VERSION "j1939-2025-03-v2.4-light"

NS_ :

BS_:

BU_:

BO_ 2163223550 CN: 8 Vector__XXX
 SG_ CrashChecksum : 60|4@1+ (1,0) [0|15] "count" Vector__XXX
 SG_ CrashCounter : 56|4@1+ (1,0) [0|15] "count" Vector__XXX
 SG_ CrashType : 0|5@1+ (1,0) [0|31] "" Vector__XXX

BO_ 2230333950 WAND: 8 Vector__XXX
 SG_ WandAngle : 0|16@1+ (0.002,-64) [-64|64.51] "deg" Vector__XXX
 SG_ WandSensorFigureOfMerit : 16|2@1+ (1,0) [0|3] "" Vector__XXX

BO_ 2230334206 LDISP: 8 Vector__XXX
 SG_ MeasuredLinearDisplacement : 0|16@1+ (0.1,0) [0|6425.5] "mm" Vector__XXX
 SG_ LnrDsplmntSnsrSnsrFgrOfMrt : 16|2@1+ (1,0) [0|3] "" Vector__XXX

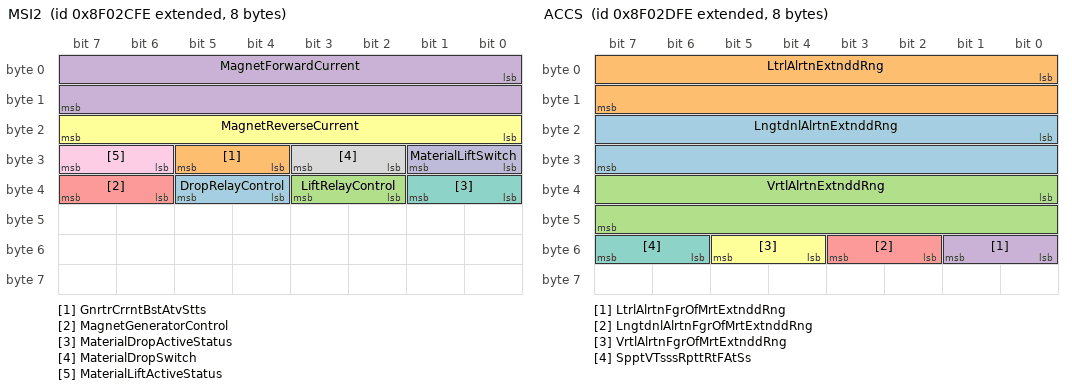
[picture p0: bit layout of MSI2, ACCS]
BO_ 2297441534 MSI2: 8 Vector__XXX
 SG_ DropRelayControl : 36|2@1+ (1,0) [0|3] "" Vector__XXX
 SG_ GnrtrCrrntBstAtvStts : 28|2@1+ (1,0) [0|3] "" Vector__XXX
 SG_ LiftRelayControl : 34|2@1+ (1,0) [0|3] "" Vector__XXX
 SG_ MagnetForwardCurrent : 0|16@1+ (1,0) [0|64255] "A" Vector__XXX
 SG_ MagnetGeneratorControl : 38|2@1+ (1,0) [0|3] "" Vector__XXX
 SG_ MagnetReverseCurrent : 16|8@1+ (1,0) [0|250] "A" Vector__XXX
 SG_ MaterialDropActiveStatus : 32|2@1+ (1,0) [0|3] "" Vector__XXX
 SG_ MaterialDropSwitch : 26|2@1+ (1,0) [0|3] "" Vector__XXX
 SG_ MaterialLiftActiveStatus : 30|2@1+ (1,0) [0|3] "" Vector__XXX
 SG_ MaterialLiftSwitch : 24|2@1+ (1,0) [0|3] "" Vector__XXX

BO_ 2297441790 ACCS: 8 Vector__XXX
 SG_ LngtdnlAlrtnExtnddRng : 16|16@1+ (0.01,-320) [-320|322.55] "m/(s*s)" Vector__XXX
 SG_ LtrlAlrtnExtnddRng : 0|16@1+ (0.01,-320) [-320|322.55] "m/(s*s)" Vector__XXX
 SG_ VrtlAlrtnExtnddRng : 32|16@1+ (0.01,-320) [-320|322.55] "m/(s*s)" Vector__XXX
 SG_ LtrlAlrtnFgrOfMrtExtnddRng : 48|2@1+ (1,0) [0|3] "" Vector__XXX
 SG_ LngtdnlAlrtnFgrOfMrtExtnddRng : 50|2@1+ (1,0) [0|3] "" Vector__XXX
 SG_ VrtlAlrtnFgrOfMrtExtnddRng : 52|2@1+ (1,0) [0|3] "" Vector__XXX
 SG_ SpptVTsssRpttRtFAtSs : 54|2@1+ (1,0) [0|3] "" Vector__XXX

BO_ 2297455358 ETC12: 8 Vector__XXX
 SG_ TrnsmssnDrtnlOtptShftSpd : 32|16@1+ (1,-32127) [-32127|32128] "rpm" Vector__XXX
 SG_ TrnsmssnHdrsttLp1Prssr : 0|16@1+ (1,0) [0|64255] "kPa" Vector__XXX
 SG_ TrnsmssnHdrsttLp2Prssr : 16|16@1+ (1,0) [0|64255] "kPa" Vector__XXX
 SG_ TrnsmssnIntrmdtShftSpd : 48|16@1+ (0.125,0) [0|8031.875] "rpm" Vector__XXX

BO_ 2297499902 B2: 8 Vector__XXX
 SG_ BrakePedalSwitch2 : 16|2@1+ (1,0) [0|3] "" Vector__XXX
 SG_ DmnddBrkAppltnPrssr : 0|16@1+ (0.1,0) [0|6425.5] "kPa" Vector__XXX

BO_ 2298375934 HRW: 8 Vector__XXX
 SG_ FrontAxleLeftWheelSpeed : 0|16@1+ (0.00390625,0) [0|250.99609375] "km/h" Vector__XXX
 SG_ FrontAxleRightWheelSpeed : 16|16@1+ (0.00390625,0) [0|250.99609375] "km/h" Vector__XXX
 SG_ RearAxleLeftWheelSpeed : 32|16@1+ (0.00390625,0) [0|250.99609375] "km/h" Vector__XXX
 SG_ RearAxleRightWheelSpeed : 48|16@1+ (0.00390625,0) [0|250.99609375] "km/h" Vector__XXX

BO_ 2348941054 TC1: 8 Vector__XXX
 SG_ DisengageDrivelineRequest : 4|2@1+ (1,0) [0|3] "" Vector__XXX
 SG_ DsnggDffrntlLkRqstCntrl : 32|2@1+ (1,0) [0|3] "" Vector__XXX
 SG_ DsnggDffrntlLkRqstCntrlFrnt : 34|2@1+ (1,0) [0|3] "" Vector__XXX
 SG_ DsnggDffrntlLkRqstCntrlRr : 36|2@1+ (1,0) [0|3] "" Vector__XXX
 SG_ DsnggDffrntlLkRqstFrntAxl1 : 24|2@1+ (1,0) [0|3] "" Vector__XXX
 SG_ DsnggDffrntlLkRqstFrntAxl2 : 26|2@1+ (1,0) [0|3] "" Vector__XXX
 SG_ DsnggDffrntlLkRqstRrAxl1 : 28|2@1+ (1,0) [0|3] "" Vector__XXX
 SG_ DsnggDffrntlLkRqstRrAxl2 : 30|2@1+ (1,0) [0|3] "" Vector__XXX
 SG_ RequestedPercentClutchSlip : 8|8@1+ (0.4,0) [0|100] "%" Vector__XXX
 SG_ TransmissionMode1 : 40|2@1+ (1,0) [0|3] "" Vector__XXX
 SG_ TransmissionMode2 : 42|2@1+ (1,0) [0|3] "" Vector__XXX
 SG_ TransmissionMode3 : 44|2@1+ (1,0) [0|3] "" Vector__XXX
 SG_ TransmissionMode4 : 46|2@1+ (1,0) [0|3] "" Vector__XXX
 SG_ TransmissionMode5 : 56|2@1+ (1,0) [0|3] "" Vector__XXX
 SG_ TransmissionMode6 : 58|2@1+ (1,0) [0|3] "" Vector__XXX
 SG_ TransmissionMode7 : 60|2@1+ (1,0) [0|3] "" Vector__XXX
 SG_ TransmissionMode8 : 62|2@1+ (1,0) [0|3] "" Vector__XXX
 SG_ TransmissionRequestedGear : 16|8@1+ (1,-125) [-64|64] "gear value" Vector__XXX
 SG_ TransmissionRequestedLaunchGear : 50|4@1+ (1,0) [0|15] "" Vector__XXX
 SG_ TrnsmssnAtNtrlMnlRtrnRqst : 48|2@1+ (1,0) [0|3] "" Vector__XXX
 SG_ TrnsmssnGrShftInhtRqst : 0|2@1+ (1,0) [0|3] "" Vector__XXX
 SG_ TrnsmssnLdRdtnInhtRqst : 38|2@1+ (1,0) [0|3] "" Vector__XXX
 SG_ TrnsmssnRvrsGrShftInhtRqst : 6|2@1+ (1,0) [0|3] "" Vector__XXX
 SG_ TrnsmssnShftSltrDsplMdSwth : 54|2@1+ (1,0) [0|3] "" Vector__XXX
 SG_ TrnsmssnTrqCnvrtrLkpRqst : 2|2@1+ (1,0) [0|3] "" Vector__XXX

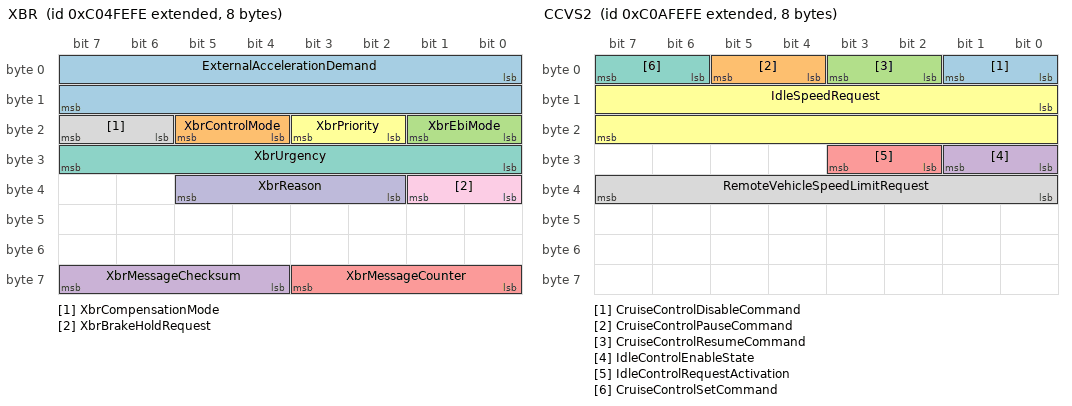
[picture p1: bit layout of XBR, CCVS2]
BO_ 2349137662 XBR: 8 Vector__XXX
 SG_ ExternalAccelerationDemand : 0|16@1+ (0.00048828125,-15.687) [-10|10] "m/(s*s)" Vector__XXX
 SG_ XbrControlMode : 20|2@1+ (1,0) [0|3] "" Vector__XXX
 SG_ XbrEbiMode : 16|2@1+ (1,0) [0|3] "" Vector__XXX
 SG_ XbrMessageChecksum : 60|4@1+ (1,0) [0|15] "count" Vector__XXX
 SG_ XbrMessageCounter : 56|4@1+ (1,0) [0|15] "count" Vector__XXX
 SG_ XbrPriority : 18|2@1+ (1,0) [0|3] "" Vector__XXX
 SG_ XbrUrgency : 24|8@1+ (0.4,0) [0|100] "%" Vector__XXX
 SG_ XbrCompensationMode : 22|2@1+ (1,0) [0|3] "" Vector__XXX
 SG_ XbrBrakeHoldRequest : 32|2@1+ (1,0) [0|3] "" Vector__XXX
 SG_ XbrReason : 34|4@1+ (1,0) [0|15] "" Vector__XXX

BO_ 2349399806 AUXIO5: 8 Vector__XXX
 SG_ AuxiliaryIOChannel3 : 48|16@1+ (1,0) [0|64255] "count" Vector__XXX
 SG_ AuxiliaryIOChannel4 : 32|16@1+ (1,0) [0|64255] "count" Vector__XXX
 SG_ AuxiliaryIOChannel5 : 16|16@1+ (1,0) [0|64255] "count" Vector__XXX
 SG_ AuxiliaryIOChannel6 : 0|16@1+ (1,0) [0|64255] "count" Vector__XXX

BO_ 2349465342 SRASI: 8 Vector__XXX
 SG_ StaticRollAngle : 0|8@1+ (1,-125) [-90|90] "deg" Vector__XXX
 SG_ StaticRollAngleStatus : 8|3@1+ (1,0) [0|7] "" Vector__XXX

BO_ 2349530878 CCVS2: 8 Vector__XXX
 SG_ CruiseControlDisableCommand : 0|2@1+ (1,0) [0|3] "" Vector__XXX
 SG_ CruiseControlPauseCommand : 4|2@1+ (1,0) [0|3] "" Vector__XXX
 SG_ CruiseControlResumeCommand : 2|2@1+ (1,0) [0|3] "" Vector__XXX
 SG_ IdleControlEnableState : 24|2@1+ (1,0) [0|3] "" Vector__XXX
 SG_ IdleControlRequestActivation : 26|2@1+ (1,0) [0|3] "" Vector__XXX
 SG_ IdleSpeedRequest : 8|16@1+ (0.125,0) [0|8031.875] "rpm" Vector__XXX
 SG_ CruiseControlSetCommand : 6|2@1+ (1,0) [0|3] "" Vector__XXX
 SG_ RemoteVehicleSpeedLimitRequest : 32|8@1+ (1,0) [0|250] "km/h" Vector__XXX

BO_ 2349596414 AEBS2: 8 Vector__XXX
 SG_ Aebs2MessageChecksum : 60|4@1+ (1,0) [0|15] "count" Vector__XXX
 SG_ Aebs2MessageCounter : 56|4@1+ (1,0) [0|15] "count" Vector__XXX
 SG_ DvAtvtDdFAdvdEBSst : 0|2@1+ (1,0) [0|3] "" Vector__XXX

BO_ 2349727486 TC2: 8 Vector__XXX
 SG_ TransmissionMode10 : 2|2@1+ (1,0) [0|3] "" Vector__XXX
 SG_ TransmissionMode9 : 0|2@1+ (1,0) [0|3] "" Vector__XXX
 SG_ TrnsmssnPrDfndMxmmGrAtvtnRqst : 4|2@1+ (1,0) [0|3] "" Vector__XXX
 SG_ TrnsmssnOtptShftBrkRqst : 6|2@1+ (1,0) [0|3] "" Vector__XXX
 SG_ TrnsmssnRqstdRvrsLnhGr : 8|4@1+ (1,0) [0|15] "" Vector__XXX
 SG_ SltdMxmmGrLmtAtvtnRqst : 12|2@1+ (1,0) [0|3] "" Vector__XXX
 SG_ TransmissionMode11 : 14|2@1+ (1,0) [0|3] "" Vector__XXX
 SG_ TransmissionMode12 : 16|2@1+ (1,0) [0|3] "" Vector__XXX
 SG_ TransmissionMode13 : 18|2@1+ (1,0) [0|3] "" Vector__XXX
 SG_ TransmissionMode14 : 20|2@1+ (1,0) [0|3] "" Vector__XXX
 SG_ TransmissionMode15 : 22|2@1+ (1,0) [0|3] "" Vector__XXX
 SG_ TransmissionMode16 : 24|2@1+ (1,0) [0|3] "" Vector__XXX
 SG_ TransmissionMode17 : 26|2@1+ (1,0) [0|3] "" Vector__XXX
 SG_ TransmissionMode18 : 28|2@1+ (1,0) [0|3] "" Vector__XXX
 SG_ TransmissionMode19 : 30|2@1+ (1,0) [0|3] "" Vector__XXX
 SG_ TransmissionMode20 : 32|2@1+ (1,0) [0|3] "" Vector__XXX
 SG_ DsnggDffrntlLkRqstRrAxl3 : 34|2@1+ (1,0) [0|3] "" Vector__XXX
 SG_ TrnsmssnCstMdDslRqst : 36|2@1+ (1,0) [0|3] "" Vector__XXX
 SG_ TrnsmssnExpltMnlMdRqst : 38|2@1+ (1,0) [0|3] "" Vector__XXX

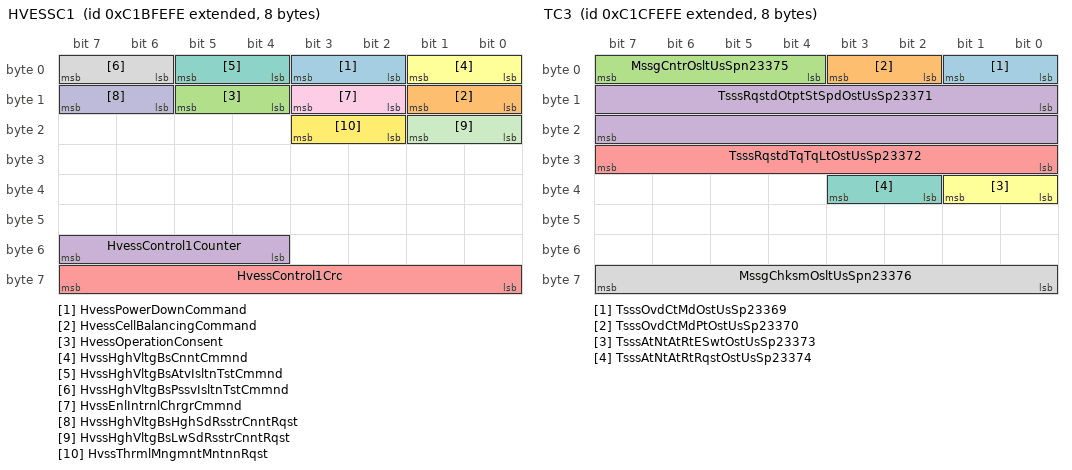
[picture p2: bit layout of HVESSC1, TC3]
BO_ 2350644990 HVESSC1: 8 Vector__XXX
 SG_ HvessPowerDownCommand : 2|2@1+ (1,0) [0|3] "" Vector__XXX
 SG_ HvessCellBalancingCommand : 8|2@1+ (1,0) [0|3] "" Vector__XXX
 SG_ HvessOperationConsent : 12|2@1+ (1,0) [0|3] "" Vector__XXX
 SG_ HvessControl1Counter : 52|4@1+ (1,0) [0|15] "" Vector__XXX
 SG_ HvessControl1Crc : 56|8@1+ (1,0) [0|250] "count" Vector__XXX
 SG_ HvssHghVltgBsCnntCmmnd : 0|2@1+ (1,0) [0|3] "" Vector__XXX
 SG_ HvssHghVltgBsAtvIsltnTstCmmnd : 4|2@1+ (1,0) [0|3] "" Vector__XXX
 SG_ HvssHghVltgBsPssvIsltnTstCmmnd : 6|2@1+ (1,0) [0|3] "" Vector__XXX
 SG_ HvssEnlIntrnlChrgrCmmnd : 10|2@1+ (1,0) [0|3] "" Vector__XXX
 SG_ HvssHghVltgBsHghSdRsstrCnntRqst : 14|2@1+ (1,0) [0|3] "" Vector__XXX
 SG_ HvssHghVltgBsLwSdRsstrCnntRqst : 16|2@1+ (1,0) [0|3] "" Vector__XXX
 SG_ HvssThrmlMngmntMntnnRqst : 18|2@1+ (1,0) [0|3] "" Vector__XXX

BO_ 2350710526 TC3: 8 Vector__XXX
 SG_ TsssOvdCtMdOstUsSp23369 : 0|2@1+ (1,0) [0|3] "" Vector__XXX
 SG_ TsssOvdCtMdPtOstUsSp23370 : 2|2@1+ (1,0) [0|3] "" Vector__XXX
 SG_ MssgCntrOsltUsSpn23375 : 4|4@1+ (1,0) [0|15] "count" Vector__XXX
 SG_ TsssRqstdOtptStSpdOstUsSp23371 : 8|16@1+ (0.25,-8031.75) [-8031.375|8031.75] "rpm" Vector__XXX
 SG_ TsssRqstdTqTqLtOstUsSp23372 : 24|8@1+ (1,-125) [-125|125] "%" Vector__XXX
 SG_ TsssAtNtAtRtESwtOstUsSp23373 : 32|2@1+ (1,0) [0|3] "" Vector__XXX
 SG_ TsssAtNtAtRtRqstOstUsSp23374 : 34|2@1+ (1,0) [0|3] "" Vector__XXX
 SG_ MssgChksmOsltUsSpn23376 : 56|8@1+ (1,0) [0|250] "count" Vector__XXX

BO_ 2350776062 EIC: 8 Vector__XXX
 SG_ EngineTimingAdvance : 0|16@1+ (0.0078125,-200) [-200|301.9921875] "deg" Vector__XXX

BO_ 2350841598 ALTC: 8 Vector__XXX
 SG_ AlternatorTorqueRampTimeCommand : 24|8@1+ (0.1,0) [0.1|25] "s" Vector__XXX
 SG_ AltrntrExttnMxmmCrrntLmt : 16|8@1+ (0.25,0) [0|62.5] "A" Vector__XXX
 SG_ AltrntrStpntVltgCmmnd : 0|16@1+ (0.001,0) [0|64.255] "V" Vector__XXX
 SG_ AltrntrTrqRmpMxmmSpdCmmnd : 32|8@1+ (32,0) [0|8000] "rpm" Vector__XXX

BO_ 2358902526 JLCM: 8 Vector__XXX
 SG_ Joystick1Lamp10Command : 18|2@1+ (1,0) [0|3] "" Vector__XXX
 SG_ Joystick1Lamp1Command : 0|2@1+ (1,0) [0|3] "" Vector__XXX
 SG_ Joystick1Lamp2Command : 2|2@1+ (1,0) [0|3] "" Vector__XXX
 SG_ Joystick1Lamp3Command : 4|2@1+ (1,0) [0|3] "" Vector__XXX
 SG_ Joystick1Lamp4Command : 6|2@1+ (1,0) [0|3] "" Vector__XXX
 SG_ Joystick1Lamp5Command : 8|2@1+ (1,0) [0|3] "" Vector__XXX
 SG_ Joystick1Lamp6Command : 10|2@1+ (1,0) [0|3] "" Vector__XXX
 SG_ Joystick1Lamp7Command : 12|2@1+ (1,0) [0|3] "" Vector__XXX
 SG_ Joystick1Lamp8Command : 14|2@1+ (1,0) [0|3] "" Vector__XXX
 SG_ Joystick1Lamp9Command : 16|2@1+ (1,0) [0|3] "" Vector__XXX
 SG_ Joystick2Lamp10Command : 38|2@1+ (1,0) [0|3] "" Vector__XXX
 SG_ Joystick2Lamp1Command : 20|2@1+ (1,0) [0|3] "" Vector__XXX
 SG_ Joystick2Lamp2Command : 22|2@1+ (1,0) [0|3] "" Vector__XXX
 SG_ Joystick2Lamp3Command : 24|2@1+ (1,0) [0|3] "" Vector__XXX
 SG_ Joystick2Lamp4Command : 26|2@1+ (1,0) [0|3] "" Vector__XXX
 SG_ Joystick2Lamp5Command : 28|2@1+ (1,0) [0|3] "" Vector__XXX
 SG_ Joystick2Lamp6Command : 30|2@1+ (1,0) [0|3] "" Vector__XXX
 SG_ Joystick2Lamp7Command : 32|2@1+ (1,0) [0|3] "" Vector__XXX
 SG_ Joystick2Lamp8Command : 34|2@1+ (1,0) [0|3] "" Vector__XXX
 SG_ Joystick2Lamp9Command : 36|2@1+ (1,0) [0|3] "" Vector__XXX
 SG_ Joystick3Lamp10Command : 58|2@1+ (1,0) [0|3] "" Vector__XXX
 SG_ Joystick3Lamp1Command : 40|2@1+ (1,0) [0|3] "" Vector__XXX
 SG_ Joystick3Lamp2Command : 42|2@1+ (1,0) [0|3] "" Vector__XXX
 SG_ Joystick3Lamp3Command : 44|2@1+ (1,0) [0|3] "" Vector__XXX
 SG_ Joystick3Lamp4Command : 46|2@1+ (1,0) [0|3] "" Vector__XXX
 SG_ Joystick3Lamp5Command : 48|2@1+ (1,0) [0|3] "" Vector__XXX
 SG_ Joystick3Lamp6Command : 50|2@1+ (1,0) [0|3] "" Vector__XXX
 SG_ Joystick3Lamp7Command : 52|2@1+ (1,0) [0|3] "" Vector__XXX
 SG_ Joystick3Lamp8Command : 54|2@1+ (1,0) [0|3] "" Vector__XXX
 SG_ Joystick3Lamp9Command : 56|2@1+ (1,0) [0|3] "" Vector__XXX

BO_ 2362572542 ASC6: 8 Vector__XXX
 SG_ LevelPresetFrontAxleLeft : 0|16@1+ (0.1,-3200) [-3200|3225.5] "mm" Vector__XXX
 SG_ LevelPresetFrontAxleRight : 16|16@1+ (0.1,-3200) [-3200|3225.5] "mm" Vector__XXX
 SG_ LevelPresetRearAxleLeft : 32|16@1+ (0.1,-3200) [-3200|3225.5] "mm" Vector__XXX
 SG_ LevelPresetRearAxleRight : 48|16@1+ (0.1,-3200) [-3200|3225.5] "mm" Vector__XXX

BO_ 2362638078 ASC2: 8 Vector__XXX
 SG_ AllwLvlCntrlDrngBrkngCmmnd : 54|2@1+ (1,0) [0|3] "" Vector__XXX
 SG_ AtmtTrtnHlpLdTrnsfr : 0|2@1+ (1,0) [0|3] "" Vector__XXX
 SG_ DamperStiffnessRequestFrontAxle : 24|8@1+ (0.4,0) [0|100] "%" Vector__XXX
 SG_ DamperStiffnessRequestRearAxle : 32|8@1+ (0.4,0) [0|100] "%" Vector__XXX
 SG_ DmprStffnssRqstLftTgAxl : 40|8@1+ (0.4,0) [0|100] "%" Vector__XXX
 SG_ KneelingCommandFrontAxle : 48|2@1+ (1,0) [0|3] "" Vector__XXX
 SG_ KneelingCommandRearAxle : 50|2@1+ (1,0) [0|3] "" Vector__XXX
 SG_ KneelingControlModeRequest : 6|2@1+ (1,0) [0|3] "" Vector__XXX
 SG_ KneelingRequestLeftSide : 2|2@1+ (1,0) [0|3] "" Vector__XXX
 SG_ KneelingRequestRightSide : 4|2@1+ (1,0) [0|3] "" Vector__XXX
 SG_ LevelControlModeRequest : 16|4@1+ (1,0) [0|15] "" Vector__XXX
 SG_ LiftAxle1PositionCommand : 20|2@1+ (1,0) [0|3] "" Vector__XXX
 SG_ LiftAxle2PositionCommand : 22|2@1+ (1,0) [0|3] "" Vector__XXX
 SG_ MemoryLevelRequest : 60|4@1+ (1,0) [0|15] "" Vector__XXX
 SG_ NominalLevelRequestFrontAxle : 8|4@1+ (1,0) [0|15] "" Vector__XXX
 SG_ NominalLevelRequestRearAxle : 12|4@1+ (1,0) [0|15] "" Vector__XXX
 SG_ PrhtAtmtArSspnsnCntrl : 58|2@1+ (1,0) [0|3] "" Vector__XXX
 SG_ ProhibitAirSuspensionControl : 52|2@1+ (1,0) [0|3] "" Vector__XXX
 SG_ SpdDpndntLvlCntrlRqst : 56|2@1+ (1,0) [0|3] "" Vector__XXX

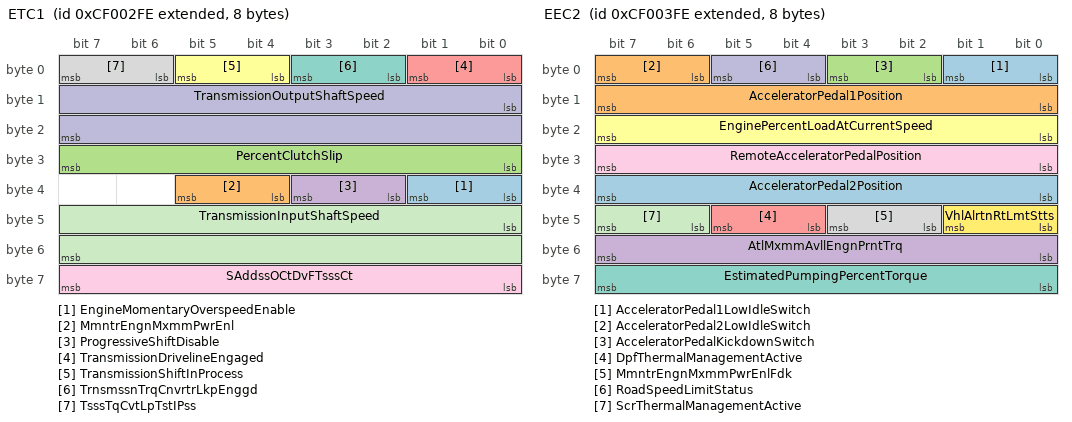
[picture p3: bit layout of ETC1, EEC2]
BO_ 2364539646 ETC1: 8 Vector__XXX
 SG_ EngineMomentaryOverspeedEnable : 32|2@1+ (1,0) [0|3] "" Vector__XXX
 SG_ MmntrEngnMxmmPwrEnl : 36|2@1+ (1,0) [0|3] "" Vector__XXX
 SG_ PercentClutchSlip : 24|8@1+ (0.4,0) [0|100] "%" Vector__XXX
 SG_ ProgressiveShiftDisable : 34|2@1+ (1,0) [0|3] "" Vector__XXX
 SG_ TransmissionDrivelineEngaged : 0|2@1+ (1,0) [0|3] "" Vector__XXX
 SG_ TransmissionShiftInProcess : 4|2@1+ (1,0) [0|3] "" Vector__XXX
 SG_ TrnsmssnTrqCnvrtrLkpEnggd : 2|2@1+ (1,0) [0|3] "" Vector__XXX
 SG_ TsssTqCvtLpTstIPss : 6|2@1+ (1,0) [0|3] "" Vector__XXX
 SG_ SAddssOCtDvFTsssCt : 56|8@1+ (1,0) [0|253] "sourceadr" Vector__XXX
 SG_ TransmissionOutputShaftSpeed : 8|16@1+ (0.125,0) [0|8031.875] "rpm" Vector__XXX
 SG_ TransmissionInputShaftSpeed : 40|16@1+ (0.125,0) [0|8031.875] "rpm" Vector__XXX

BO_ 2364539902 EEC2: 8 Vector__XXX
 SG_ AcceleratorPedal1LowIdleSwitch : 0|2@1+ (1,0) [0|3] "" Vector__XXX
 SG_ AcceleratorPedal2LowIdleSwitch : 6|2@1+ (1,0) [0|3] "" Vector__XXX
 SG_ AcceleratorPedalKickdownSwitch : 2|2@1+ (1,0) [0|3] "" Vector__XXX
 SG_ AtlMxmmAvllEngnPrntTrq : 48|8@1+ (0.4,0) [0|100] "%" Vector__XXX
 SG_ DpfThermalManagementActive : 44|2@1+ (1,0) [0|3] "" Vector__XXX
 SG_ EnginePercentLoadAtCurrentSpeed : 16|8@1+ (1,0) [0|125] "%" Vector__XXX
 SG_ EstimatedPumpingPercentTorque : 56|8@1+ (1,-125) [-125|125] "%" Vector__XXX
 SG_ MmntrEngnMxmmPwrEnlFdk : 42|2@1+ (1,0) [0|3] "" Vector__XXX
 SG_ RemoteAcceleratorPedalPosition : 24|8@1+ (0.4,0) [0|100] "%" Vector__XXX
 SG_ RoadSpeedLimitStatus : 4|2@1+ (1,0) [0|3] "" Vector__XXX
 SG_ ScrThermalManagementActive : 46|2@1+ (1,0) [0|3] "" Vector__XXX
 SG_ VhlAlrtnRtLmtStts : 40|2@1+ (1,0) [0|3] "" Vector__XXX
 SG_ AcceleratorPedal2Position : 32|8@1+ (0.4,0) [0|100] "%" Vector__XXX
 SG_ AcceleratorPedal1Position : 8|8@1+ (0.4,0) [0|100] "%" Vector__XXX

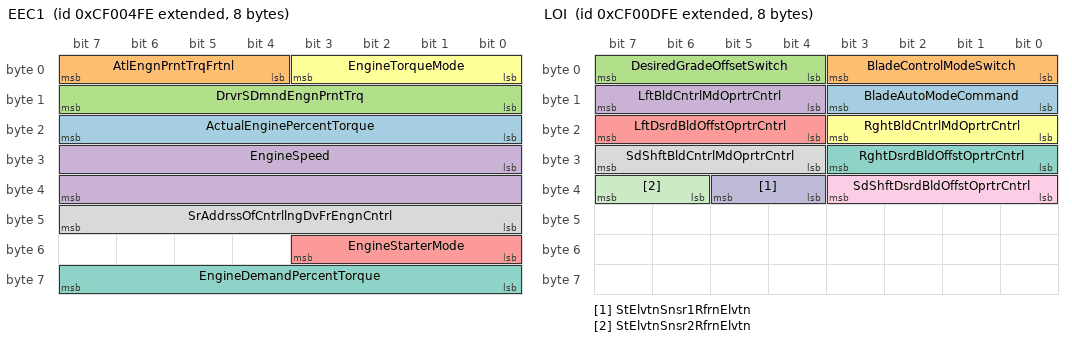
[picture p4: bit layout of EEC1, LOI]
BO_ 2364540158 EEC1: 8 Vector__XXX
 SG_ ActualEnginePercentTorque : 16|8@1+ (1,-125) [0|125] "%" Vector__XXX
 SG_ AtlEngnPrntTrqFrtnl : 4|4@1+ (0.125,0) [0|0.875] "%" Vector__XXX
 SG_ DrvrSDmndEngnPrntTrq : 8|8@1+ (1,-125) [0|125] "%" Vector__XXX
 SG_ EngineSpeed : 24|16@1+ (0.125,0) [0|8031.875] "rpm" Vector__XXX
 SG_ EngineStarterMode : 48|4@1+ (1,0) [0|15] "" Vector__XXX
 SG_ EngineTorqueMode : 0|4@1+ (1,0) [0|15] "" Vector__XXX
 SG_ EngineDemandPercentTorque : 56|8@1+ (1,-125) [-125|125] "%" Vector__XXX
 SG_ SrAddrssOfCntrllngDvFrEngnCntrl : 40|8@1+ (1,0) [0|253] "sourceadr" Vector__XXX

BO_ 2364541694 EGF1: 8 Vector__XXX
 SG_ EngineIntakeAirMassFlowRate : 16|16@1+ (0.05,0) [0|3212.75] "kg/h" Vector__XXX
 SG_ EngnExhstGsRrltn1MssFlwRt : 0|16@1+ (0.05,0) [0|3212.75] "kg/h" Vector__XXX
 SG_ EngnExhstGsRrltn2MssFlwRt : 32|16@1+ (0.05,0) [0|3212.75] "kg/h" Vector__XXX
 SG_ TargetFreshAirMassFlow : 48|16@1+ (0.05,0) [0|3212.75] "kg/h" Vector__XXX

BO_ 2364542206 ETC8: 8 Vector__XXX
 SG_ TrnsmssnClthCnvrtrInptSpd : 16|16@1+ (0.125,0) [0|8031.875] "rpm" Vector__XXX
 SG_ TrnsmssnTrqCnvrtrRt : 0|16@1+ (0.001,0) [0|64.255] "" Vector__XXX
 SG_ TransmissionShiftInhibitReason : 32|8@1+ (1,0) [0|250] "" Vector__XXX
 SG_ TrnsmssnTrqCnvrtrLkpInhtRsn : 40|8@1+ (1,0) [0|250] "" Vector__XXX
 SG_ TrnsmssnTrqCnvrtrLkpInhtIndtr : 48|2@1+ (1,0) [0|3] "" Vector__XXX
 SG_ TrnsmssnExpltMnlMdIndtr : 50|2@1+ (1,0) [0|3] "" Vector__XXX

BO_ 2364542462 LOI: 8 Vector__XXX
 SG_ BladeAutoModeCommand : 8|4@1+ (1,0) [0|15] "" Vector__XXX
 SG_ BladeControlModeSwitch : 0|4@1+ (1,0) [0|15] "" Vector__XXX
 SG_ DesiredGradeOffsetSwitch : 4|4@1+ (1,0) [0|15] "" Vector__XXX
 SG_ LftBldCntrlMdOprtrCntrl : 12|4@1+ (1,0) [0|15] "" Vector__XXX
 SG_ LftDsrdBldOffstOprtrCntrl : 20|4@1+ (1,0) [0|15] "" Vector__XXX
 SG_ RghtBldCntrlMdOprtrCntrl : 16|4@1+ (1,0) [0|15] "" Vector__XXX
 SG_ RghtDsrdBldOffstOprtrCntrl : 24|4@1+ (1,0) [0|15] "" Vector__XXX
 SG_ SdShftBldCntrlMdOprtrCntrl : 28|4@1+ (1,0) [0|15] "" Vector__XXX
 SG_ SdShftDsrdBldOffstOprtrCntrl : 32|4@1+ (1,0) [0|15] "" Vector__XXX
 SG_ StElvtnSnsr1RfrnElvtn : 36|2@1+ (1,0) [0|3] "" Vector__XXX
 SG_ StElvtnSnsr2RfrnElvtn : 38|2@1+ (1,0) [0|3] "" Vector__XXX

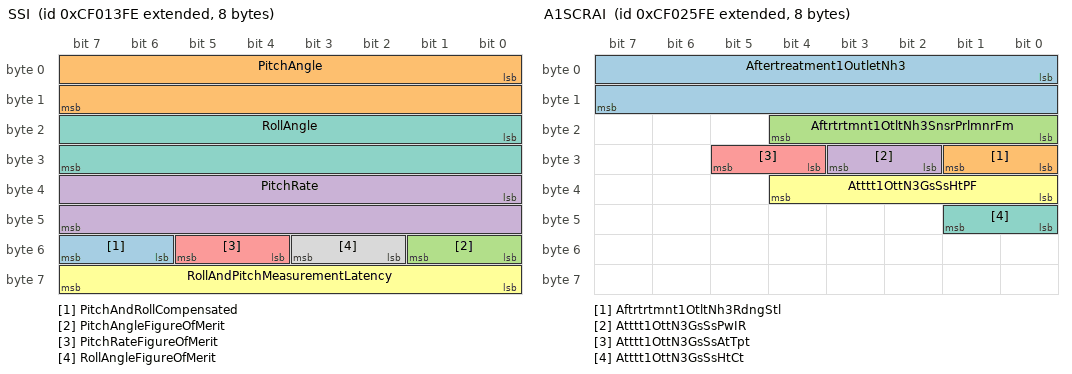
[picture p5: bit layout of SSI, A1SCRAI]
BO_ 2364543998 SSI: 8 Vector__XXX
 SG_ PitchAndRollCompensated : 54|2@1+ (1,0) [0|3] "" Vector__XXX
 SG_ PitchAngle : 0|16@1+ (0.002,-64) [-64|64.51] "deg" Vector__XXX
 SG_ PitchAngleFigureOfMerit : 48|2@1+ (1,0) [0|3] "" Vector__XXX
 SG_ PitchRate : 32|16@1+ (0.002,-64) [-64|64.51] "deg/s" Vector__XXX
 SG_ PitchRateFigureOfMerit : 52|2@1+ (1,0) [0|3] "" Vector__XXX
 SG_ RollAndPitchMeasurementLatency : 56|8@1+ (0.5,0) [0|125] "ms" Vector__XXX
 SG_ RollAngle : 16|16@1+ (0.002,-64) [-64|64.51] "deg" Vector__XXX
 SG_ RollAngleFigureOfMerit : 50|2@1+ (1,0) [0|3] "" Vector__XXX

BO_ 2364544254 BI: 8 Vector__XXX
 SG_ BladeRotationAngle : 16|16@1+ (0.0078125,-200) [-200|301.9921875] "deg" Vector__XXX
 SG_ BladeRotationAngleFigureOfMerit : 42|2@1+ (1,0) [0|3] "" Vector__XXX
 SG_ RelativeBladeHeight : 0|16@1+ (0.1,-3200) [-3200|3225.5] "mm" Vector__XXX
 SG_ RtvBdHtAdBdRttAMstLt : 32|8@1+ (0.5,0) [0|125] "ms" Vector__XXX
 SG_ RltvBldHghtFgrOfMrt : 40|2@1+ (1,0) [0|3] "" Vector__XXX

BO_ 2364544510 RGTACRP: 8 Vector__XXX
 SG_ RqstdGnrtrOvrllPwrFtr : 32|16@1+ (0.00006103515625,-1) [-1|1] "" Vector__XXX
 SG_ RqstdGnrtrOvrllPwrFtrLggng : 48|2@1+ (1,0) [0|3] "" Vector__XXX
 SG_ RqstdGnrtrTtlARtvPwr : 0|32@1+ (1,-2000000000) [-2000000000|2211081215] "VA" Vector__XXX

BO_ 2364544766 CCS: 8 Vector__XXX
 SG_ EngineCylinder1CombustionStatus : 0|2@1+ (1,0) [0|3] "" Vector__XXX
 SG_ EngineCylinder2CombustionStatus : 2|2@1+ (1,0) [0|3] "" Vector__XXX
 SG_ EngineCylinder3CombustionStatus : 4|2@1+ (1,0) [0|3] "" Vector__XXX
 SG_ EngineCylinder4CombustionStatus : 6|2@1+ (1,0) [0|3] "" Vector__XXX
 SG_ EngineCylinder5CombustionStatus : 8|2@1+ (1,0) [0|3] "" Vector__XXX
 SG_ EngineCylinder6CombustionStatus : 10|2@1+ (1,0) [0|3] "" Vector__XXX
 SG_ EngineCylinder7CombustionStatus : 12|2@1+ (1,0) [0|3] "" Vector__XXX
 SG_ EngineCylinder8CombustionStatus : 14|2@1+ (1,0) [0|3] "" Vector__XXX
 SG_ EngineCylinder9CombustionStatus : 16|2@1+ (1,0) [0|3] "" Vector__XXX
 SG_ EngnClndr10CmstnStts : 18|2@1+ (1,0) [0|3] "" Vector__XXX
 SG_ EngnClndr11CmstnStts : 20|2@1+ (1,0) [0|3] "" Vector__XXX
 SG_ EngnClndr12CmstnStts : 22|2@1+ (1,0) [0|3] "" Vector__XXX
 SG_ EngnClndr13CmstnStts : 24|2@1+ (1,0) [0|3] "" Vector__XXX
 SG_ EngnClndr14CmstnStts : 26|2@1+ (1,0) [0|3] "" Vector__XXX
 SG_ EngnClndr15CmstnStts : 28|2@1+ (1,0) [0|3] "" Vector__XXX
 SG_ EngnClndr16CmstnStts : 30|2@1+ (1,0) [0|3] "" Vector__XXX
 SG_ EngnClndr17CmstnStts : 32|2@1+ (1,0) [0|3] "" Vector__XXX
 SG_ EngnClndr18CmstnStts : 34|2@1+ (1,0) [0|3] "" Vector__XXX
 SG_ EngnClndr19CmstnStts : 36|2@1+ (1,0) [0|3] "" Vector__XXX
 SG_ EngnClndr20CmstnStts : 38|2@1+ (1,0) [0|3] "" Vector__XXX
 SG_ EngnClndr21CmstnStts : 40|2@1+ (1,0) [0|3] "" Vector__XXX
 SG_ EngnClndr22CmstnStts : 42|2@1+ (1,0) [0|3] "" Vector__XXX
 SG_ EngnClndr23CmstnStts : 44|2@1+ (1,0) [0|3] "" Vector__XXX
 SG_ EngnClndr24CmstnStts : 46|2@1+ (1,0) [0|3] "" Vector__XXX

BO_ 2364545022 KL1: 8 Vector__XXX
 SG_ EngineCylinder1KnockLevel : 0|8@1+ (1,0) [0|100] "%" Vector__XXX
 SG_ EngineCylinder2KnockLevel : 8|8@1+ (1,0) [0|250] "%" Vector__XXX
 SG_ EngineCylinder3KnockLevel : 16|8@1+ (1,0) [0|250] "%" Vector__XXX
 SG_ EngineCylinder4KnockLevel : 24|8@1+ (1,0) [0|250] "%" Vector__XXX
 SG_ EngineCylinder5KnockLevel : 32|8@1+ (1,0) [0|250] "%" Vector__XXX
 SG_ EngineCylinder6KnockLevel : 40|8@1+ (1,0) [0|250] "%" Vector__XXX
 SG_ EngineCylinder7KnockLevel : 48|8@1+ (1,0) [0|250] "%" Vector__XXX
 SG_ EngineCylinder8KnockLevel : 56|8@1+ (1,0) [0|250] "%" Vector__XXX

BO_ 2364545278 KL2: 8 Vector__XXX
 SG_ EngineCylinder10KnockLevel : 8|8@1+ (1,0) [0|250] "%" Vector__XXX
 SG_ EngineCylinder11KnockLevel : 16|8@1+ (1,0) [0|250] "%" Vector__XXX
 SG_ EngineCylinder12KnockLevel : 24|8@1+ (1,0) [0|250] "%" Vector__XXX
 SG_ EngineCylinder13KnockLevel : 32|8@1+ (1,0) [0|250] "%" Vector__XXX
 SG_ EngineCylinder14KnockLevel : 40|8@1+ (1,0) [0|250] "%" Vector__XXX
 SG_ EngineCylinder15KnockLevel : 48|8@1+ (1,0) [0|250] "%" Vector__XXX
 SG_ EngineCylinder16KnockLevel : 56|8@1+ (1,0) [0|250] "%" Vector__XXX
 SG_ EngineCylinder9KnockLevel : 0|8@1+ (1,0) [0|250] "%" Vector__XXX

BO_ 2364545534 KL3: 8 Vector__XXX
 SG_ EngineCylinder17KnockLevel : 0|8@1+ (1,0) [0|250] "%" Vector__XXX
 SG_ EngineCylinder18KnockLevel : 8|8@1+ (1,0) [0|250] "%" Vector__XXX
 SG_ EngineCylinder19KnockLevel : 16|8@1+ (1,0) [0|250] "%" Vector__XXX
 SG_ EngineCylinder20KnockLevel : 24|8@1+ (1,0) [0|250] "%" Vector__XXX
 SG_ EngineCylinder21KnockLevel : 32|8@1+ (1,0) [0|250] "%" Vector__XXX
 SG_ EngineCylinder22KnockLevel : 40|8@1+ (1,0) [0|250] "%" Vector__XXX
 SG_ EngineCylinder23KnockLevel : 48|8@1+ (1,0) [0|250] "%" Vector__XXX
 SG_ EngineCylinder24KnockLevel : 56|8@1+ (1,0) [0|250] "%" Vector__XXX

BO_ 2364546302 RGAAC: 8 Vector__XXX
 SG_ RqstdGnrtrAvrgLnLnARmsVltg : 0|32@1+ (0.0078125,0) [0|32899071.9921875] "V" Vector__XXX

BO_ 2364546814 GC2: 8 Vector__XXX
 SG_ EngineLoadSetpointRequest : 24|16@1+ (0.5,0) [0|32127.5] "kW" Vector__XXX
 SG_ EngineSelfInducedDerateInhibit : 16|2@1+ (1,0) [0|3] "" Vector__XXX
 SG_ GeneratorGoverningBias : 0|16@1+ (0.004,-125) [-125|125] "%" Vector__XXX

BO_ 2364548094 A1SCRDSI1: 8 Vector__XXX
 SG_ Aftertreatment1ScrSystem1State : 16|4@1+ (1,0) [0|15] "" Vector__XXX
 SG_ Aftertreatment1ScrSystem2State : 20|4@1+ (1,0) [0|15] "" Vector__XXX
 SG_ Atttt1DsExstFdAtDsQtt : 0|16@1+ (0.3,0) [0|19276.5] "g/h" Vector__XXX
 SG_ Atttt1DsExstFdAtDsQttHR : 48|16@1+ (0.05,0) [0|3212.75] "g/min" Vector__XXX
 SG_ Atttt1DsExstFdDs1AstPss : 40|8@1+ (8,0) [0|2000] "kPa" Vector__XXX
 SG_ Atttt1DsExstFdAtQttOItt : 24|16@1+ (0.1,0) [0|6425.5] "g" Vector__XXX

BO_ 2364548350 A1SCRDSR1: 8 Vector__XXX
 SG_ Atttt1DsExstFdDsRqstdQtt : 0|16@1+ (0.3,0) [0|19276.5] "g/h" Vector__XXX
 SG_ Atttt1DsExstFdDsRqstdQttHR : 40|16@1+ (0.05,0) [0|3212.75] "g/min" Vector__XXX
 SG_ Atttt1DsExstFdDsTstItPssStts : 22|2@1+ (1,0) [0|3] "" Vector__XXX
 SG_ Atttt1DsExstFdHdStssCPssStts : 20|2@1+ (1,0) [0|3] "" Vector__XXX
 SG_ Aftrtrtmnt1SrSstmRqstdStt : 16|4@1+ (1,0) [0|15] "" Vector__XXX
 SG_ Atttt1DsExstFdRqstdQttOItt : 24|16@1+ (0.1,0) [0|6425.5] "g" Vector__XXX

BO_ 2364548606 A1SCRAI: 8 Vector__XXX
 SG_ Aftertreatment1OutletNh3 : 0|16@1+ (0.05,-200) [-200|3012.75] "ppm" Vector__XXX
 SG_ Aftrtrtmnt1OtltNh3RdngStl : 24|2@1+ (1,0) [0|3] "" Vector__XXX
 SG_ Aftrtrtmnt1OtltNh3SnsrPrlmnrFm : 16|5@1+ (1,0) [0|31] "" Vector__XXX
 SG_ Atttt1OttN3GsSsPwIR : 26|2@1+ (1,0) [0|3] "" Vector__XXX
 SG_ Atttt1OttN3GsSsAtTpt : 28|2@1+ (1,0) [0|3] "" Vector__XXX
 SG_ Atttt1OttN3GsSsHtPF : 32|5@1+ (1,0) [0|31] "" Vector__XXX
 SG_ Atttt1OttN3GsSsHtCt : 40|2@1+ (1,0) [0|3] "" Vector__XXX

BO_ 2364548862 A2SCRDSI1: 8 Vector__XXX
 SG_ Aftertreatment2ScrSystem1State : 16|4@1+ (1,0) [0|15] "" Vector__XXX
 SG_ Aftertreatment2ScrSystem2State : 20|4@1+ (1,0) [0|15] "" Vector__XXX
 SG_ Atttt2DsExstFdAtDsQtt : 0|16@1+ (0.3,0) [0|19276.5] "g/h" Vector__XXX
 SG_ Atttt2DsExstFdAtDsQttHR : 48|16@1+ (0.05,0) [0|3212.75] "g/min" Vector__XXX
 SG_ Atttt2DsExstFdDs1AstPss : 40|8@1+ (8,0) [0|2000] "kPa" Vector__XXX
 SG_ Atttt2DsExstFdAtQttOItt : 24|16@1+ (0.1,0) [0|6425.5] "g" Vector__XXX

BO_ 2364549118 A2SCRDSR1: 8 Vector__XXX
 SG_ Atttt2DsExstFdDsRqstdQtt : 0|16@1+ (0.3,0) [0|19276.5] "g/h" Vector__XXX
 SG_ Atttt2DsExstFdDsRqstdQttHR : 40|16@1+ (0.05,0) [0|3212.75] "g/min" Vector__XXX
 SG_ Atttt2DsExstFdDsTstItPssStts : 22|2@1+ (1,0) [0|3] "" Vector__XXX
 SG_ Atttt2DsExstFdHdStssCPssStts : 20|2@1+ (1,0) [0|3] "" Vector__XXX
 SG_ Atttt2DsExstFdPpHtCd : 56|8@1+ (0.4,0) [0|100] "%" Vector__XXX
 SG_ Aftrtrtmnt2SrSstmRqstdStt : 16|4@1+ (1,0) [0|15] "" Vector__XXX
 SG_ Atttt2DsExstFdRqstdQttOItt : 24|16@1+ (0.1,0) [0|6425.5] "g" Vector__XXX

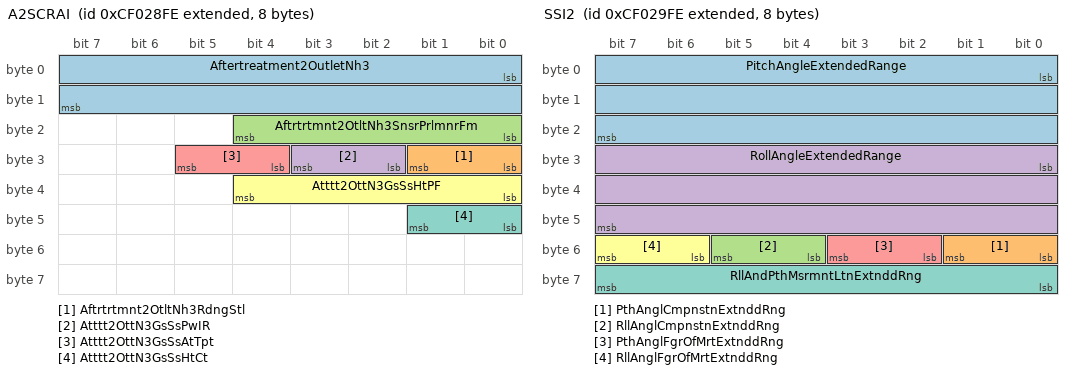
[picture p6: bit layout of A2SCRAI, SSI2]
BO_ 2364549374 A2SCRAI: 8 Vector__XXX
 SG_ Aftertreatment2OutletNh3 : 0|16@1+ (0.05,-200) [-200|3012.75] "ppm" Vector__XXX
 SG_ Aftrtrtmnt2OtltNh3RdngStl : 24|2@1+ (1,0) [0|3] "" Vector__XXX
 SG_ Aftrtrtmnt2OtltNh3SnsrPrlmnrFm : 16|5@1+ (1,0) [0|31] "" Vector__XXX
 SG_ Atttt2OttN3GsSsPwIR : 26|2@1+ (1,0) [0|3] "" Vector__XXX
 SG_ Atttt2OttN3GsSsAtTpt : 28|2@1+ (1,0) [0|3] "" Vector__XXX
 SG_ Atttt2OttN3GsSsHtPF : 32|5@1+ (1,0) [0|31] "" Vector__XXX
 SG_ Atttt2OttN3GsSsHtCt : 40|2@1+ (1,0) [0|3] "" Vector__XXX

BO_ 2364549630 SSI2: 8 Vector__XXX
 SG_ PitchAngleExtendedRange : 0|24@1+ (0.000030517578125,-250) [-250|251.999969482421] "deg" Vector__XXX
 SG_ PthAnglCmpnstnExtnddRng : 48|2@1+ (1,0) [0|3] "" Vector__XXX
 SG_ RllAnglCmpnstnExtnddRng : 52|2@1+ (1,0) [0|3] "" Vector__XXX
 SG_ RollAngleExtendedRange : 24|24@1+ (0.000030517578125,-250) [-250|251.999969482421] "deg" Vector__XXX
 SG_ PthAnglFgrOfMrtExtnddRng : 50|2@1+ (1,0) [0|3] "" Vector__XXX
 SG_ RllAnglFgrOfMrtExtnddRng : 54|2@1+ (1,0) [0|3] "" Vector__XXX
 SG_ RllAndPthMsrmntLtnExtnddRng : 56|8@1+ (0.5,0) [0|125] "ms" Vector__XXX

BO_ 2364549886 ARI: 8 Vector__XXX
 SG_ AngularRateMeasurementLatency : 56|8@1+ (0.5,0) [0|125] "ms" Vector__XXX
 SG_ PitchRateExtendedRange : 0|16@1+ (0.0078125,-250) [-250|251.9921875] "deg/s" Vector__XXX
 SG_ RollRateExtendedRange : 16|16@1+ (0.0078125,-250) [-250|251.9921875] "deg/s" Vector__XXX
 SG_ YawRateExtendedRange : 32|16@1+ (0.0078125,-250) [-250|251.9921875] "deg/s" Vector__XXX
 SG_ PthRtFgrOfMrtExtnddRng : 48|2@1+ (1,0) [0|3] "" Vector__XXX
 SG_ RllRtFgrOfMrtExtnddRng : 50|2@1+ (1,0) [0|3] "" Vector__XXX
 SG_ YwRtFgrOfMrtExtnddRng : 52|2@1+ (1,0) [0|3] "" Vector__XXX

BO_ 2364551166 AEBS1: 8 Vector__XXX
 SG_ CollisionWarningLevel : 4|4@1+ (1,0) [0|15] "" Vector__XXX
 SG_ FwdCsAdvdEBSstStt : 0|4@1+ (1,0) [0|15] "" Vector__XXX
 SG_ RdDprtrAdvndEmrgnBrkngSstmStt : 24|4@1+ (1,0) [0|15] "" Vector__XXX
 SG_ RvtOtDttdFAdvdEBSst : 8|3@1+ (1,0) [0|7] "" Vector__XXX
 SG_ BndOffPrltOfRlvntOjt : 11|3@1+ (1,0) [0|7] "" Vector__XXX
 SG_ TmTCllsnWthRlvntOjt : 16|8@1+ (0.05,0) [0|12.5] "s" Vector__XXX

BO_ 2364551422 WS: 8 Vector__XXX
 SG_ TransmitterCommandState : 20|4@1+ (1,0) [0|15] "" Vector__XXX
 SG_ TransmitterId1 : 24|24@1+ (1,0) [0|16449535] "ID" Vector__XXX
 SG_ WirelessRollingMessageCounter : 0|16@1+ (1,0) [0|64255] "count" Vector__XXX
 SG_ WirelessSignalStrength1 : 48|8@1+ (0.5,-125) [-125|0] "dBm" Vector__XXX

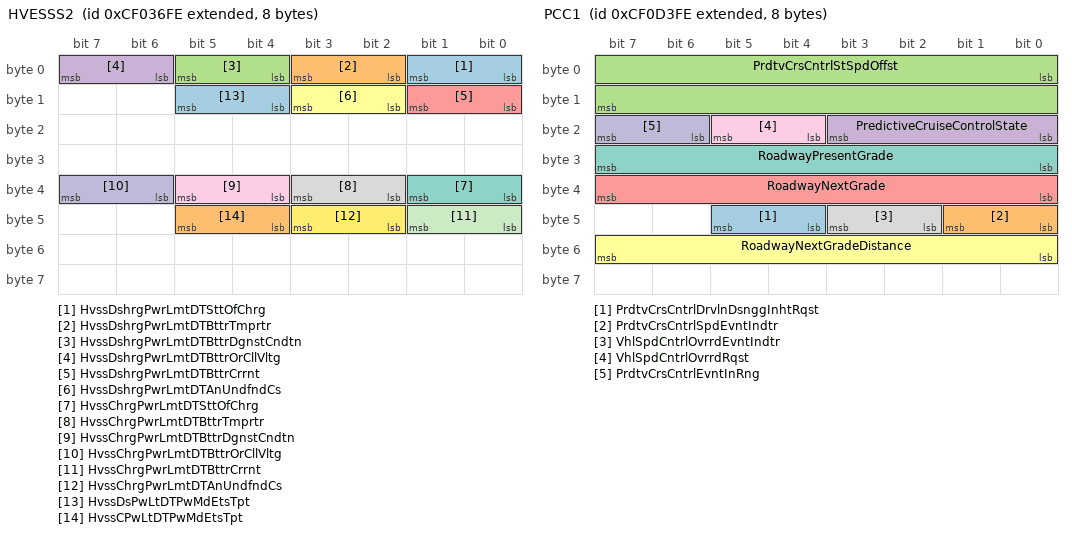
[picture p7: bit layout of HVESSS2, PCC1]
BO_ 2364552958 HVESSS2: 8 Vector__XXX
 SG_ HvssDshrgPwrLmtDTSttOfChrg : 0|2@1+ (1,0) [0|3] "" Vector__XXX
 SG_ HvssDshrgPwrLmtDTBttrTmprtr : 2|2@1+ (1,0) [0|3] "" Vector__XXX
 SG_ HvssDshrgPwrLmtDTBttrDgnstCndtn : 4|2@1+ (1,0) [0|3] "" Vector__XXX
 SG_ HvssDshrgPwrLmtDTBttrOrCllVltg : 6|2@1+ (1,0) [0|3] "" Vector__XXX
 SG_ HvssDshrgPwrLmtDTBttrCrrnt : 8|2@1+ (1,0) [0|3] "" Vector__XXX
 SG_ HvssDshrgPwrLmtDTAnUndfndCs : 10|2@1+ (1,0) [0|3] "" Vector__XXX
 SG_ HvssChrgPwrLmtDTSttOfChrg : 32|2@1+ (1,0) [0|3] "" Vector__XXX
 SG_ HvssChrgPwrLmtDTBttrTmprtr : 34|2@1+ (1,0) [0|3] "" Vector__XXX
 SG_ HvssChrgPwrLmtDTBttrDgnstCndtn : 36|2@1+ (1,0) [0|3] "" Vector__XXX
 SG_ HvssChrgPwrLmtDTBttrOrCllVltg : 38|2@1+ (1,0) [0|3] "" Vector__XXX
 SG_ HvssChrgPwrLmtDTBttrCrrnt : 40|2@1+ (1,0) [0|3] "" Vector__XXX
 SG_ HvssChrgPwrLmtDTAnUndfndCs : 42|2@1+ (1,0) [0|3] "" Vector__XXX
 SG_ HvssDsPwLtDTPwMdEtsTpt : 12|2@1+ (1,0) [0|3] "" Vector__XXX
 SG_ HvssCPwLtDTPwMdEtsTpt : 44|2@1+ (1,0) [0|3] "" Vector__XXX

BO_ 2364553214 ETBA1: 8 Vector__XXX
 SG_ EngnTrhrgrCmprssrBlwffAttr1Pstn : 24|8@1+ (0.4,0) [0|100] "%" Vector__XXX
 SG_ ETCpssBwAtt1DsdPst : 16|8@1+ (0.4,0) [0|100] "%" Vector__XXX
 SG_ ETCpssBwAtt1OptStts : 32|4@1+ (1,0) [0|15] "" Vector__XXX
 SG_ ETCpssBwAtt1Tpt : 8|8@1+ (1,-40) [-40|210] "degC" Vector__XXX
 SG_ ETCpssBwAtt1TptStts : 5|3@1+ (1,0) [0|7] "" Vector__XXX
 SG_ ETCpssBwAtt1PF : 0|5@1+ (1,0) [0|31] "" Vector__XXX

BO_ 2364553470 ETFR: 8 Vector__XXX
 SG_ EngineCylinderTorque : 40|16@1+ (1,0) [0|64255] "Nm" Vector__XXX
 SG_ EngineDualFuelModeCommand : 56|2@1+ (1,0) [0|100] "" Vector__XXX
 SG_ EngnClndrDslMssFlwRtCmmnd : 24|16@1+ (0.00006103515625,0) [0|3.92181396484375] "kg/s" Vector__XXX
 SG_ EngnClndrGsMssFlwRtCmmnd : 8|16@1+ (0.00006103515625,0) [0|3.92181396484375] "kg/s" Vector__XXX
 SG_ EngnGsSstttnFlPrntgCmmnd : 0|8@1+ (0.5,0) [0|100] "%" Vector__XXX

BO_ 2364553726 EASI: 8 Vector__XXX
 SG_ EngineDesiredAirFuelRatio : 0|16@1+ (0.001,0) [0|64.255] "" Vector__XXX
 SG_ EngnFlSstm1TtlIntkMssArFlwRt : 16|16@1+ (0.0009765625,0) [0|62.7490234375] "kg/s" Vector__XXX
 SG_ EngnFlSstm2TtlIntkMssArFlwRt : 32|16@1+ (0.0009765625,0) [0|62.7490234375] "kg/s" Vector__XXX
 SG_ CommandedEquivalenceRatio : 48|16@1+ (0.001,0) [0|64.255] "" Vector__XXX

BO_ 2364553982 ECCI1: 8 Vector__XXX
 SG_ EngineCylinder1HeatRelease : 0|16@1+ (0.0001220703125,-1) [-1|6.8436279296875] "kJ/l" Vector__XXX
 SG_ EngineCylinder1PeakPressure : 16|16@1+ (0.0009765625,0) [0|62.7490234375] "MPa" Vector__XXX
 SG_ EngnClndr1LwFrqnKnkLvl : 48|8@1+ (1,0) [0|250] "%" Vector__XXX
 SG_ EngnClndr1MxmmPrssrInrsRt : 56|8@1+ (16,0) [0|4000] "kPa/deg crank angle" Vector__XXX
 SG_ EngnClndr1SnhrnsKnkLvl : 32|8@1+ (1,0) [0|100] "%" Vector__XXX
 SG_ EngnClndr1PrssrSnsrPrlmnrFm : 40|5@1+ (1,0) [0|31] "" Vector__XXX

BO_ 2364554238 ECCI2: 8 Vector__XXX
 SG_ EngineCylinder2HeatRelease : 0|16@1+ (0.0001220703125,-1) [-1|6.8436279296875] "kJ/l" Vector__XXX
 SG_ EngineCylinder2PeakPressure : 16|16@1+ (0.0009765625,0) [0|62.7490234375] "MPa" Vector__XXX
 SG_ EngnClndr2LwFrqnKnkLvl : 48|8@1+ (1,0) [0|250] "%" Vector__XXX
 SG_ EngnClndr2MxmmPrssrInrsRt : 56|8@1+ (16,0) [0|4000] "kPa/deg crank angle" Vector__XXX
 SG_ EngnClndr2SnhrnsKnkLvl : 32|8@1+ (1,0) [0|250] "%" Vector__XXX
 SG_ EngnClndr2PrssrSnsrPrlmnrFm : 40|5@1+ (1,0) [0|31] "" Vector__XXX

BO_ 2364554494 ECCI3: 8 Vector__XXX
 SG_ EngineCylinder3HeatRelease : 0|16@1+ (0.0001220703125,-1) [-1|6.8436279296875] "kJ/l" Vector__XXX
 SG_ EngineCylinder3PeakPressure : 16|16@1+ (0.0009765625,0) [0|62.7490234375] "MPa" Vector__XXX
 SG_ EngnClndr3LwFrqnKnkLvl : 48|8@1+ (1,0) [0|250] "%" Vector__XXX
 SG_ EngnClndr3MxmmPrssrInrsRt : 56|8@1+ (16,0) [0|4000] "kPa/deg crank angle" Vector__XXX
 SG_ EngnClndr3SnhrnsKnkLvl : 32|8@1+ (1,0) [0|250] "%" Vector__XXX
 SG_ EngnClndr3PrssrSnsrPrlmnrFm : 40|5@1+ (1,0) [0|31] "" Vector__XXX

BO_ 2364554750 ECCI4: 8 Vector__XXX
 SG_ EngineCylinder4HeatRelease : 0|16@1+ (0.0001220703125,-1) [-1|6.8436279296875] "kJ/l" Vector__XXX
 SG_ EngineCylinder4PeakPressure : 16|16@1+ (0.0009765625,0) [0|62.7490234375] "MPa" Vector__XXX
 SG_ EngnClndr4LwFrqnKnkLvl : 48|8@1+ (1,0) [0|250] "%" Vector__XXX
 SG_ EngnClndr4MxmmPrssrInrsRt : 56|8@1+ (16,0) [0|4000] "kPa/deg crank angle" Vector__XXX
 SG_ EngnClndr4SnhrnsKnkLvl : 32|8@1+ (1,0) [0|250] "%" Vector__XXX
 SG_ EngnClndr4PrssrSnsrPrlmnrFm : 40|5@1+ (1,0) [0|31] "" Vector__XXX

BO_ 2364555006 ECCI5: 8 Vector__XXX
 SG_ EngineCylinder5HeatRelease : 0|16@1+ (0.0001220703125,-1) [-1|6.8436279296875] "kJ/l" Vector__XXX
 SG_ EngineCylinder5PeakPressure : 16|16@1+ (0.0009765625,0) [0|62.7490234375] "MPa" Vector__XXX
 SG_ EngnClndr5LwFrqnKnkLvl : 48|8@1+ (1,0) [0|250] "%" Vector__XXX
 SG_ EngnClndr5MxmmPrssrInrsRt : 56|8@1+ (16,0) [0|4000] "kPa/deg crank angle" Vector__XXX
 SG_ EngnClndr5SnhrnsKnkLvl : 32|8@1+ (1,0) [0|250] "%" Vector__XXX
 SG_ EngnClndr5PrssrSnsrPrlmnrFm : 40|5@1+ (1,0) [0|31] "" Vector__XXX

BO_ 2364555262 ECCI6: 8 Vector__XXX
 SG_ EngineCylinder6HeatRelease : 0|16@1+ (0.0001220703125,-1) [-1|6.8436279296875] "kJ/l" Vector__XXX
 SG_ EngineCylinder6PeakPressure : 16|16@1+ (0.0009765625,0) [0|62.7490234375] "MPa" Vector__XXX
 SG_ EngnClndr6LwFrqnKnkLvl : 48|8@1+ (1,0) [0|250] "%" Vector__XXX
 SG_ EngnClndr6MxmmPrssrInrsRt : 56|8@1+ (16,0) [0|4000] "kPa/deg crank angle" Vector__XXX
 SG_ EngnClndr6SnhrnsKnkLvl : 32|8@1+ (1,0) [0|250] "%" Vector__XXX
 SG_ EngnClndr6PrssrSnsrPrlmnrFm : 40|5@1+ (1,0) [0|31] "" Vector__XXX

BO_ 2364555518 ECCI7: 8 Vector__XXX
 SG_ EngineCylinder7HeatRelease : 0|16@1+ (0.0001220703125,-1) [-1|6.8436279296875] "kJ/l" Vector__XXX
 SG_ EngineCylinder7PeakPressure : 16|16@1+ (0.0009765625,0) [0|62.7490234375] "MPa" Vector__XXX
 SG_ EngnClndr7LwFrqnKnkLvl : 48|8@1+ (1,0) [0|250] "%" Vector__XXX
 SG_ EngnClndr7MxmmPrssrInrsRt : 56|8@1+ (16,0) [0|4000] "kPa/deg crank angle" Vector__XXX
 SG_ EngnClndr7SnhrnsKnkLvl : 32|8@1+ (1,0) [0|250] "%" Vector__XXX
 SG_ EngnClndr7PrssrSnsrPrlmnrFm : 40|5@1+ (1,0) [0|31] "" Vector__XXX

BO_ 2364555774 ECCI8: 8 Vector__XXX
 SG_ EngineCylinder8HeatRelease : 0|16@1+ (0.0001220703125,-1) [-1|6.8436279296875] "kJ/l" Vector__XXX
 SG_ EngineCylinder8PeakPressure : 16|16@1+ (0.0009765625,0) [0|62.7490234375] "MPa" Vector__XXX
 SG_ EngnClndr8LwFrqnKnkLvl : 48|8@1+ (1,0) [0|250] "%" Vector__XXX
 SG_ EngnClndr8MxmmPrssrInrsRt : 56|8@1+ (16,0) [0|4000] "kPa/deg crank angle" Vector__XXX
 SG_ EngnClndr8SnhrnsKnkLvl : 32|8@1+ (1,0) [0|250] "%" Vector__XXX
 SG_ EngnClndr8PrssrSnsrPrlmnrFm : 40|5@1+ (1,0) [0|31] "" Vector__XXX

BO_ 2364556030 ECCI9: 8 Vector__XXX
 SG_ EngineCylinder9HeatRelease : 0|16@1+ (0.0001220703125,-1) [-1|6.8436279296875] "kJ/l" Vector__XXX
 SG_ EngineCylinder9PeakPressure : 16|16@1+ (0.0009765625,0) [0|62.7490234375] "MPa" Vector__XXX
 SG_ EngnClndr9LwFrqnKnkLvl : 48|8@1+ (1,0) [0|250] "%" Vector__XXX
 SG_ EngnClndr9MxmmPrssrInrsRt : 56|8@1+ (16,0) [0|4000] "kPa/deg crank angle" Vector__XXX
 SG_ EngnClndr9SnhrnsKnkLvl : 32|8@1+ (1,0) [0|250] "%" Vector__XXX
 SG_ EngnClndr9PrssrSnsrPrlmnrFm : 40|5@1+ (1,0) [0|31] "" Vector__XXX

BO_ 2364556286 ECCI10: 8 Vector__XXX
 SG_ EngineCylinder10HeatRelease : 0|16@1+ (0.0001220703125,-1) [-1|6.8436279296875] "kJ/l" Vector__XXX
 SG_ EngineCylinder10PeakPressure : 16|16@1+ (0.0009765625,0) [0|62.7490234375] "MPa" Vector__XXX
 SG_ EngnClndr10LwFrqnKnkLvl : 48|8@1+ (1,0) [0|250] "%" Vector__XXX
 SG_ EngnClndr10MxmmPrssrInrsRt : 56|8@1+ (16,0) [0|4000] "kPa/deg crank angle" Vector__XXX
 SG_ EngnClndr10SnhrnsKnkLvl : 32|8@1+ (1,0) [0|250] "%" Vector__XXX
 SG_ EngnClndr10PrssrSnsrPrlmnrFm : 40|5@1+ (1,0) [0|31] "" Vector__XXX

BO_ 2364556542 ECCI11: 8 Vector__XXX
 SG_ EngineCylinder11HeatRelease : 0|16@1+ (0.0001220703125,-1) [-1|6.8436279296875] "kJ/l" Vector__XXX
 SG_ EngineCylinder11PeakPressure : 16|16@1+ (0.0009765625,0) [0|62.7490234375] "MPa" Vector__XXX
 SG_ EngnClndr11LwFrqnKnkLvl : 48|8@1+ (1,0) [0|250] "%" Vector__XXX
 SG_ EngnClndr11MxmmPrssrInrsRt : 56|8@1+ (16,0) [0|4000] "kPa/deg crank angle" Vector__XXX
 SG_ EngnClndr11SnhrnsKnkLvl : 32|8@1+ (1,0) [0|250] "%" Vector__XXX
 SG_ EngnClndr11PrssrSnsrPrlmnrFm : 40|5@1+ (1,0) [0|31] "" Vector__XXX

BO_ 2364556798 ECCI12: 8 Vector__XXX
 SG_ EngineCylinder12HeatRelease : 0|16@1+ (0.0001220703125,-1) [-1|6.8436279296875] "kJ/l" Vector__XXX
 SG_ EngineCylinder12PeakPressure : 16|16@1+ (0.0009765625,0) [0|62.7490234375] "MPa" Vector__XXX
 SG_ EngnClndr12LwFrqnKnkLvl : 48|8@1+ (1,0) [0|250] "%" Vector__XXX
 SG_ EngnClndr12MxmmPrssrInrsRt : 56|8@1+ (16,0) [0|4000] "kPa/deg crank angle" Vector__XXX
 SG_ EngnClndr12SnhrnsKnkLvl : 32|8@1+ (1,0) [0|250] "%" Vector__XXX
 SG_ EngnClndr12PrssrSnsrPrlmnrFm : 40|5@1+ (1,0) [0|31] "" Vector__XXX

BO_ 2364557054 ECCI13: 8 Vector__XXX
 SG_ EngineCylinder13HeatRelease : 0|16@1+ (0.0001220703125,-1) [-1|6.8436279296875] "kJ/l" Vector__XXX
 SG_ EngineCylinder13PeakPressure : 16|16@1+ (0.0009765625,0) [0|62.7490234375] "MPa" Vector__XXX
 SG_ EngnClndr13LwFrqnKnkLvl : 48|8@1+ (1,0) [0|250] "%" Vector__XXX
 SG_ EngnClndr13MxmmPrssrInrsRt : 56|8@1+ (16,0) [0|4000] "kPa/deg crank angle" Vector__XXX
 SG_ EngnClndr13SnhrnsKnkLvl : 32|8@1+ (1,0) [0|250] "%" Vector__XXX
 SG_ EngnClndr13PrssrSnsrPrlmnrFm : 40|5@1+ (1,0) [0|31] "" Vector__XXX

BO_ 2364557310 ECCI14: 8 Vector__XXX
 SG_ EngineCylinder14HeatRelease : 0|16@1+ (0.0001220703125,-1) [-1|6.8436279296875] "kJ/l" Vector__XXX
 SG_ EngineCylinder14PeakPressure : 16|16@1+ (0.0009765625,0) [0|62.7490234375] "MPa" Vector__XXX
 SG_ EngnClndr14LwFrqnKnkLvl : 48|8@1+ (1,0) [0|250] "%" Vector__XXX
 SG_ EngnClndr14MxmmPrssrInrsRt : 56|8@1+ (16,0) [0|4000] "kPa/deg crank angle" Vector__XXX
 SG_ EngnClndr14SnhrnsKnkLvl : 32|8@1+ (1,0) [0|250] "%" Vector__XXX
 SG_ EngnClndr14PrssrSnsrPrlmnrFm : 40|5@1+ (1,0) [0|31] "" Vector__XXX

BO_ 2364557566 ECCI15: 8 Vector__XXX
 SG_ EngineCylinder15HeatRelease : 0|16@1+ (0.0001220703125,-1) [-1|6.8436279296875] "kJ/l" Vector__XXX
 SG_ EngineCylinder15PeakPressure : 16|16@1+ (0.0009765625,0) [0|62.7490234375] "MPa" Vector__XXX
 SG_ EngnClndr15LwFrqnKnkLvl : 48|8@1+ (1,0) [0|250] "%" Vector__XXX
 SG_ EngnClndr15MxmmPrssrInrsRt : 56|8@1+ (16,0) [0|4000] "kPa/deg crank angle" Vector__XXX
 SG_ EngnClndr15SnhrnsKnkLvl : 32|8@1+ (1,0) [0|250] "%" Vector__XXX
 SG_ EngnClndr15PrssrSnsrPrlmnrFm : 40|5@1+ (1,0) [0|31] "" Vector__XXX

BO_ 2364557822 ECCI16: 8 Vector__XXX
 SG_ EngineCylinder16HeatRelease : 0|16@1+ (0.0001220703125,-1) [-1|6.8436279296875] "kJ/l" Vector__XXX
 SG_ EngineCylinder16PeakPressure : 16|16@1+ (0.0009765625,0) [0|62.7490234375] "MPa" Vector__XXX
 SG_ EngnClndr16LwFrqnKnkLvl : 48|8@1+ (1,0) [0|250] "%" Vector__XXX
 SG_ EngnClndr16MxmmPrssrInrsRt : 56|8@1+ (16,0) [0|4000] "kPa/deg crank angle" Vector__XXX
 SG_ EngnClndr16SnhrnsKnkLvl : 32|8@1+ (1,0) [0|250] "%" Vector__XXX
 SG_ EngnClndr16PrssrSnsrPrlmnrFm : 40|5@1+ (1,0) [0|31] "" Vector__XXX

BO_ 2364558078 ECCI17: 8 Vector__XXX
 SG_ EngineCylinder17HeatRelease : 0|16@1+ (0.0001220703125,-1) [-1|6.8436279296875] "kJ/l" Vector__XXX
 SG_ EngineCylinder17PeakPressure : 16|16@1+ (0.0009765625,0) [0|62.7490234375] "MPa" Vector__XXX
 SG_ EngnClndr17LwFrqnKnkLvl : 48|8@1+ (1,0) [0|250] "%" Vector__XXX
 SG_ EngnClndr17MxmmPrssrInrsRt : 56|8@1+ (16,0) [0|4000] "kPa/deg crank angle" Vector__XXX
 SG_ EngnClndr17SnhrnsKnkLvl : 32|8@1+ (1,0) [0|250] "%" Vector__XXX
 SG_ EngnClndr17PrssrSnsrPrlmnrFm : 40|5@1+ (1,0) [0|31] "" Vector__XXX

BO_ 2364558334 ECCI18: 8 Vector__XXX
 SG_ EngineCylinder18HeatRelease : 0|16@1+ (0.0001220703125,-1) [-1|6.8436279296875] "kJ/l" Vector__XXX
 SG_ EngineCylinder18PeakPressure : 16|16@1+ (0.0009765625,0) [0|62.7490234375] "MPa" Vector__XXX
 SG_ EngnClndr18LwFrqnKnkLvl : 48|8@1+ (1,0) [0|250] "%" Vector__XXX
 SG_ EngnClndr18MxmmPrssrInrsRt : 56|8@1+ (16,0) [0|4000] "kPa/deg crank angle" Vector__XXX
 SG_ EngnClndr18SnhrnsKnkLvl : 32|8@1+ (1,0) [0|250] "%" Vector__XXX
 SG_ EngnClndr18PrssrSnsrPrlmnrFm : 40|5@1+ (1,0) [0|31] "" Vector__XXX

BO_ 2364558590 ECCI19: 8 Vector__XXX
 SG_ EngineCylinder19HeatRelease : 0|16@1+ (0.0001220703125,-1) [-1|6.8436279296875] "kJ/l" Vector__XXX
 SG_ EngineCylinder19PeakPressure : 16|16@1+ (0.0009765625,0) [0|62.7490234375] "MPa" Vector__XXX
 SG_ EngnClndr19LwFrqnKnkLvl : 48|8@1+ (1,0) [0|250] "%" Vector__XXX
 SG_ EngnClndr19MxmmPrssrInrsRt : 56|8@1+ (16,0) [0|4000] "kPa/deg crank angle" Vector__XXX
 SG_ EngnClndr19SnhrnsKnkLvl : 32|8@1+ (1,0) [0|250] "%" Vector__XXX
 SG_ EngnClndr19PrssrSnsrPrlmnrFm : 40|5@1+ (1,0) [0|31] "" Vector__XXX

BO_ 2364558846 ECCI20: 8 Vector__XXX
 SG_ EngineCylinder20HeatRelease : 0|16@1+ (0.0001220703125,-1) [-1|6.8436279296875] "kJ/l" Vector__XXX
 SG_ EngineCylinder20PeakPressure : 16|16@1+ (0.0009765625,0) [0|62.7490234375] "MPa" Vector__XXX
 SG_ EngnClndr20LwFrqnKnkLvl : 48|8@1+ (1,0) [0|250] "%" Vector__XXX
 SG_ EngnClndr20MxmmPrssrInrsRt : 56|8@1+ (16,0) [0|4000] "kPa/deg crank angle" Vector__XXX
 SG_ EngnClndr20SnhrnsKnkLvl : 32|8@1+ (1,0) [0|250] "%" Vector__XXX
 SG_ EngnClndr20PrssrSnsrPrlmnrFm : 40|5@1+ (1,0) [0|31] "" Vector__XXX

BO_ 2364564478 GFI5: 8 Vector__XXX
 SG_ EngnGssFlVlvNmnlDrtnCmmnd : 0|16@1+ (2,0) [0|128510] "micro s" Vector__XXX
 SG_ EngnPrChmrFlVlvNmnlDrtnCmmnd : 32|16@1+ (2,0) [0|128510] "micro s" Vector__XXX
 SG_ EngnGssFlVlvNmnlStrtOfAttnCmmnd : 16|16@1+ (0.0078125,-400) [-400|101.9921875] "deg" Vector__XXX
 SG_ EPCFVvNSttOAttCd : 48|16@1+ (0.0078125,-400) [-400|101.9921875] "deg" Vector__XXX

BO_ 2364564734 EGFVDC1: 8 Vector__XXX
 SG_ EngnGssFlVlv1DrtnCmmnd : 0|16@1+ (2,0) [0|128510] "micro s" Vector__XXX
 SG_ EngnGssFlVlv2DrtnCmmnd : 16|16@1+ (2,0) [0|128510] "micro s" Vector__XXX
 SG_ EngnGssFlVlv3DrtnCmmnd : 32|16@1+ (2,0) [0|128510] "micro s" Vector__XXX
 SG_ EngnGssFlVlv4DrtnCmmnd : 48|16@1+ (2,0) [0|128510] "micro s" Vector__XXX

BO_ 2364564990 EGFVDC2: 8 Vector__XXX
 SG_ EngnGssFlVlv5DrtnCmmnd : 0|16@1+ (2,0) [0|128510] "micro s" Vector__XXX
 SG_ EngnGssFlVlv6DrtnCmmnd : 16|16@1+ (2,0) [0|128510] "micro s" Vector__XXX
 SG_ EngnGssFlVlv7DrtnCmmnd : 32|16@1+ (2,0) [0|128510] "micro s" Vector__XXX
 SG_ EngnGssFlVlv8DrtnCmmnd : 48|16@1+ (2,0) [0|128510] "micro s" Vector__XXX

BO_ 2364565246 EGFVDC3: 8 Vector__XXX
 SG_ EngnGssFlVlv10DrtnCmmnd : 16|16@1+ (2,0) [0|128510] "micro s" Vector__XXX
 SG_ EngnGssFlVlv11DrtnCmmnd : 32|16@1+ (2,0) [0|128510] "micro s" Vector__XXX
 SG_ EngnGssFlVlv12DrtnCmmnd : 48|16@1+ (2,0) [0|128510] "micro s" Vector__XXX
 SG_ EngnGssFlVlv9DrtnCmmnd : 0|16@1+ (2,0) [0|128510] "micro s" Vector__XXX

BO_ 2364565502 EGFVDC4: 8 Vector__XXX
 SG_ EngnGssFlVlv13DrtnCmmnd : 0|16@1+ (2,0) [0|128510] "micro s" Vector__XXX
 SG_ EngnGssFlVlv14DrtnCmmnd : 16|16@1+ (2,0) [0|128510] "micro s" Vector__XXX
 SG_ EngnGssFlVlv15DrtnCmmnd : 32|16@1+ (2,0) [0|128510] "micro s" Vector__XXX
 SG_ EngnGssFlVlv16DrtnCmmnd : 48|16@1+ (2,0) [0|128510] "micro s" Vector__XXX

BO_ 2364565758 EGFVDC5: 8 Vector__XXX
 SG_ EngnGssFlVlv17DrtnCmmnd : 0|16@1+ (2,0) [0|128510] "micro s" Vector__XXX
 SG_ EngnGssFlVlv18DrtnCmmnd : 16|16@1+ (2,0) [0|128510] "micro s" Vector__XXX
 SG_ EngnGssFlVlv19DrtnCmmnd : 32|16@1+ (2,0) [0|128510] "micro s" Vector__XXX
 SG_ EngnGssFlVlv20DrtnCmmnd : 48|16@1+ (2,0) [0|128510] "micro s" Vector__XXX

BO_ 2364566014 EGFVSOAC1: 8 Vector__XXX
 SG_ EngnGssFlVlv1StrtOfAttnCmmnd : 0|16@1+ (0.0078125,-400) [-400|101.9921875] "deg" Vector__XXX
 SG_ EngnGssFlVlv2StrtOfAttnCmmnd : 16|16@1+ (0.0078125,-400) [-400|101.9921875] "deg" Vector__XXX
 SG_ EngnGssFlVlv3StrtOfAttnCmmnd : 32|16@1+ (0.0078125,-400) [-400|101.9921875] "deg" Vector__XXX
 SG_ EngnGssFlVlv4StrtOfAttnCmmnd : 48|16@1+ (0.0078125,-400) [-400|101.9921875] "deg" Vector__XXX

BO_ 2364566270 EGFVSOAC2: 8 Vector__XXX
 SG_ EngnGssFlVlv5StrtOfAttnCmmnd : 0|16@1+ (0.0078125,-400) [-400|101.9921875] "deg" Vector__XXX
 SG_ EngnGssFlVlv6StrtOfAttnCmmnd : 16|16@1+ (0.0078125,-400) [-400|101.9921875] "deg" Vector__XXX
 SG_ EngnGssFlVlv7StrtOfAttnCmmnd : 32|16@1+ (0.0078125,-400) [-400|101.9921875] "deg" Vector__XXX
 SG_ EngnGssFlVlv8StrtOfAttnCmmnd : 48|16@1+ (0.0078125,-400) [-400|101.9921875] "deg" Vector__XXX

BO_ 2364566526 EGFVSOAC3: 8 Vector__XXX
 SG_ EngnGssFlVlv9StrtOfAttnCmmnd : 0|16@1+ (0.0078125,-400) [-400|101.9921875] "deg" Vector__XXX
 SG_ EngnGssFlVlv10StrtOfAttnCmmnd : 16|16@1+ (0.0078125,-400) [-400|101.9921875] "deg" Vector__XXX
 SG_ EngnGssFlVlv11StrtOfAttnCmmnd : 32|16@1+ (0.0078125,-400) [-400|101.9921875] "deg" Vector__XXX
 SG_ EngnGssFlVlv12StrtOfAttnCmmnd : 48|16@1+ (0.0078125,-400) [-400|101.9921875] "deg" Vector__XXX

BO_ 2364566782 EGFVSOAC4: 8 Vector__XXX
 SG_ EngnGssFlVlv13StrtOfAttnCmmnd : 0|16@1+ (0.0078125,-400) [-400|101.9921875] "deg" Vector__XXX
 SG_ EngnGssFlVlv14StrtOfAttnCmmnd : 16|16@1+ (0.0078125,-400) [-400|101.9921875] "deg" Vector__XXX
 SG_ EngnGssFlVlv15StrtOfAttnCmmnd : 32|16@1+ (0.0078125,-400) [-400|101.9921875] "deg" Vector__XXX
 SG_ EngnGssFlVlv16StrtOfAttnCmmnd : 48|16@1+ (0.0078125,-400) [-400|101.9921875] "deg" Vector__XXX

BO_ 2364567038 EGFVSOAC5: 8 Vector__XXX
 SG_ EngnGssFlVlv17StrtOfAttnCmmnd : 0|16@1+ (0.0078125,-400) [-400|101.9921875] "deg" Vector__XXX
 SG_ EngnGssFlVlv18StrtOfAttnCmmnd : 16|16@1+ (0.0078125,-400) [-400|101.9921875] "deg" Vector__XXX
 SG_ EngnGssFlVlv19StrtOfAttnCmmnd : 32|16@1+ (0.0078125,-400) [-400|101.9921875] "deg" Vector__XXX
 SG_ EngnGssFlVlv20StrtOfAttnCmmnd : 48|16@1+ (0.0078125,-400) [-400|101.9921875] "deg" Vector__XXX

BO_ 2364567294 FPAC: 8 Vector__XXX
 SG_ EngnFlInjtnPmp1FlCntrlVlvCmmnd : 0|16@1+ (0.0025,0) [0|100] "%" Vector__XXX
 SG_ EngnFlInjtnPmp2FlCntrlVlvCmmnd : 16|16@1+ (0.0025,0) [0|100] "%" Vector__XXX

BO_ 2364575998 HVESSD1: 8 Vector__XXX
 SG_ HvessAvailableDischargePower : 0|16@1+ (0.05,0) [0|3212.75] "kW" Vector__XXX
 SG_ HvessAvailableChargePower : 16|16@1+ (0.05,0) [0|3212.75] "kW" Vector__XXX
 SG_ HvessVoltageLevel : 32|16@1+ (0.05,0) [0|3212.75] "V" Vector__XXX
 SG_ HvessCurrent : 48|16@1+ (0.05,-1600) [-1600|1612.75] "A" Vector__XXX

BO_ 2364576254 HVESSD2: 8 Vector__XXX
 SG_ HvessFastUpdateStateOfCharge : 0|16@1+ (0.0015625,0) [0|100.3984375] "%" Vector__XXX
 SG_ HvessHighestCellVoltage : 16|16@1+ (0.001,0) [0|64.255] "V" Vector__XXX
 SG_ HvessLowestCellVoltage : 32|16@1+ (0.001,0) [0|64.255] "V" Vector__XXX
 SG_ HvssCllVltgDffrntlStts : 48|4@1+ (1,0) [0|15] "" Vector__XXX

BO_ 2364576510 HVESSD3: 8 Vector__XXX
 SG_ HvessHighestCellTemperature : 0|16@1+ (0.03125,-273) [-273|1734.96875] "degC" Vector__XXX
 SG_ HvessLowestCellTemperature : 16|16@1+ (0.03125,-273) [-273|1734.96875] "degC" Vector__XXX
 SG_ HvessAverageCellTemperature : 32|16@1+ (0.03125,-273) [-273|1734.96875] "degC" Vector__XXX
 SG_ HvssCllTmprtrDffrntlStts : 48|2@1+ (1,0) [0|3] "" Vector__XXX

BO_ 2364576766 HVESSD4: 8 Vector__XXX
 SG_ HvessDischargeCapacity : 0|16@1+ (0.01,0) [0|642.55] "Ah" Vector__XXX
 SG_ HvessChargeCapacity : 16|16@1+ (0.01,0) [0|642.55] "Ah" Vector__XXX
 SG_ HvessCellBalancingCount : 32|16@1+ (1,0) [0|64255] "count" Vector__XXX

BO_ 2364577022 HVESSD5: 8 Vector__XXX
 SG_ HvessMinimumCellStateOfCharge : 32|16@1+ (0.0015625,0) [0|100.3984375] "%" Vector__XXX
 SG_ HvessMaximumCellStateOfCharge : 48|16@1+ (0.0015625,0) [0|100.3984375] "%" Vector__XXX
 SG_ HvssMxmmInstntnsDshrgCrrntLmt : 0|16@1+ (0.05,-1600) [-1600|0] "A" Vector__XXX
 SG_ HvssMxmmInstntnsChrgCrrntLmt : 16|16@1+ (0.05,-1600) [0|1612.75] "A" Vector__XXX

BO_ 2364577278 HVESSD6: 8 Vector__XXX
 SG_ HvessBusVoltage : 0|16@1+ (0.05,0) [0|3212.75] "V" Vector__XXX
 SG_ HvessIgnitionVoltage : 16|16@1+ (0.01,0) [0|642.55] "V" Vector__XXX
 SG_ HvessIntakeCoolantTemperature : 32|8@1+ (1,-40) [-40|210] "degC" Vector__XXX
 SG_ HvessOutletCoolantTemperature : 40|8@1+ (1,-40) [-40|210] "degC" Vector__XXX
 SG_ HvessElectronicsTemperature : 48|8@1+ (1,-40) [-40|210] "degC" Vector__XXX
 SG_ HvessTemperature : 56|8@1+ (1,-40) [-40|210] "degC" Vector__XXX

BO_ 2364577534 HVESSS1: 8 Vector__XXX
 SG_ HvessCenterOfPackContactorState : 10|2@1+ (1,0) [0|3] "" Vector__XXX
 SG_ HvessHvilStatus : 20|2@1+ (1,0) [0|3] "" Vector__XXX
 SG_ HvessInertiaSwitchStatus : 22|2@1+ (1,0) [0|3] "" Vector__XXX
 SG_ HvessStateOfChargeStatus : 24|4@1+ (1,0) [0|15] "" Vector__XXX
 SG_ HvessCellBalanceStatus : 28|2@1+ (1,0) [0|3] "" Vector__XXX
 SG_ HvessCellBalancingActive : 30|2@1+ (1,0) [0|3] "" Vector__XXX
 SG_ HvessInternalChargerStatus : 32|2@1+ (1,0) [0|3] "" Vector__XXX
 SG_ HvessOperationalStatus : 44|4@1+ (1,0) [0|15] "" Vector__XXX
 SG_ HvessNumberOfHvespsReady : 48|8@1+ (1,0) [0|250] "count" Vector__XXX
 SG_ HvessStatus1Counter : 36|4@1+ (1,0) [0|15] "" Vector__XXX
 SG_ HvessStatus1Crc : 56|8@1+ (1,0) [0|250] "count" Vector__XXX
 SG_ HvssHghVltgBsPstvCnttrStt : 0|2@1+ (1,0) [0|3] "" Vector__XXX
 SG_ HvssHghVltgBsNgtvCnttrStt : 2|2@1+ (1,0) [0|3] "" Vector__XXX
 SG_ HvssHghVltgBsDsnntFrwrnng : 4|4@1+ (1,0) [0|15] "" Vector__XXX
 SG_ HvssHghVltgBsPrChrgRlStt : 8|2@1+ (1,0) [0|3] "" Vector__XXX
 SG_ HvssHghVltgBsAtvIsltnTstStts : 12|4@1+ (1,0) [0|15] "" Vector__XXX
 SG_ HvssHghVltgBsPssvIsltnTstStts : 16|4@1+ (1,0) [0|15] "" Vector__XXX
 SG_ HvssHghVltgBsCnntnStts : 40|4@1+ (1,0) [0|15] "" Vector__XXX

BO_ 2364580094 HVESSD7: 8 Vector__XXX
 SG_ HvessDischargeEnergyCapacity : 0|24@1+ (0.001,0) [0|16449.535] "kWh" Vector__XXX
 SG_ HvessChargeEnergyCapacity : 24|24@1+ (0.001,0) [0|16449.535] "kWh" Vector__XXX
 SG_ HvessMaximumChargeVoltageLimit : 48|16@1+ (0.05,0) [0|3212.75] "V" Vector__XXX

BO_ 2364590334 DCACAI1S2: 8 Vector__XXX
 SG_ DAAssrInvrtr1DSdPwr : 0|16@1+ (0.0625,0) [0|4015.9375] "kW" Vector__XXX
 SG_ DAAssrInvrtr1DSdVltg : 16|16@1+ (0.05,0) [0|3212.75] "V" Vector__XXX
 SG_ DAAssrInvrtr1DSdCrrnt : 32|16@1+ (0.0625,0) [0|4015.9375] "A" Vector__XXX
 SG_ DAAssIvt1DSdNtvTCsssGdVt : 48|16@1+ (0.05,0) [0|3212.75] "V" Vector__XXX

BO_ 2364590590 DCACAI1V: 8 Vector__XXX
 SG_ DAAssrInvrtr1IgntnVltg : 0|16@1+ (0.05,0) [0|3212.75] "V" Vector__XXX
 SG_ DAAssrInvrtr1UnswthdSlVltg : 16|16@1+ (0.05,0) [0|3212.75] "V" Vector__XXX

BO_ 2364591102 DCACAI2S2: 8 Vector__XXX
 SG_ DAAssrInvrtr2DSdPwr : 0|16@1+ (0.0625,0) [0|4015.9375] "kW" Vector__XXX
 SG_ DAAssrInvrtr2DSdVltg : 16|16@1+ (0.05,0) [0|3212.75] "V" Vector__XXX
 SG_ DAAssrInvrtr2DSdCrrnt : 32|16@1+ (0.0625,0) [0|4015.9375] "A" Vector__XXX
 SG_ DAAssIvt2DSdNtvTCsssGdVt : 48|16@1+ (0.05,0) [0|3212.75] "V" Vector__XXX

BO_ 2364591358 DCACAI2V: 8 Vector__XXX
 SG_ DAAssrInvrtr2IgntnVltg : 0|16@1+ (0.05,0) [0|3212.75] "V" Vector__XXX
 SG_ DAAssrInvrtr2UnswthdSlVltg : 16|16@1+ (0.05,0) [0|3212.75] "V" Vector__XXX

BO_ 2364592382 ECCR: 8 Vector__XXX
 SG_ EngnClndr10ExldFrmCmstnRqst : 26|2@1+ (1,0) [0|3] "" Vector__XXX
 SG_ EngnClndr11ExldFrmCmstnRqst : 28|2@1+ (1,0) [0|3] "" Vector__XXX
 SG_ EngnClndr12ExldFrmCmstnRqst : 30|2@1+ (1,0) [0|3] "" Vector__XXX
 SG_ EngnClndr13ExldFrmCmstnRqst : 32|2@1+ (1,0) [0|3] "" Vector__XXX
 SG_ EngnClndr14ExldFrmCmstnRqst : 34|2@1+ (1,0) [0|3] "" Vector__XXX
 SG_ EngnClndr15ExldFrmCmstnRqst : 36|2@1+ (1,0) [0|3] "" Vector__XXX
 SG_ EngnClndr16ExldFrmCmstnRqst : 38|2@1+ (1,0) [0|3] "" Vector__XXX
 SG_ EngnClndr17ExldFrmCmstnRqst : 40|2@1+ (1,0) [0|3] "" Vector__XXX
 SG_ EngnClndr18ExldFrmCmstnRqst : 42|2@1+ (1,0) [0|3] "" Vector__XXX
 SG_ EngnClndr19ExldFrmCmstnRqst : 44|2@1+ (1,0) [0|3] "" Vector__XXX
 SG_ EngnClndr1ExldFrmCmstnRqst : 8|2@1+ (1,0) [0|3] "" Vector__XXX
 SG_ EngnClndr20ExldFrmCmstnRqst : 46|2@1+ (1,0) [0|3] "" Vector__XXX
 SG_ EngnClndr21ExldFrmCmstnRqst : 48|2@1+ (1,0) [0|3] "" Vector__XXX
 SG_ EngnClndr22ExldFrmCmstnRqst : 50|2@1+ (1,0) [0|3] "" Vector__XXX
 SG_ EngnClndr23ExldFrmCmstnRqst : 52|2@1+ (1,0) [0|3] "" Vector__XXX
 SG_ EngnClndr24ExldFrmCmstnRqst : 54|2@1+ (1,0) [0|3] "" Vector__XXX
 SG_ EngnClndr2ExldFrmCmstnRqst : 10|2@1+ (1,0) [0|3] "" Vector__XXX
 SG_ EngnClndr3ExldFrmCmstnRqst : 12|2@1+ (1,0) [0|3] "" Vector__XXX
 SG_ EngnClndr4ExldFrmCmstnRqst : 14|2@1+ (1,0) [0|3] "" Vector__XXX
 SG_ EngnClndr5ExldFrmCmstnRqst : 16|2@1+ (1,0) [0|3] "" Vector__XXX
 SG_ EngnClndr6ExldFrmCmstnRqst : 18|2@1+ (1,0) [0|3] "" Vector__XXX
 SG_ EngnClndr7ExldFrmCmstnRqst : 20|2@1+ (1,0) [0|3] "" Vector__XXX
 SG_ EngnClndr8ExldFrmCmstnRqst : 22|2@1+ (1,0) [0|3] "" Vector__XXX
 SG_ EngnClndr9ExldFrmCmstnRqst : 24|2@1+ (1,0) [0|3] "" Vector__XXX
 SG_ NmrOfEngnClndrsTExldFrmCmstn : 0|8@1+ (1,0) [0|24] "count" Vector__XXX

BO_ 2364592638 ECBA1: 8 Vector__XXX
 SG_ EngnClndrHdBpssAttr1DsrdPstn : 16|8@1+ (0.4,0) [0|100] "%" Vector__XXX
 SG_ EngnClndrHdBpssAttr1OprtnStts : 32|4@1+ (1,0) [0|15] "" Vector__XXX
 SG_ EngnClndrHdBpssAttr1Pstn : 24|8@1+ (0.4,0) [0|100] "%" Vector__XXX
 SG_ EngnClndrHdBpssAttr1Tmprtr : 8|8@1+ (1,-40) [-40|210] "degC" Vector__XXX
 SG_ EngnClndrHdBpssAttr1TmprtrStts : 5|3@1+ (1,0) [0|7] "" Vector__XXX
 SG_ EngnClndrHdBpssAttr1PrlmnrFm : 0|5@1+ (1,0) [0|31] "" Vector__XXX

BO_ 2364592894 EEC18: 8 Vector__XXX
 SG_ EngineIntakeAirSourceValve : 16|2@1+ (1,0) [0|3] "" Vector__XXX
 SG_ EngnClndrHdBpssAttr1Cmmnd : 0|16@1+ (0.0025,0) [0|160.6375] "%" Vector__XXX
 SG_ EngnExhstGsRstrtnVlvPstn : 32|16@1+ (0.0025,0) [0|160.6375] "%" Vector__XXX

BO_ 2364593150 PCC1: 8 Vector__XXX
 SG_ PrdtvCrsCntrlDrvlnDsnggInhtRqst : 44|2@1+ (1,0) [0|3] "" Vector__XXX
 SG_ PrdtvCrsCntrlSpdEvntIndtr : 40|2@1+ (1,0) [0|3] "" Vector__XXX
 SG_ PrdtvCrsCntrlStSpdOffst : 0|16@1+ (0.00390625,-125) [-125|125.99609375] "km/h" Vector__XXX
 SG_ PredictiveCruiseControlState : 16|4@1+ (1,0) [0|15] "" Vector__XXX
 SG_ RoadwayNextGrade : 32|8@1+ (0.125,-16) [-16|15.25] "%" Vector__XXX
 SG_ RoadwayNextGradeDistance : 48|8@1+ (25,0) [0|6250] "m" Vector__XXX
 SG_ RoadwayPresentGrade : 24|8@1+ (0.125,-16) [-16|15.25] "%" Vector__XXX
 SG_ VhlSpdCntrlOvrrdEvntIndtr : 42|2@1+ (1,0) [0|3] "" Vector__XXX
 SG_ VhlSpdCntrlOvrrdRqst : 20|2@1+ (1,0) [0|3] "" Vector__XXX
 SG_ PrdtvCrsCntrlEvntInRng : 22|2@1+ (1,0) [0|3] "" Vector__XXX

BO_ 2364597758 ITO1: 8 Vector__XXX
 SG_ EngnClndr1IgntnTmngOffst : 0|8@1+ (0.1,-12.5) [-12.5|12.5] "deg" Vector__XXX
 SG_ EngnClndr2IgntnTmngOffst : 8|8@1+ (0.1,-12.5) [-12.5|12.5] "deg" Vector__XXX
 SG_ EngnClndr3IgntnTmngOffst : 16|8@1+ (0.1,-12.5) [-12.5|12.5] "deg" Vector__XXX
 SG_ EngnClndr4IgntnTmngOffst : 24|8@1+ (0.1,-12.5) [-12.5|12.5] "deg" Vector__XXX
 SG_ EngnClndr5IgntnTmngOffst : 32|8@1+ (0.1,-12.5) [-12.5|12.5] "deg" Vector__XXX
 SG_ EngnClndr6IgntnTmngOffst : 40|8@1+ (0.1,-12.5) [-12.5|12.5] "deg" Vector__XXX
 SG_ EngnClndr7IgntnTmngOffst : 48|8@1+ (0.1,-12.5) [-12.5|12.5] "deg" Vector__XXX
 SG_ EngnClndr8IgntnTmngOffst : 56|8@1+ (0.1,-12.5) [-12.5|12.5] "deg" Vector__XXX

BO_ 2364598014 ITO2: 8 Vector__XXX
 SG_ EngnClndr10IgntnTmngOffst : 8|8@1+ (0.1,-12.5) [-12.5|12.5] "deg" Vector__XXX
 SG_ EngnClndr11IgntnTmngOffst : 16|8@1+ (0.1,-12.5) [-12.5|12.5] "deg" Vector__XXX
 SG_ EngnClndr12IgntnTmngOffst : 24|8@1+ (0.1,-12.5) [-12.5|12.5] "deg" Vector__XXX
 SG_ EngnClndr13IgntnTmngOffst : 32|8@1+ (0.1,-12.5) [-12.5|12.5] "deg" Vector__XXX
 SG_ EngnClndr14IgntnTmngOffst : 40|8@1+ (0.1,-12.5) [-12.5|12.5] "deg" Vector__XXX
 SG_ EngnClndr15IgntnTmngOffst : 48|8@1+ (0.1,-12.5) [-12.5|12.5] "deg" Vector__XXX
 SG_ EngnClndr16IgntnTmngOffst : 56|8@1+ (0.1,-12.5) [-12.5|12.5] "deg" Vector__XXX
 SG_ EngnClndr9IgntnTmngOffst : 0|8@1+ (0.1,-12.5) [-12.5|12.5] "deg" Vector__XXX

BO_ 2364598270 ITO3: 8 Vector__XXX
 SG_ EngnClndr17IgntnTmngOffst : 0|8@1+ (0.1,-12.5) [-12.5|12.5] "deg" Vector__XXX
 SG_ EngnClndr18IgntnTmngOffst : 8|8@1+ (0.1,-12.5) [-12.5|12.5] "deg" Vector__XXX
 SG_ EngnClndr19IgntnTmngOffst : 16|8@1+ (0.1,-12.5) [-12.5|12.5] "deg" Vector__XXX
 SG_ EngnClndr20IgntnTmngOffst : 24|8@1+ (0.1,-12.5) [-12.5|12.5] "deg" Vector__XXX
 SG_ EngnClndr21IgntnTmngOffst : 32|8@1+ (0.1,-12.5) [-12.5|12.5] "deg" Vector__XXX
 SG_ EngnClndr22IgntnTmngOffst : 40|8@1+ (0.1,-12.5) [-12.5|12.5] "deg" Vector__XXX
 SG_ EngnClndr23IgntnTmngOffst : 48|8@1+ (0.1,-12.5) [-12.5|12.5] "deg" Vector__XXX
 SG_ EngnClndr24IgntnTmngOffst : 56|8@1+ (0.1,-12.5) [-12.5|12.5] "deg" Vector__XXX

BO_ 2364598526 TFAC2: 8 Vector__XXX
 SG_ EngnFlAttr3CntrlCmmnd : 32|16@1+ (0.0025,0) [0|100] "%" Vector__XXX
 SG_ EngnFlAttr4CntrlCmmnd : 48|16@1+ (0.0025,0) [0|160.6375] "%" Vector__XXX
 SG_ EngnFlAttr1MtrCrrntDsl : 0|2@1+ (1,0) [0|3] "" Vector__XXX
 SG_ EngnFlAttr2MtrCrrntDsl : 2|2@1+ (1,0) [0|3] "" Vector__XXX

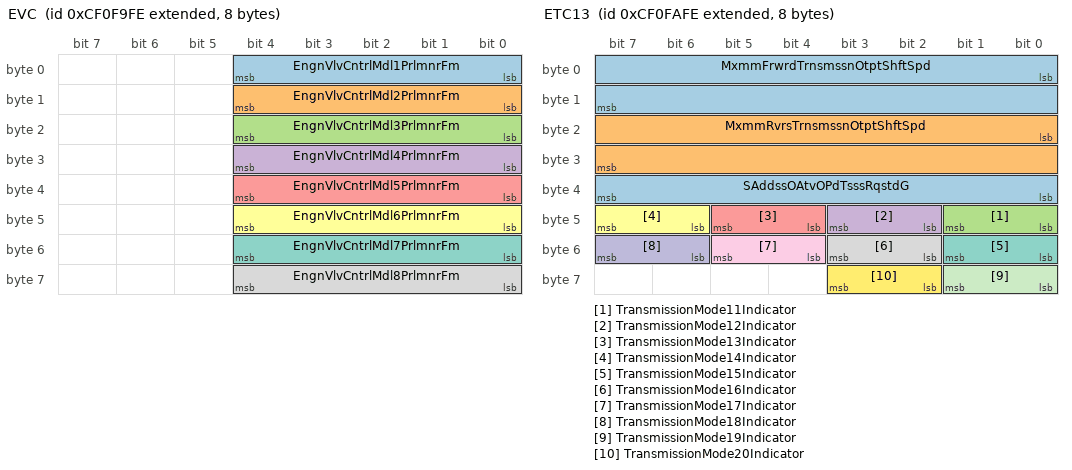
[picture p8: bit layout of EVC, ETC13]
BO_ 2364602878 EVC: 8 Vector__XXX
 SG_ EngnVlvCntrlMdl1PrlmnrFm : 0|5@1+ (1,0) [0|31] "" Vector__XXX
 SG_ EngnVlvCntrlMdl2PrlmnrFm : 8|5@1+ (1,0) [0|31] "" Vector__XXX
 SG_ EngnVlvCntrlMdl3PrlmnrFm : 16|5@1+ (1,0) [0|31] "" Vector__XXX
 SG_ EngnVlvCntrlMdl4PrlmnrFm : 24|5@1+ (1,0) [0|31] "" Vector__XXX
 SG_ EngnVlvCntrlMdl5PrlmnrFm : 32|5@1+ (1,0) [0|31] "" Vector__XXX
 SG_ EngnVlvCntrlMdl6PrlmnrFm : 40|5@1+ (1,0) [0|31] "" Vector__XXX
 SG_ EngnVlvCntrlMdl7PrlmnrFm : 48|5@1+ (1,0) [0|31] "" Vector__XXX
 SG_ EngnVlvCntrlMdl8PrlmnrFm : 56|5@1+ (1,0) [0|31] "" Vector__XXX

BO_ 2364603134 ETC13: 8 Vector__XXX
 SG_ MxmmFrwrdTrnsmssnOtptShftSpd : 0|16@1+ (0.125,0) [0|8031.875] "rpm" Vector__XXX
 SG_ MxmmRvrsTrnsmssnOtptShftSpd : 16|16@1+ (0.125,0) [0|8031.875] "rpm" Vector__XXX
 SG_ TransmissionMode11Indicator : 40|2@1+ (1,0) [0|3] "" Vector__XXX
 SG_ TransmissionMode12Indicator : 42|2@1+ (1,0) [0|3] "" Vector__XXX
 SG_ TransmissionMode13Indicator : 44|2@1+ (1,0) [0|3] "" Vector__XXX
 SG_ TransmissionMode14Indicator : 46|2@1+ (1,0) [0|3] "" Vector__XXX
 SG_ TransmissionMode15Indicator : 48|2@1+ (1,0) [0|3] "" Vector__XXX
 SG_ TransmissionMode16Indicator : 50|2@1+ (1,0) [0|3] "" Vector__XXX
 SG_ TransmissionMode17Indicator : 52|2@1+ (1,0) [0|3] "" Vector__XXX
 SG_ TransmissionMode18Indicator : 54|2@1+ (1,0) [0|3] "" Vector__XXX
 SG_ TransmissionMode19Indicator : 56|2@1+ (1,0) [0|3] "" Vector__XXX
 SG_ TransmissionMode20Indicator : 58|2@1+ (1,0) [0|3] "" Vector__XXX
 SG_ SAddssOAtvOPdTsssRqstdG : 32|8@1+ (1,0) [0|253] "sourceadr" Vector__XXX

BO_ 2364603390 A1SCRDSR3: 8 Vector__XXX
 SG_ Atttt1DsExstFdDsVv1Cd : 16|16@1+ (0.0025,0) [0|100] "%" Vector__XXX
 SG_ Atttt1DsExstFdRqstdQttOIttHRst : 0|16@1+ (0.001,0) [0|64.255] "g" Vector__XXX
 SG_ Atttt1DsExstFdDsVv2Cd : 32|16@1+ (0.0025,0) [0|100] "%" Vector__XXX

BO_ 2364603646 A2SCRDSR3: 8 Vector__XXX
 SG_ Atttt2DsExstFdRqstdQttOIttHRst : 0|16@1+ (0.001,0) [0|64.255] "g" Vector__XXX
 SG_ Atttt2DsExstFdDsVv1Cd : 16|16@1+ (0.0025,0) [0|160.6375] "%" Vector__XXX
 SG_ Atttt2DsExstFdDsVv2Cd : 32|16@1+ (0.0025,0) [0|160.6375] "%" Vector__XXX

BO_ 2364603902 A1SCRDSI4: 8 Vector__XXX
 SG_ Atttt1DsExstFdAtQttOIttHRst : 0|16@1+ (0.001,0) [0|64.255] "g" Vector__XXX

BO_ 2364604158 A2SCRDSI4: 8 Vector__XXX
 SG_ Atttt2DsExstFdAtQttOIttHRst : 0|16@1+ (0.001,0) [0|64.255] "g" Vector__XXX

BO_ 2364605438 GTRACE: 8 Vector__XXX
 SG_ GeneratorTripKvarHoursExport : 32|32@1+ (1,0) [0|4211081215] "kVArh" Vector__XXX
 SG_ GeneratorTripKwHoursExport : 0|32@1+ (1,0) [0|4211081215] "kWh" Vector__XXX

BO_ 2364605950 HPD: 8 Vector__XXX
 SG_ HydraulicLinePressure : 0|16@1+ (1,0) [0|64255] "kPa" Vector__XXX
 SG_ MechanicalMovementAngle : 16|16@1+ (0.0078125,0) [0|359.99] "deg" Vector__XXX

BO_ 2364606718 HVESSMS1: 8 Vector__XXX
 SG_ HvessModule1OperationalStatus : 0|2@1+ (1,0) [0|3] "" Vector__XXX
 SG_ HvessModule2OperationalStatus : 2|2@1+ (1,0) [0|3] "" Vector__XXX
 SG_ HvessModule3OperationalStatus : 4|2@1+ (1,0) [0|3] "" Vector__XXX
 SG_ HvessModule4OperationalStatus : 6|2@1+ (1,0) [0|3] "" Vector__XXX
 SG_ HvessModule5OperationalStatus : 8|2@1+ (1,0) [0|3] "" Vector__XXX
 SG_ HvessModule6OperationalStatus : 10|2@1+ (1,0) [0|3] "" Vector__XXX
 SG_ HvessModule7OperationalStatus : 12|2@1+ (1,0) [0|3] "" Vector__XXX
 SG_ HvessModule8OperationalStatus : 14|2@1+ (1,0) [0|3] "" Vector__XXX
 SG_ HvessModule9OperationalStatus : 16|2@1+ (1,0) [0|3] "" Vector__XXX
 SG_ HvessModule10OperationalStatus : 18|2@1+ (1,0) [0|3] "" Vector__XXX
 SG_ HvessModule11OperationalStatus : 20|2@1+ (1,0) [0|3] "" Vector__XXX
 SG_ HvessModule12OperationalStatus : 22|2@1+ (1,0) [0|3] "" Vector__XXX
 SG_ HvessModule13OperationalStatus : 24|2@1+ (1,0) [0|3] "" Vector__XXX
 SG_ HvessModule14OperationalStatus : 26|2@1+ (1,0) [0|3] "" Vector__XXX
 SG_ HvessModule15OperationalStatus : 28|2@1+ (1,0) [0|3] "" Vector__XXX
 SG_ HvessModule16OperationalStatus : 30|2@1+ (1,0) [0|3] "" Vector__XXX
 SG_ HvessModule17OperationalStatus : 32|2@1+ (1,0) [0|3] "" Vector__XXX
 SG_ HvessModule18OperationalStatus : 34|2@1+ (1,0) [0|3] "" Vector__XXX
 SG_ HvessModule19OperationalStatus : 36|2@1+ (1,0) [0|3] "" Vector__XXX
 SG_ HvessModule20OperationalStatus : 38|2@1+ (1,0) [0|3] "" Vector__XXX
 SG_ HvessModule21OperationalStatus : 40|2@1+ (1,0) [0|3] "" Vector__XXX
 SG_ HvessModule22OperationalStatus : 42|2@1+ (1,0) [0|3] "" Vector__XXX
 SG_ HvessModule23OperationalStatus : 44|2@1+ (1,0) [0|3] "" Vector__XXX
 SG_ HvessModule24OperationalStatus : 46|2@1+ (1,0) [0|3] "" Vector__XXX
 SG_ HvessModule25OperationalStatus : 48|2@1+ (1,0) [0|3] "" Vector__XXX
 SG_ HvessModule26OperationalStatus : 50|2@1+ (1,0) [0|3] "" Vector__XXX
 SG_ HvessModule27OperationalStatus : 52|2@1+ (1,0) [0|3] "" Vector__XXX
 SG_ HvessModule28OperationalStatus : 54|2@1+ (1,0) [0|3] "" Vector__XXX
 SG_ HvessModule29OperationalStatus : 56|2@1+ (1,0) [0|3] "" Vector__XXX
 SG_ HvessModule30OperationalStatus : 58|2@1+ (1,0) [0|3] "" Vector__XXX
 SG_ HvessModule31OperationalStatus : 60|2@1+ (1,0) [0|3] "" Vector__XXX
 SG_ HvessModule32OperationalStatus : 62|2@1+ (1,0) [0|3] "" Vector__XXX

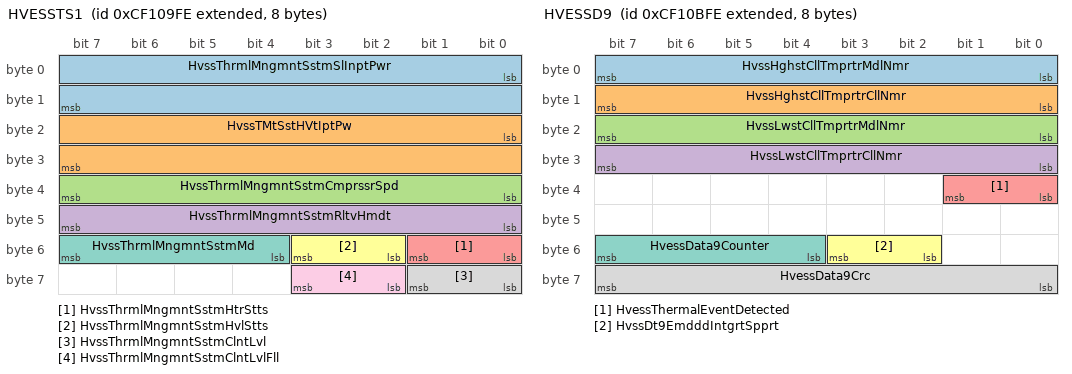
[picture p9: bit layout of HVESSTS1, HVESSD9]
BO_ 2364606974 HVESSTS1: 8 Vector__XXX
 SG_ HvssThrmlMngmntSstmSlInptPwr : 0|16@1+ (0.5,0) [0|32127.5] "W" Vector__XXX
 SG_ HvssTMtSstHVtIptPw : 16|16@1+ (0.5,0) [0|32127.5] "W" Vector__XXX
 SG_ HvssThrmlMngmntSstmCmprssrSpd : 32|8@1+ (32,0) [0|8000] "rpm" Vector__XXX
 SG_ HvssThrmlMngmntSstmRltvHmdt : 40|8@1+ (0.4,0) [0|100] "%" Vector__XXX
 SG_ HvssThrmlMngmntSstmHtrStts : 48|2@1+ (1,0) [0|3] "" Vector__XXX
 SG_ HvssThrmlMngmntSstmHvlStts : 50|2@1+ (1,0) [0|3] "" Vector__XXX
 SG_ HvssThrmlMngmntSstmMd : 52|4@1+ (1,0) [0|15] "" Vector__XXX
 SG_ HvssThrmlMngmntSstmClntLvl : 56|2@1+ (1,0) [0|3] "" Vector__XXX
 SG_ HvssThrmlMngmntSstmClntLvlFll : 58|2@1+ (1,0) [0|3] "" Vector__XXX

BO_ 2364607230 HVESSD8: 8 Vector__XXX
 SG_ HvessAverageCellVoltage : 32|16@1+ (0.001,0) [0|64.255] "V" Vector__XXX
 SG_ HvssHghstCllVltgMdlNmr : 0|8@1+ (1,0) [0|250] "count" Vector__XXX
 SG_ HvssHghstCllVltgCllNmr : 8|8@1+ (1,0) [0|250] "count" Vector__XXX
 SG_ HvssLwstCllVltgMdlNmr : 16|8@1+ (1,0) [0|250] "count" Vector__XXX
 SG_ HvssLwstCllVltgCllNmr : 24|8@1+ (1,0) [0|250] "count" Vector__XXX

BO_ 2364607486 HVESSD9: 8 Vector__XXX
 SG_ HvssHghstCllTmprtrMdlNmr : 0|8@1+ (1,0) [0|250] "count" Vector__XXX
 SG_ HvssHghstCllTmprtrCllNmr : 8|8@1+ (1,0) [0|250] "count" Vector__XXX
 SG_ HvssLwstCllTmprtrMdlNmr : 16|8@1+ (1,0) [0|250] "count" Vector__XXX
 SG_ HvssLwstCllTmprtrCllNmr : 24|8@1+ (1,0) [0|250] "count" Vector__XXX
 SG_ HvessThermalEventDetected : 32|2@1+ (1,0) [0|3] "" Vector__XXX
 SG_ HvssDt9EmdddIntgrtSpprt : 50|2@1+ (1,0) [0|3] "" Vector__XXX
 SG_ HvessData9Counter : 52|4@1+ (1,0) [0|15] "" Vector__XXX
 SG_ HvessData9Crc : 56|8@1+ (1,0) [0|250] "count" Vector__XXX

BO_ 2364607742 HVESSD10: 8 Vector__XXX
 SG_ HvssHghstCllSttOfChrgMdlNmr : 0|8@1+ (1,0) [0|250] "count" Vector__XXX
 SG_ HvssHghstCllSttOfChrgCllNmr : 8|8@1+ (1,0) [0|250] "count" Vector__XXX
 SG_ HvssLwstCllSttOfChrgMdlNmr : 16|8@1+ (1,0) [0|250] "count" Vector__XXX
 SG_ HvssLwstCllSttOfChrgCllNmr : 24|8@1+ (1,0) [0|250] "count" Vector__XXX
 SG_ HvssHghVltgBsAtvIsltnTstRslts : 32|16@1+ (0.1,0) [0|6425.5] "OhmPerV" Vector__XXX
 SG_ HvssHghVltgBsPssvIsltnTstRslts : 48|16@1+ (0.1,0) [0|6425.5] "OhmPerV" Vector__XXX

BO_ 2364608510 EOI2: 8 Vector__XXX
 SG_ EnginePowerDerateRequest : 16|16@1+ (0.5,0) [0|32127.5] "kW" Vector__XXX
 SG_ EngineSelfInducedDerateLoad : 0|16@1+ (0.5,0) [0|32127.5] "kW" Vector__XXX
 SG_ PwrtrnPrttnIsDsldDTChsssNtDttd : 34|2@1+ (1,0) [0|3] "" Vector__XXX
 SG_ EngineCoolantFlow : 36|2@1+ (1,0) [0|3] "" Vector__XXX
 SG_ AttttTMtEvtdIdStts : 32|2@1+ (1,0) [0|3] "" Vector__XXX

BO_ 2364609278 DCDC1C: 8 Vector__XXX
 SG_ DcDc1LowSideVoltageBuckSetpoint : 8|16@1+ (0.01,0) [0|642.55] "V" Vector__XXX
 SG_ DcDc1OperationalCommand : 0|4@1+ (1,0) [0|15] "" Vector__XXX
 SG_ DcDc1ControlCounter : 4|4@1+ (1,0) [0|15] "" Vector__XXX
 SG_ DcDc1ControlCrc : 56|8@1+ (1,0) [0|250] "count" Vector__XXX
 SG_ DD1HghSdVltgBstStpnt : 24|16@1+ (0.05,0) [0|3212.75] "V" Vector__XXX
 SG_ DD1LwSdVltgBkDfltStpnt : 40|16@1+ (0.01,0) [0|642.55] "V" Vector__XXX

BO_ 2364609534 DCDC1OS: 8 Vector__XXX
 SG_ DcDc1HvilStatus : 4|2@1+ (1,0) [0|3] "" Vector__XXX
 SG_ DcDc1LoadshedRequest : 6|2@1+ (1,0) [0|3] "" Vector__XXX
 SG_ DcDc1OperationalStatus : 0|4@1+ (1,0) [0|15] "" Vector__XXX
 SG_ DcDc1OperatingStatusCounter : 52|4@1+ (1,0) [0|15] "" Vector__XXX
 SG_ DcDc1OperatingStatusCrc : 56|8@1+ (1,0) [0|250] "count" Vector__XXX
 SG_ DD1PwrLmtDTHghSdCrrnt : 8|2@1+ (1,0) [0|3] "" Vector__XXX
 SG_ DD1PwrLmtDTLwSdCrrnt : 10|2@1+ (1,0) [0|3] "" Vector__XXX
 SG_ DD1PwrLmtDTHghSdVltgMnmm : 12|2@1+ (1,0) [0|3] "" Vector__XXX
 SG_ DD1PwrLmtDTHghSdVltgMxmm : 14|2@1+ (1,0) [0|3] "" Vector__XXX
 SG_ DD1PwrLmtDTLwSdVltgMnmm : 16|2@1+ (1,0) [0|3] "" Vector__XXX
 SG_ DD1PwrLmtDTLwSdVltgMxmm : 18|2@1+ (1,0) [0|3] "" Vector__XXX
 SG_ DD1PwrLmtDTCnvrtrTmprtr : 20|2@1+ (1,0) [0|3] "" Vector__XXX
 SG_ DD1PwrLmtDTEltrnFltrTmprtr : 22|2@1+ (1,0) [0|3] "" Vector__XXX
 SG_ DD1PwrLmtDTPwrEltrnsTmprtr : 24|2@1+ (1,0) [0|3] "" Vector__XXX
 SG_ DD1PwrLmtDTSlBttrTrmnlVltg : 26|2@1+ (1,0) [0|3] "" Vector__XXX
 SG_ DD1PwrLmtDTSlBttrTrmnlCrrnt : 28|2@1+ (1,0) [0|3] "" Vector__XXX
 SG_ DD1PwrLmtDTSlBttrTrmnlTmprtr : 30|2@1+ (1,0) [0|3] "" Vector__XXX
 SG_ DD1PwrLmtDTUndfndRsn : 32|2@1+ (1,0) [0|3] "" Vector__XXX

BO_ 2364609790 DCDC1VC: 8 Vector__XXX
 SG_ DcDc1HighSideCurrent : 48|16@1+ (0.1,-3212.7) [-3212.7|3212.8] "A" Vector__XXX
 SG_ DcDc1HighSideVoltage : 32|16@1+ (0.05,0) [0|3212.75] "V" Vector__XXX
 SG_ DcDc1LowSideCurrent : 16|16@1+ (0.1,-3212.7) [-3212.7|3212.8] "A" Vector__XXX
 SG_ DcDc1LowSideVoltage : 0|16@1+ (0.01,0) [0|642.55] "V" Vector__XXX

BO_ 2364610046 DCDC1SBS: 8 Vector__XXX
 SG_ DcDc1SliBatteryTerminalCurrent : 16|16@1+ (0.1,-3212.7) [-3212.7|3212.8] "A" Vector__XXX
 SG_ DcDc1SliBatteryTerminalVoltage : 0|16@1+ (0.01,0) [0|642.55] "V" Vector__XXX
 SG_ DD1SlBttrTrmnlTmprtr : 32|8@1+ (1,-40) [-40|210] "degC" Vector__XXX

BO_ 2364610558 DCDC1S2: 8 Vector__XXX
 SG_ DcDc1HighSidePower : 16|16@1+ (0.05,-1600) [-1600|1612.75] "kW" Vector__XXX
 SG_ DcDc1LowSidePower : 0|16@1+ (0.05,-1600) [-1600|1612.75] "kW" Vector__XXX
 SG_ DD1HghSdNgtvTChsssGrndVltg : 32|16@1+ (0.05,0) [0|3212.75] "V" Vector__XXX

BO_ 2364610814 DCDC2C: 8 Vector__XXX
 SG_ DcDc2LowSideVoltageBuckSetpoint : 8|16@1+ (0.01,0) [0|642.55] "V" Vector__XXX
 SG_ DcDc2OperationalCommand : 0|4@1+ (1,0) [0|15] "" Vector__XXX
 SG_ DcDc2ControlCounter : 4|4@1+ (1,0) [0|15] "" Vector__XXX
 SG_ DcDc2ControlCrc : 56|8@1+ (1,0) [0|250] "count" Vector__XXX
 SG_ DD2HghSdVltgBstStpnt : 24|16@1+ (0.05,0) [0|3212.75] "V" Vector__XXX
 SG_ DD2LwSdVltgBkDfltStpnt : 40|16@1+ (0.01,0) [0|642.55] "V" Vector__XXX

BO_ 2364611070 DCDC2OS: 8 Vector__XXX
 SG_ DcDc2HvilStatus : 4|2@1+ (1,0) [0|3] "" Vector__XXX
 SG_ DcDc2LoadshedRequest : 6|2@1+ (1,0) [0|3] "" Vector__XXX
 SG_ DcDc2OperationalStatus : 0|4@1+ (1,0) [0|15] "" Vector__XXX
 SG_ DcDc2OperatingStatusCounter : 52|4@1+ (1,0) [0|15] "" Vector__XXX
 SG_ DcDc2OperatingStatusCrc : 56|8@1+ (1,0) [0|250] "count" Vector__XXX
 SG_ DD2PwrLmtDTHghSdCrrnt : 8|2@1+ (1,0) [0|3] "" Vector__XXX
 SG_ DD2PwrLmtDTLwSdCrrnt : 10|2@1+ (1,0) [0|3] "" Vector__XXX
 SG_ DD2PwrLmtDTHghSdVltgMnmm : 12|2@1+ (1,0) [0|3] "" Vector__XXX
 SG_ DD2PwrLmtDTHghSdVltgMxmm : 14|2@1+ (1,0) [0|3] "" Vector__XXX
 SG_ DD2PwrLmtDTLwSdVltgMnmm : 16|2@1+ (1,0) [0|3] "" Vector__XXX
 SG_ DD2PwrLmtDTLwSdVltgMxmm : 18|2@1+ (1,0) [0|3] "" Vector__XXX
 SG_ DD2PwrLmtDTCnvrtrTmprtr : 20|2@1+ (1,0) [0|3] "" Vector__XXX
 SG_ DD2PwrLmtDTEltrnFltrTmprtr : 22|2@1+ (1,0) [0|3] "" Vector__XXX
 SG_ DD2PwrLmtDTPwrEltrnsTmprtr : 24|2@1+ (1,0) [0|3] "" Vector__XXX
 SG_ DD2PwrLmtDTSlBttrTrmnlVltg : 26|2@1+ (1,0) [0|3] "" Vector__XXX
 SG_ DD2PwrLmtDTSlBttrTrmnlCrrnt : 28|2@1+ (1,0) [0|3] "" Vector__XXX
 SG_ DD2PwrLmtDTSlBttrTrmnlTmprtr : 30|2@1+ (1,0) [0|3] "" Vector__XXX
 SG_ DD2PwrLmtDTUndfndRsn : 32|2@1+ (1,0) [0|3] "" Vector__XXX

BO_ 2364611326 DCDC2VC: 8 Vector__XXX
 SG_ DcDc2HighSideCurrent : 48|16@1+ (0.1,-3212.7) [-3212.7|3212.8] "A" Vector__XXX
 SG_ DcDc2HighSideVoltage : 32|16@1+ (0.05,0) [0|3212.75] "V" Vector__XXX
 SG_ DcDc2LowSideCurrent : 16|16@1+ (0.1,-3212.7) [-3212.7|3212.8] "A" Vector__XXX
 SG_ DcDc2LowSideVoltage : 0|16@1+ (0.01,0) [0|642.55] "V" Vector__XXX

BO_ 2364611582 DCDC2SBS: 8 Vector__XXX
 SG_ DcDc2SliBatteryTerminalCurrent : 16|16@1+ (0.1,-3212.7) [-3212.7|3212.8] "A" Vector__XXX
 SG_ DcDc2SliBatteryTerminalVoltage : 0|16@1+ (0.01,0) [0|642.55] "V" Vector__XXX
 SG_ DD2SlBttrTrmnlTmprtr : 32|8@1+ (1,-40) [-40|210] "degC" Vector__XXX

BO_ 2364611838 DCDC2S2: 8 Vector__XXX
 SG_ DcDc2HighSidePower : 16|16@1+ (0.05,-1600) [-1600|1612.75] "kW" Vector__XXX
 SG_ DcDc2LowSidePower : 0|16@1+ (0.05,-1600) [-1600|1612.75] "kW" Vector__XXX
 SG_ DD2HghSdNgtvTChsssGrndVltg : 32|16@1+ (0.05,0) [0|3212.75] "V" Vector__XXX

BO_ 2364612094 DCDC3C: 8 Vector__XXX
 SG_ DcDc3LowSideVoltageBuckSetpoint : 8|16@1+ (0.01,0) [0|642.55] "V" Vector__XXX
 SG_ DcDc3OperationalCommand : 0|4@1+ (1,0) [0|15] "" Vector__XXX
 SG_ DcDc3ControlCounter : 4|4@1+ (1,0) [0|15] "" Vector__XXX
 SG_ DcDc3ControlCrc : 56|8@1+ (1,0) [0|250] "count" Vector__XXX
 SG_ DD3HghSdVltgBstStpnt : 24|16@1+ (0.05,0) [0|3212.75] "V" Vector__XXX
 SG_ DD3LwSdVltgBkDfltStpnt : 40|16@1+ (0.01,0) [0|642.55] "V" Vector__XXX

BO_ 2364612350 DCDC3OS: 8 Vector__XXX
 SG_ DcDc3HvilStatus : 4|2@1+ (1,0) [0|3] "" Vector__XXX
 SG_ DcDc3LoadshedRequest : 6|2@1+ (1,0) [0|3] "" Vector__XXX
 SG_ DcDc3OperationalStatus : 0|4@1+ (1,0) [0|15] "" Vector__XXX
 SG_ DcDc3OperatingStatusCounter : 52|4@1+ (1,0) [0|15] "" Vector__XXX
 SG_ DcDc3OperatingStatusCrc : 56|8@1+ (1,0) [0|250] "count" Vector__XXX
 SG_ DD3PwrLmtDTHghSdCrrnt : 8|2@1+ (1,0) [0|3] "" Vector__XXX
 SG_ DD3PwrLmtDTLwSdCrrnt : 10|2@1+ (1,0) [0|3] "" Vector__XXX
 SG_ DD3PwrLmtDTHghSdVltgMnmm : 12|2@1+ (1,0) [0|3] "" Vector__XXX
 SG_ DD3PwrLmtDTHghSdVltgMxmm : 14|2@1+ (1,0) [0|3] "" Vector__XXX
 SG_ DD3PwrLmtDTLwSdVltgMnmm : 16|2@1+ (1,0) [0|3] "" Vector__XXX
 SG_ DD3PwrLmtDTLwSdVltgMxmm : 18|2@1+ (1,0) [0|3] "" Vector__XXX
 SG_ DD3PwrLmtDTCnvrtrTmprtr : 20|2@1+ (1,0) [0|3] "" Vector__XXX
 SG_ DD3PwrLmtDTEltrnFltrTmprtr : 22|2@1+ (1,0) [0|3] "" Vector__XXX
 SG_ DD3PwrLmtDTPwrEltrnsTmprtr : 24|2@1+ (1,0) [0|3] "" Vector__XXX
 SG_ DD3PwrLmtDTSlBttrTrmnlVltg : 26|2@1+ (1,0) [0|3] "" Vector__XXX
 SG_ DD3PwrLmtDTSlBttrTrmnlCrrnt : 28|2@1+ (1,0) [0|3] "" Vector__XXX
 SG_ DD3PwrLmtDTSlBttrTrmnlTmprtr : 30|2@1+ (1,0) [0|3] "" Vector__XXX
 SG_ DD3PwrLmtDTUndfndRsn : 32|2@1+ (1,0) [0|3] "" Vector__XXX

BO_ 2364612606 DCDC3VC: 8 Vector__XXX
 SG_ DcDc3HighSideCurrent : 48|16@1+ (0.1,-3212.7) [-3212.7|3212.8] "A" Vector__XXX
 SG_ DcDc3HighSideVoltage : 32|16@1+ (0.05,0) [0|3212.75] "V" Vector__XXX
 SG_ DcDc3LowSideCurrent : 16|16@1+ (0.1,-3212.7) [-3212.7|3212.8] "A" Vector__XXX
 SG_ DcDc3LowSideVoltage : 0|16@1+ (0.01,0) [0|642.55] "V" Vector__XXX

BO_ 2364612862 DCDC3SBS: 8 Vector__XXX
 SG_ DcDc3SliBatteryTerminalCurrent : 16|16@1+ (0.1,-3212.7) [-3212.7|3212.8] "A" Vector__XXX
 SG_ DcDc3SliBatteryTerminalVoltage : 0|16@1+ (0.01,0) [0|642.55] "V" Vector__XXX
 SG_ DD3SlBttrTrmnlTmprtr : 32|8@1+ (1,-40) [-40|210] "degC" Vector__XXX

BO_ 2364613118 DCDC3S2: 8 Vector__XXX
 SG_ DcDc3HighSidePower : 16|16@1+ (0.05,-1600) [-1600|1612.75] "kW" Vector__XXX
 SG_ DcDc3LowSidePower : 0|16@1+ (0.05,-1600) [-1600|1612.75] "kW" Vector__XXX
 SG_ DD3HghSdNgtvTChsssGrndVltg : 32|16@1+ (0.05,0) [0|3212.75] "V" Vector__XXX

BO_ 2364613374 DCDC4C: 8 Vector__XXX
 SG_ DcDc4LowSideVoltageBuckSetpoint : 8|16@1+ (0.01,0) [0|642.55] "V" Vector__XXX
 SG_ DcDc4OperationalCommand : 0|4@1+ (1,0) [0|15] "" Vector__XXX
 SG_ DcDc4ControlCounter : 4|4@1+ (1,0) [0|15] "" Vector__XXX
 SG_ DcDc4ControlCrc : 56|8@1+ (1,0) [0|250] "count" Vector__XXX
 SG_ DD4HghSdVltgBstStpnt : 24|16@1+ (0.05,0) [0|3212.75] "V" Vector__XXX
 SG_ DD4LwSdVltgBkDfltStpnt : 40|16@1+ (0.01,0) [0|642.55] "V" Vector__XXX

BO_ 2364613630 DCDC4OS: 8 Vector__XXX
 SG_ DcDc4HvilStatus : 4|2@1+ (1,0) [0|3] "" Vector__XXX
 SG_ DcDc4LoadshedRequest : 6|2@1+ (1,0) [0|3] "" Vector__XXX
 SG_ DcDc4OperationalStatus : 0|4@1+ (1,0) [0|15] "" Vector__XXX
 SG_ DcDc4OperatingStatusCounter : 52|4@1+ (1,0) [0|15] "" Vector__XXX
 SG_ DcDc4OperatingStatusCrc : 56|8@1+ (1,0) [0|250] "count" Vector__XXX
 SG_ DD4PwrLmtDTHghSdCrrnt : 8|2@1+ (1,0) [0|3] "" Vector__XXX
 SG_ DD4PwrLmtDTLwSdCrrnt : 10|2@1+ (1,0) [0|3] "" Vector__XXX
 SG_ DD4PwrLmtDTHghSdVltgMnmm : 12|2@1+ (1,0) [0|3] "" Vector__XXX
 SG_ DD4PwrLmtDTHghSdVltgMxmm : 14|2@1+ (1,0) [0|3] "" Vector__XXX
 SG_ DD4PwrLmtDTLwSdVltgMnmm : 16|2@1+ (1,0) [0|3] "" Vector__XXX
 SG_ DD4PwrLmtDTLwSdVltgMxmm : 18|2@1+ (1,0) [0|3] "" Vector__XXX
 SG_ DD4PwrLmtDTCnvrtrTmprtr : 20|2@1+ (1,0) [0|3] "" Vector__XXX
 SG_ DD4PwrLmtDTEltrnFltrTmprtr : 22|2@1+ (1,0) [0|3] "" Vector__XXX
 SG_ DD4PwrLmtDTPwrEltrnsTmprtr : 24|2@1+ (1,0) [0|3] "" Vector__XXX
 SG_ DD4PwrLmtDTSlBttrTrmnlVltg : 26|2@1+ (1,0) [0|3] "" Vector__XXX
 SG_ DD4PwrLmtDTSlBttrTrmnlCrrnt : 28|2@1+ (1,0) [0|3] "" Vector__XXX
 SG_ DD4PwrLmtDTSlBttrTrmnlTmprtr : 30|2@1+ (1,0) [0|3] "" Vector__XXX
 SG_ DD4PwrLmtDTUndfndRsn : 32|2@1+ (1,0) [0|3] "" Vector__XXX

BO_ 2364613886 DCDC4VC: 8 Vector__XXX
 SG_ DcDc4HighSideCurrent : 48|16@1+ (0.1,-3212.7) [-3212.7|3212.8] "A" Vector__XXX
 SG_ DcDc4HighSideVoltage : 32|16@1+ (0.05,0) [0|3212.75] "V" Vector__XXX
 SG_ DcDc4LowSideCurrent : 16|16@1+ (0.1,-3212.7) [-3212.7|3212.8] "A" Vector__XXX
 SG_ DcDc4LowSideVoltage : 0|16@1+ (0.01,0) [0|642.55] "V" Vector__XXX

BO_ 2364614142 DCDC4SBS: 8 Vector__XXX
 SG_ DcDc4SliBatteryTerminalCurrent : 16|16@1+ (0.1,-3212.7) [-3212.7|3212.8] "A" Vector__XXX
 SG_ DcDc4SliBatteryTerminalVoltage : 0|16@1+ (0.01,0) [0|642.55] "V" Vector__XXX
 SG_ DD4SlBttrTrmnlTmprtr : 32|8@1+ (1,-40) [-40|210] "degC" Vector__XXX

BO_ 2364614398 DCDC4S2: 8 Vector__XXX
 SG_ DcDc4HighSidePower : 16|16@1+ (0.05,-1600) [-1600|1612.75] "kW" Vector__XXX
 SG_ DcDc4LowSidePower : 0|16@1+ (0.05,-1600) [-1600|1612.75] "kW" Vector__XXX
 SG_ DD4HghSdNgtvTChsssGrndVltg : 32|16@1+ (0.05,0) [0|3212.75] "V" Vector__XXX

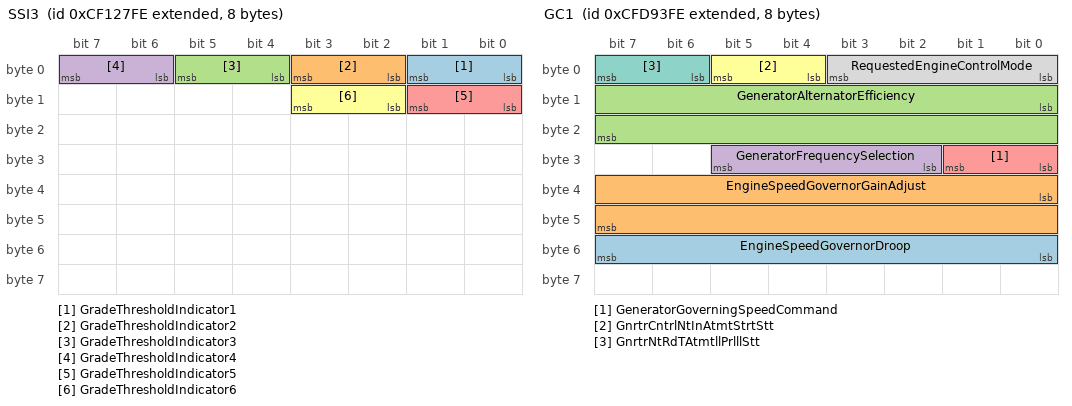
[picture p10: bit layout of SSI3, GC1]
BO_ 2364614654 SSI3: 8 Vector__XXX
 SG_ GradeThresholdIndicator1 : 0|2@1+ (1,0) [0|3] "" Vector__XXX
 SG_ GradeThresholdIndicator2 : 2|2@1+ (1,0) [0|3] "" Vector__XXX
 SG_ GradeThresholdIndicator3 : 4|2@1+ (1,0) [0|3] "" Vector__XXX
 SG_ GradeThresholdIndicator4 : 6|2@1+ (1,0) [0|3] "" Vector__XXX
 SG_ GradeThresholdIndicator5 : 8|2@1+ (1,0) [0|3] "" Vector__XXX
 SG_ GradeThresholdIndicator6 : 10|2@1+ (1,0) [0|3] "" Vector__XXX

BO_ 2364614910 DCACAI3S2: 8 Vector__XXX
 SG_ DAAssrInvrtr3DSdPwr : 0|16@1+ (0.0625,0) [0|4015.9375] "kW" Vector__XXX
 SG_ DAAssrInvrtr3DSdVltg : 16|16@1+ (0.05,0) [0|3212.75] "V" Vector__XXX
 SG_ DAAssrInvrtr3DSdCrrnt : 32|16@1+ (0.0625,0) [0|4015.9375] "A" Vector__XXX
 SG_ DAAssIvt3DSdNtvTCsssGdVt : 48|16@1+ (0.05,0) [0|3212.75] "V" Vector__XXX

BO_ 2364615166 DCACAI3V: 8 Vector__XXX
 SG_ DAAssrInvrtr3IgntnVltg : 0|16@1+ (0.05,0) [0|3212.75] "V" Vector__XXX
 SG_ DAAssrInvrtr3UnswthdSlVltg : 16|16@1+ (0.05,0) [0|3212.75] "V" Vector__XXX

BO_ 2364615678 DCACAI4S2: 8 Vector__XXX
 SG_ DAAssrInvrtr4DSdPwr : 0|16@1+ (0.0625,0) [0|4015.9375] "kW" Vector__XXX
 SG_ DAAssrInvrtr4DSdVltg : 16|16@1+ (0.05,0) [0|3212.75] "V" Vector__XXX
 SG_ DAAssrInvrtr4DSdCrrnt : 32|16@1+ (0.0625,0) [0|4015.9375] "A" Vector__XXX
 SG_ DAAssIvt4DSdNtvTCsssGdVt : 48|16@1+ (0.05,0) [0|3212.75] "V" Vector__XXX

BO_ 2364615934 DCACAI4V: 8 Vector__XXX
 SG_ DAAssrInvrtr4IgntnVltg : 0|16@1+ (0.05,0) [0|3212.75] "V" Vector__XXX
 SG_ DAAssrInvrtr4UnswthdSlVltg : 16|16@1+ (0.05,0) [0|3212.75] "V" Vector__XXX

BO_ 2364616958 DCACAI5S2: 8 Vector__XXX
 SG_ DAAssrInvrtr5DSdPwr : 0|16@1+ (0.0625,0) [0|4015.9375] "kW" Vector__XXX
 SG_ DAAssrInvrtr5DSdVltg : 16|16@1+ (0.05,0) [0|3212.75] "V" Vector__XXX
 SG_ DAAssrInvrtr5DSdCrrnt : 32|16@1+ (0.0625,0) [0|4015.9375] "A" Vector__XXX
 SG_ DAAssIvt5DSdNtvTCsssGdVt : 48|16@1+ (0.05,0) [0|3212.75] "V" Vector__XXX

BO_ 2364617214 DCACAI5V: 8 Vector__XXX
 SG_ DAAssrInvrtr5IgntnVltg : 0|16@1+ (0.05,0) [0|3212.75] "V" Vector__XXX
 SG_ DAAssrInvrtr5UnswthdSlVltg : 16|16@1+ (0.05,0) [0|3212.75] "V" Vector__XXX

BO_ 2365296894 DCDC4V: 8 Vector__XXX
 SG_ DD4CntrllrInptIgntnVltg : 0|16@1+ (0.05,0) [0|3212.75] "V" Vector__XXX
 SG_ DD4CntrllrInptUnswthdSlVltg : 16|16@1+ (0.05,0) [0|3212.75] "V" Vector__XXX

BO_ 2365297150 DCDC3V: 8 Vector__XXX
 SG_ DD3CntrllrInptIgntnVltg : 0|16@1+ (0.05,0) [0|3212.75] "V" Vector__XXX
 SG_ DD3CntrllrInptUnswthdSlVltg : 16|16@1+ (0.05,0) [0|3212.75] "V" Vector__XXX

BO_ 2365297406 DCDC2V: 8 Vector__XXX
 SG_ DD2CntrllrInptIgntnVltg : 0|16@1+ (0.05,0) [0|3212.75] "V" Vector__XXX
 SG_ DD2CntrllrInptUnswthdSlVltg : 16|16@1+ (0.05,0) [0|3212.75] "V" Vector__XXX

BO_ 2365297662 DCDC1V: 8 Vector__XXX
 SG_ DD1CntrllrInptIgntnVltg : 0|16@1+ (0.05,0) [0|3212.75] "V" Vector__XXX
 SG_ DD1CntrllrInptUnswthdSlVltg : 16|16@1+ (0.05,0) [0|3212.75] "V" Vector__XXX

BO_ 2365299454 DCACAI1DCL: 8 Vector__XXX
 SG_ DAAssrInvrtr1DSdVltgMnmmLmtRqst : 0|16@1+ (0.05,0) [0|3212.75] "V" Vector__XXX
 SG_ DAAssIvt1DSdCtMxLtRqst : 16|16@1+ (0.05,0) [0|3212.75] "A" Vector__XXX
 SG_ DAAssrInvrtr1DSdVltgMxmmLmtRqst : 32|16@1+ (0.05,0) [0|3212.75] "V" Vector__XXX
 SG_ DAAssIvt1DSdCtMLtRqst : 48|16@1+ (0.05,-3212.75) [-3212.75|0] "A" Vector__XXX

BO_ 2365299710 DCACAI1ACL: 8 Vector__XXX
 SG_ DAAssIvt1ASdRsVtMxLtRqst : 0|16@1+ (0.03125,0) [0|2007.96875] "V" Vector__XXX
 SG_ DAAssIvt1ASdRsCtMxLtRqst : 16|16@1+ (0.03125,0) [0|2007.96875] "A" Vector__XXX
 SG_ DAAssrInvrtr1ASdDfltFrqnRqst : 32|8@1+ (1,0) [0|250] "Hz" Vector__XXX

BO_ 2365300734 DCACAI2DCL: 8 Vector__XXX
 SG_ DAAssrInvrtr2DSdVltgMnmmLmtRqst : 0|16@1+ (0.05,0) [0|3212.75] "V" Vector__XXX
 SG_ DAAssIvt2DSdCtMxLtRqst : 16|16@1+ (0.05,0) [0|3212.75] "A" Vector__XXX
 SG_ DAAssrInvrtr2DSdVltgMxmmLmtRqst : 32|16@1+ (0.05,0) [0|3212.75] "V" Vector__XXX
 SG_ DAAssIvt2DSdCtMLtRqst : 48|16@1+ (0.05,-3212.75) [-3212.75|0] "A" Vector__XXX

BO_ 2365300990 DCACAI2ACL: 8 Vector__XXX
 SG_ DAAssIvt2ASdRsVtMxLtRqst : 0|16@1+ (0.03125,0) [0|2007.96875] "V" Vector__XXX
 SG_ DAAssIvt2ASdRsCtMxLtRqst : 16|16@1+ (0.03125,0) [0|2007.96875] "A" Vector__XXX
 SG_ DAAssrInvrtr2ASdDfltFrqnRqst : 32|8@1+ (1,0) [0|250] "Hz" Vector__XXX

BO_ 2365302014 DCACAI3DCL: 8 Vector__XXX
 SG_ DAAssrInvrtr3DSdVltgMnmmLmtRqst : 0|16@1+ (0.05,0) [0|3212.75] "V" Vector__XXX
 SG_ DAAssIvt3DSdCtMxLtRqst : 16|16@1+ (0.05,0) [0|3212.75] "A" Vector__XXX
 SG_ DAAssrInvrtr3DSdVltgMxmmLmtRqst : 32|16@1+ (0.05,0) [0|3212.75] "V" Vector__XXX
 SG_ DAAssIvt3DSdCtMLtRqst : 48|16@1+ (0.05,-3212.75) [-3212.75|0] "A" Vector__XXX

BO_ 2365302270 DCACAI3ACL: 8 Vector__XXX
 SG_ DAAssIvt3ASdRsVtMxLtRqst : 0|16@1+ (0.03125,0) [0|2007.96875] "V" Vector__XXX
 SG_ DAAssIvt3ASdRsCtMxLtRqst : 16|16@1+ (0.03125,0) [0|2007.96875] "A" Vector__XXX
 SG_ DAAssrInvrtr3ASdDfltFrqnRqst : 32|8@1+ (1,0) [0|250] "Hz" Vector__XXX

BO_ 2365303294 DCACAI4DCL: 8 Vector__XXX
 SG_ DAAssrInvrtr4DSdVltgMnmmLmtRqst : 0|16@1+ (0.05,0) [0|3212.75] "V" Vector__XXX
 SG_ DAAssIvt4DSdCtMxLtRqst : 16|16@1+ (0.05,0) [0|3212.75] "A" Vector__XXX
 SG_ DAAssrInvrtr4DSdVltgMxmmLmtRqst : 32|16@1+ (0.05,0) [0|3212.75] "V" Vector__XXX
 SG_ DAAssIvt4DSdCtMLtRqst : 48|16@1+ (0.05,-3212.75) [-3212.75|0] "A" Vector__XXX

BO_ 2365303550 DCACAI4ACL: 8 Vector__XXX
 SG_ DAAssIvt4ASdRsVtMxLtRqst : 0|16@1+ (0.03125,0) [0|2007.96875] "V" Vector__XXX
 SG_ DAAssIvt4ASdRsCtMxLtRqst : 16|16@1+ (0.03125,0) [0|2007.96875] "A" Vector__XXX
 SG_ DAAssrInvrtr4ASdDfltFrqnRqst : 32|8@1+ (1,0) [0|250] "Hz" Vector__XXX

BO_ 2365304574 DCACAI5DCL: 8 Vector__XXX
 SG_ DAAssrInvrtr5DSdVltgMnmmLmtRqst : 0|16@1+ (0.05,0) [0|3212.75] "V" Vector__XXX
 SG_ DAAssIvt5DSdCtMxLtRqst : 16|16@1+ (0.05,0) [0|3212.75] "A" Vector__XXX
 SG_ DAAssrInvrtr5DSdVltgMxmmLmtRqst : 32|16@1+ (0.05,0) [0|3212.75] "V" Vector__XXX
 SG_ DAAssIvt5DSdCtMLtRqst : 48|16@1+ (0.05,-3212.75) [-3212.75|0] "A" Vector__XXX

BO_ 2365304830 DCACAI5ACL: 8 Vector__XXX
 SG_ DAAssIvt5ASdRsVtMxLtRqst : 0|16@1+ (0.03125,0) [0|2007.96875] "V" Vector__XXX
 SG_ DAAssIvt5ASdRsCtMxLtRqst : 16|16@1+ (0.03125,0) [0|2007.96875] "A" Vector__XXX
 SG_ DAAssrInvrtr5ASdDfltFrqnRqst : 32|8@1+ (1,0) [0|250] "Hz" Vector__XXX

BO_ 2365307646 DCDC4SBL: 8 Vector__XXX
 SG_ DD4SlBttrTrmnlVltgMxmmLmtRqst : 0|16@1+ (0.01,0) [0|642.55] "V" Vector__XXX
 SG_ DD4SBttTCCtMxLtRqst : 16|16@1+ (0.05,0) [0|3212.75] "A" Vector__XXX
 SG_ DD4SlBttrTmprtrMxmmLmtRqst : 32|8@1+ (1,-40) [-40|210] "degC" Vector__XXX

BO_ 2365307902 DCDC4T: 8 Vector__XXX
 SG_ DcDc4ConverterTemperature : 0|8@1+ (1,-40) [-40|210] "degC" Vector__XXX
 SG_ DcDc4CoolantInTemperature : 24|8@1+ (1,-40) [-40|210] "degC" Vector__XXX
 SG_ DcDc4CoolantOutTemperature : 32|8@1+ (1,-40) [-40|210] "degC" Vector__XXX
 SG_ DD4CnvrtrEltrnFltrTmprtr : 8|8@1+ (1,-40) [-40|210] "degC" Vector__XXX
 SG_ DD4PwrEltrnsTmprtr : 16|8@1+ (1,-40) [-40|210] "degC" Vector__XXX

BO_ 2365308158 DCDC4LL: 8 Vector__XXX
 SG_ DD4LwSdVltgMnmmLmtRqst : 0|16@1+ (0.01,0) [0|642.55] "V" Vector__XXX
 SG_ DD4LwSdVltgMxmmLmtRqst : 16|16@1+ (0.01,0) [0|642.55] "V" Vector__XXX
 SG_ DD4LwSdCrrntMxmmLmtRqst : 32|16@1+ (0.05,0) [0|3212.75] "A" Vector__XXX
 SG_ DD4LwSdCrrntMnmmLmtRqst : 48|16@1+ (0.05,-3212.75) [-3212.75|0] "A" Vector__XXX

BO_ 2365308414 DCDC4HL: 8 Vector__XXX
 SG_ DD4HghSdVltgMnmmLmtRqst : 0|16@1+ (0.05,0) [0|3212.75] "V" Vector__XXX
 SG_ DD4HghSdVltgMxmmLmtRqst : 16|16@1+ (0.05,0) [0|3212.75] "V" Vector__XXX
 SG_ DD4HghSdCrrntMxmmLmtRqst : 32|16@1+ (0.05,0) [0|3212.75] "A" Vector__XXX
 SG_ DD4HghSdCrrntMnmmLmtRqst : 48|16@1+ (0.05,-3212.75) [-3212.75|0] "A" Vector__XXX

BO_ 2365309182 DCDC3SBL: 8 Vector__XXX
 SG_ DD3SlBttrTrmnlVltgMxmmLmtRqst : 0|16@1+ (0.01,0) [0|642.55] "V" Vector__XXX
 SG_ DD3SBttTCCtMxLtRqst : 16|16@1+ (0.05,0) [0|3212.75] "A" Vector__XXX
 SG_ DD3SlBttrTmprtrMxmmLmtRqst : 32|8@1+ (1,-40) [-40|210] "degC" Vector__XXX

BO_ 2365309438 DCDC3T: 8 Vector__XXX
 SG_ DcDc3ConverterTemperature : 0|8@1+ (1,-40) [-40|210] "degC" Vector__XXX
 SG_ DcDc3CoolantInTemperature : 24|8@1+ (1,-40) [-40|210] "degC" Vector__XXX
 SG_ DcDc3CoolantOutTemperature : 32|8@1+ (1,-40) [-40|210] "degC" Vector__XXX
 SG_ DD3CnvrtrEltrnFltrTmprtr : 8|8@1+ (1,-40) [-40|210] "degC" Vector__XXX
 SG_ DD3PwrEltrnsTmprtr : 16|8@1+ (1,-40) [-40|210] "degC" Vector__XXX

BO_ 2365309694 DCDC3LL: 8 Vector__XXX
 SG_ DD3LwSdVltgMnmmLmtRqst : 0|16@1+ (0.01,0) [0|642.55] "V" Vector__XXX
 SG_ DD3LwSdVltgMxmmLmtRqst : 16|16@1+ (0.01,0) [0|642.55] "V" Vector__XXX
 SG_ DD3LwSdCrrntMxmmLmtRqst : 32|16@1+ (0.05,0) [0|3212.75] "A" Vector__XXX
 SG_ DD3LwSdCrrntMnmmLmtRqst : 48|16@1+ (0.05,-3212.75) [-3212.75|0] "A" Vector__XXX

BO_ 2365309950 DCDC3HL: 8 Vector__XXX
 SG_ DD3HghSdVltgMnmmLmtRqst : 0|16@1+ (0.05,0) [0|3212.75] "V" Vector__XXX
 SG_ DD3HghSdVltgMxmmLmtRqst : 16|16@1+ (0.05,0) [0|3212.75] "V" Vector__XXX
 SG_ DD3HghSdCrrntMxmmLmtRqst : 32|16@1+ (0.05,0) [0|3212.75] "A" Vector__XXX
 SG_ DD3HghSdCrrntMnmmLmtRqst : 48|16@1+ (0.05,-3212.75) [-3212.75|0] "A" Vector__XXX

BO_ 2365310718 DCDC2SBL: 8 Vector__XXX
 SG_ DD2SlBttrTrmnlVltgMxmmLmtRqst : 0|16@1+ (0.01,0) [0|642.55] "V" Vector__XXX
 SG_ DD2SBttTCCtMxLtRqst : 16|16@1+ (0.05,0) [0|3212.75] "A" Vector__XXX
 SG_ DD2SlBttrTmprtrMxmmLmtRqst : 32|8@1+ (1,-40) [-40|210] "degC" Vector__XXX

BO_ 2365310974 DCDC2T: 8 Vector__XXX
 SG_ DcDc2ConverterTemperature : 0|8@1+ (1,-40) [-40|210] "degC" Vector__XXX
 SG_ DcDc2CoolantInTemperature : 24|8@1+ (1,-40) [-40|210] "degC" Vector__XXX
 SG_ DcDc2CoolantOutTemperature : 32|8@1+ (1,-40) [-40|210] "degC" Vector__XXX
 SG_ DD2CnvrtrEltrnFltrTmprtr : 8|8@1+ (1,-40) [-40|210] "degC" Vector__XXX
 SG_ DD2PwrEltrnsTmprtr : 16|8@1+ (1,-40) [-40|210] "degC" Vector__XXX

BO_ 2365311230 DCDC2LL: 8 Vector__XXX
 SG_ DD2LwSdVltgMnmmLmtRqst : 0|16@1+ (0.01,0) [0|642.55] "V" Vector__XXX
 SG_ DD2LwSdVltgMxmmLmtRqst : 16|16@1+ (0.01,0) [0|642.55] "V" Vector__XXX
 SG_ DD2LwSdCrrntMxmmLmtRqst : 32|16@1+ (0.05,0) [0|3212.75] "A" Vector__XXX
 SG_ DD2LwSdCrrntMnmmLmtRqst : 48|16@1+ (0.05,-3212.75) [-3212.75|0] "A" Vector__XXX

BO_ 2365311486 DCDC2HL: 8 Vector__XXX
 SG_ DD2HghSdVltgMnmmLmtRqst : 0|16@1+ (0.05,0) [0|3212.75] "V" Vector__XXX
 SG_ DD2HghSdVltgMxmmLmtRqst : 16|16@1+ (0.05,0) [0|3212.75] "V" Vector__XXX
 SG_ DD2HghSdCrrntMxmmLmtRqst : 32|16@1+ (0.05,0) [0|3212.75] "A" Vector__XXX
 SG_ DD2HghSdCrrntMnmmLmtRqst : 48|16@1+ (0.05,-3212.75) [-3212.75|0] "A" Vector__XXX

BO_ 2365313534 DCDC1SBL: 8 Vector__XXX
 SG_ DD1SlBttrTrmnlVltgMxmmLmtRqst : 0|16@1+ (0.01,0) [0|642.55] "V" Vector__XXX
 SG_ DD1SBttTCCtMxLtRqst : 16|16@1+ (0.05,0) [0|3212.75] "A" Vector__XXX
 SG_ DD1SlBttrTmprtrMxmmLmtRqst : 32|8@1+ (1,-40) [-40|210] "degC" Vector__XXX

BO_ 2365315326 DCDC1T: 8 Vector__XXX
 SG_ DcDc1ConverterTemperature : 0|8@1+ (1,-40) [-40|210] "degC" Vector__XXX
 SG_ DcDc1CoolantInTemperature : 24|8@1+ (1,-40) [-40|210] "degC" Vector__XXX
 SG_ DcDc1CoolantOutTemperature : 32|8@1+ (1,-40) [-40|210] "degC" Vector__XXX
 SG_ DD1CnvrtrEltrnFltrTmprtr : 8|8@1+ (1,-40) [-40|210] "degC" Vector__XXX
 SG_ DD1PwrEltrnsTmprtr : 16|8@1+ (1,-40) [-40|210] "degC" Vector__XXX

BO_ 2365315582 DCDC1LL: 8 Vector__XXX
 SG_ DD1LwSdVltgMnmmLmtRqst : 0|16@1+ (0.01,0) [0|642.55] "V" Vector__XXX
 SG_ DD1LwSdVltgMxmmLmtRqst : 16|16@1+ (0.01,0) [0|642.55] "V" Vector__XXX
 SG_ DD1LwSdCrrntMxmmLmtRqst : 32|16@1+ (0.05,0) [0|3212.75] "A" Vector__XXX
 SG_ DD1LwSdCrrntMnmmLmtRqst : 48|16@1+ (0.05,-3212.75) [-3212.75|0] "A" Vector__XXX

BO_ 2365315838 DCDC1HL: 8 Vector__XXX
 SG_ DD1HghSdVltgMnmmLmtRqst : 0|16@1+ (0.05,0) [0|3212.75] "V" Vector__XXX
 SG_ DD1HghSdVltgMxmmLmtRqst : 16|16@1+ (0.05,0) [0|3212.75] "V" Vector__XXX
 SG_ DD1HghSdCrrntMxmmLmtRqst : 32|16@1+ (0.05,0) [0|3212.75] "A" Vector__XXX
 SG_ DD1HghSdCrrntMnmmLmtRqst : 48|16@1+ (0.05,-3212.75) [-3212.75|0] "A" Vector__XXX

BO_ 2365322238 CCVS5: 8 Vector__XXX
 SG_ DirectionalVehicleSpeed : 0|16@1+ (0.0078125,-250) [-250|251.9921875] "km/h" Vector__XXX

BO_ 2365346302 ASC7: 8 Vector__XXX
 SG_ LiftAxle1Status : 0|3@1+ (1,0) [0|7] "" Vector__XXX
 SG_ LiftAxle2Status : 3|3@1+ (1,0) [0|7] "" Vector__XXX
 SG_ LiftAxle3Status : 8|3@1+ (1,0) [0|7] "" Vector__XXX
 SG_ LiftAxle4Status : 11|3@1+ (1,0) [0|7] "" Vector__XXX

BO_ 2365348350 ELS: 8 Vector__XXX
 SG_ EngineLoadShareStatus : 2|4@1+ (1,0) [0|15] "" Vector__XXX
 SG_ EngineUnloadStatus : 0|2@1+ (1,0) [0|3] "" Vector__XXX
 SG_ LoadShareActiveCircuit : 6|2@1+ (1,0) [0|3] "" Vector__XXX

BO_ 2365363710 ECPMSI: 8 Vector__XXX
 SG_ EngnClndrPrssrMntr1PrlmnrFm : 0|5@1+ (1,0) [0|31] "" Vector__XXX
 SG_ EngnClndrPrssrMntr2PrlmnrFm : 8|5@1+ (1,0) [0|31] "" Vector__XXX

BO_ 2365374206 ETC9: 8 Vector__XXX
 SG_ DlClthTrnsmssnCrrntPrSltnGr : 40|8@1+ (1,-125) [-125|125] "gear value" Vector__XXX
 SG_ DlClthTrnsmssnInptShft1Spd : 0|16@1+ (0.125,0) [0|8031.875] "rpm" Vector__XXX
 SG_ DlClthTrnsmssnInptShft2Spd : 16|16@1+ (0.125,0) [0|8031.875] "rpm" Vector__XXX
 SG_ DlClthTrnsmssnSltdPrSltnGr : 32|8@1+ (1,-125) [-125|125] "gear value" Vector__XXX

BO_ 2365393662 AT2OGC2: 8 Vector__XXX
 SG_ Atttt2OttNxSsO2PssCt : 0|8@1+ (0.5,0) [0|125] "%/bar" Vector__XXX
 SG_ Atttt2OttNxSsNxPssCt : 8|8@1+ (0.5,0) [0|125] "%/bar" Vector__XXX
 SG_ Aftrtrtmnt2OtltNxSnsrN2Crrtn : 16|8@1+ (0.5,0) [0|125] "%" Vector__XXX
 SG_ Aftrtrtmnt2OtltNxSnsrNh3Crrtn : 24|8@1+ (0.5,0) [0|125] "%" Vector__XXX
 SG_ Atttt2OttNxSsSDssFRst : 32|8@1+ (1,0) [0|250] "" Vector__XXX
 SG_ Aftrtrtmnt2OtltCrrtdNx : 40|16@1+ (0.05,-200) [-200|3012.75] "ppm" Vector__XXX

BO_ 2365393918 AT2OGC1: 8 Vector__XXX
 SG_ Aftrtrtmnt2OtltNxSnsrHtrRt : 0|16@1+ (0.001,0) [0|64.255] "" Vector__XXX
 SG_ Atttt2OttNxSsNwPtDvtNxG : 16|16@1+ (0.1,-100) [-100|100] "%" Vector__XXX
 SG_ Atttt2OttNxSsNwPtDvtNxOst : 32|8@1+ (1,-125) [-125|125] "ppm" Vector__XXX
 SG_ Aftrtrtmnt2OtltNxSnsrOprtnHrs : 40|16@1+ (1,0) [0|64255] "h" Vector__XXX

BO_ 2365394174 AT2IGC2: 8 Vector__XXX
 SG_ EngineExhaust2CorrectedNox : 40|16@1+ (0.05,-200) [-200|3012.75] "ppm" Vector__XXX
 SG_ EngnExhst2NxSnsrO2PrssrCrrtn : 0|8@1+ (0.5,0) [0|125] "%/bar" Vector__XXX
 SG_ EngnExhst2NxSnsrNxPrssrCrrtn : 8|8@1+ (0.5,0) [0|125] "%/bar" Vector__XXX
 SG_ EngnExhst2NxSnsrN2Crrtn : 16|8@1+ (0.5,0) [0|125] "%" Vector__XXX
 SG_ EngnExhst2NxSnsrNh3Crrtn : 24|8@1+ (0.5,0) [0|125] "%" Vector__XXX
 SG_ EngnExhst2NxSnsrSlfDgnssFnlRslt : 32|8@1+ (1,0) [0|250] "" Vector__XXX

BO_ 2365394430 AT2IGC1: 8 Vector__XXX
 SG_ EngnExhst2NxSnsrHtrRt : 0|16@1+ (0.001,0) [0|64.255] "" Vector__XXX
 SG_ EngnExhst2NxSnsrNwPrtDvtnNxGn : 16|16@1+ (0.1,-100) [-100|100] "%" Vector__XXX
 SG_ EExst2NxSsNwPtDvtNxOst : 32|8@1+ (1,-125) [-125|125] "ppm" Vector__XXX
 SG_ EngnExhst2NxSnsrOprtnHrs : 40|16@1+ (1,0) [0|64255] "h" Vector__XXX

BO_ 2365394686 AT1OGC2: 8 Vector__XXX
 SG_ Atttt1OttNxSsO2PssCt : 0|8@1+ (0.5,0) [0|125] "%/bar" Vector__XXX
 SG_ Atttt1OttNxSsNxPssCt : 8|8@1+ (0.5,0) [0|125] "%/bar" Vector__XXX
 SG_ Aftrtrtmnt1OtltNxSnsrN2Crrtn : 16|8@1+ (0.5,0) [0|125] "%" Vector__XXX
 SG_ Aftrtrtmnt1OtltNxSnsrNh3Crrtn : 24|8@1+ (0.5,0) [0|125] "%" Vector__XXX
 SG_ Atttt1OttNxSsSDssFRst : 32|8@1+ (1,0) [0|250] "" Vector__XXX
 SG_ Aftrtrtmnt1OtltCrrtdNx : 40|16@1+ (0.05,-200) [-200|3012.75] "ppm" Vector__XXX

BO_ 2365394942 AT1OGC1: 8 Vector__XXX
 SG_ Aftrtrtmnt1OtltNxSnsrHtrRt : 0|16@1+ (0.001,0) [0|64.255] "" Vector__XXX
 SG_ Atttt1OttNxSsNwPtDvtNxG : 16|16@1+ (0.1,-100) [-100|100] "%" Vector__XXX
 SG_ Atttt1OttNxSsNwPtDvtNxOst : 32|8@1+ (1,-125) [-125|125] "ppm" Vector__XXX
 SG_ Aftrtrtmnt1OtltNxSnsrOprtnHrs : 40|16@1+ (1,0) [0|64255] "h" Vector__XXX

BO_ 2365395198 AT1IGC2: 8 Vector__XXX
 SG_ EngineExhaust1CorrectedNox : 40|16@1+ (0.05,-200) [-200|3012.75] "ppm" Vector__XXX
 SG_ EngnExhst1NxSnsrO2PrssrCrrtn : 0|8@1+ (0.5,0) [0|125] "%/bar" Vector__XXX
 SG_ EngnExhst1NxSnsrNxPrssrCrrtn : 8|8@1+ (0.5,0) [0|125] "%/bar" Vector__XXX
 SG_ EngnExhst1NxSnsrN2Crrtn : 16|8@1+ (0.5,0) [0|125] "%" Vector__XXX
 SG_ EngnExhst1NxSnsrNh3Crrtn : 24|8@1+ (0.5,0) [0|125] "%" Vector__XXX
 SG_ EngnExhst1NxSnsrSlfDgnssFnlRslt : 32|8@1+ (1,0) [0|250] "" Vector__XXX

BO_ 2365395454 AT1IGC1: 8 Vector__XXX
 SG_ EngnExhst1NxSnsrHtrRt : 0|16@1+ (0.001,0) [0|64.255] "" Vector__XXX
 SG_ EngnExhst1NxSnsrNwPrtDvtnNxGn : 16|16@1+ (0.1,-100) [-100|100] "%" Vector__XXX
 SG_ EExst1NxSsNwPtDvtNxOst : 32|8@1+ (1,-125) [-125|125] "ppm" Vector__XXX
 SG_ EngnExhst1NxSnsrOprtnHrs : 40|16@1+ (1,0) [0|64255] "h" Vector__XXX

BO_ 2365400062 EJM10: 8 Vector__XXX
 SG_ Joystick10Button13PressedStatus : 62|2@1+ (1,0) [0|3] "" Vector__XXX
 SG_ Joystick10Button14PressedStatus : 60|2@1+ (1,0) [0|3] "" Vector__XXX
 SG_ Joystick10Button15PressedStatus : 58|2@1+ (1,0) [0|3] "" Vector__XXX
 SG_ Joystick10Button16PressedStatus : 56|2@1+ (1,0) [0|3] "" Vector__XXX
 SG_ Joystick10GripXAxisPosition : 6|10@1+ (0.1,0) [0|102] "%" Vector__XXX
 SG_ Joystick10GripYAxisPosition : 22|10@1+ (0.1,0) [0|102] "%" Vector__XXX
 SG_ Joystick10ThetaAxisPosition : 38|10@1+ (0.1,0) [0|102] "%" Vector__XXX
 SG_ Jst10GpXAxsLvRtPstvPstStts : 4|2@1+ (1,0) [0|3] "" Vector__XXX
 SG_ Jst10GpYAxsLvFwdPstvPstStts : 20|2@1+ (1,0) [0|3] "" Vector__XXX
 SG_ Jst10TtAxsCtCwsNtvPstStts : 34|2@1+ (1,0) [0|3] "" Vector__XXX
 SG_ Jstk10GrpXAxsDtntPstnStts : 54|2@1+ (1,0) [0|3] "" Vector__XXX
 SG_ Jstk10GrpXAxsLvrLftNgtvPstnStts : 2|2@1+ (1,0) [0|3] "" Vector__XXX
 SG_ Jstk10GrpXAxsNtrlPstnStts : 0|2@1+ (1,0) [0|3] "" Vector__XXX
 SG_ Jstk10GrpYAxsDtntPstnStts : 52|2@1+ (1,0) [0|3] "" Vector__XXX
 SG_ Jstk10GrpYAxsLvrBkNgtvPstnStts : 18|2@1+ (1,0) [0|3] "" Vector__XXX
 SG_ Jstk10GrpYAxsNtrlPstnStts : 16|2@1+ (1,0) [0|3] "" Vector__XXX
 SG_ Jstk10ThtAxsClkwsPstvPstnStts : 36|2@1+ (1,0) [0|3] "" Vector__XXX
 SG_ Jstk10ThtAxsDtntPstnStts : 50|2@1+ (1,0) [0|3] "" Vector__XXX
 SG_ Jstk10ThtAxsNtrlPstnStts : 32|2@1+ (1,0) [0|3] "" Vector__XXX

BO_ 2365400318 BJM10: 8 Vector__XXX
 SG_ Joystick10Button10PressedStatus : 60|2@1+ (1,0) [0|3] "" Vector__XXX
 SG_ Joystick10Button11PressedStatus : 58|2@1+ (1,0) [0|3] "" Vector__XXX
 SG_ Joystick10Button12PressedStatus : 56|2@1+ (1,0) [0|3] "" Vector__XXX
 SG_ Joystick10Button1PressedStatus : 46|2@1+ (1,0) [0|3] "" Vector__XXX
 SG_ Joystick10Button2PressedStatus : 44|2@1+ (1,0) [0|3] "" Vector__XXX
 SG_ Joystick10Button3PressedStatus : 42|2@1+ (1,0) [0|3] "" Vector__XXX
 SG_ Joystick10Button4PressedStatus : 40|2@1+ (1,0) [0|3] "" Vector__XXX
 SG_ Joystick10Button5PressedStatus : 54|2@1+ (1,0) [0|3] "" Vector__XXX
 SG_ Joystick10Button6PressedStatus : 52|2@1+ (1,0) [0|3] "" Vector__XXX
 SG_ Joystick10Button7PressedStatus : 50|2@1+ (1,0) [0|3] "" Vector__XXX
 SG_ Joystick10Button8PressedStatus : 48|2@1+ (1,0) [0|3] "" Vector__XXX
 SG_ Joystick10Button9PressedStatus : 62|2@1+ (1,0) [0|3] "" Vector__XXX
 SG_ Joystick10XAxisPosition : 6|10@1+ (0.1,0) [0|102] "%" Vector__XXX
 SG_ Joystick10YAxisPosition : 22|10@1+ (0.1,0) [0|102] "%" Vector__XXX
 SG_ Jstk10XAxsDtntPstnStts : 38|2@1+ (1,0) [0|3] "" Vector__XXX
 SG_ Jstk10XAxsLvrLftNgtvPstnStts : 2|2@1+ (1,0) [0|3] "" Vector__XXX
 SG_ Jstk10XAxsLvrRghtPstvPstnStts : 4|2@1+ (1,0) [0|3] "" Vector__XXX
 SG_ Jstk10XAxsNtrlPstnStts : 0|2@1+ (1,0) [0|3] "" Vector__XXX
 SG_ Jstk10YAxsDtntPstnStts : 36|2@1+ (1,0) [0|3] "" Vector__XXX
 SG_ Jstk10YAxsLvrBkNgtvPstnStts : 18|2@1+ (1,0) [0|3] "" Vector__XXX
 SG_ Jstk10YAxsLvrFrwrdPstvPstnStts : 20|2@1+ (1,0) [0|3] "" Vector__XXX
 SG_ Jstk10YAxsNtrlPstnStts : 16|2@1+ (1,0) [0|3] "" Vector__XXX

BO_ 2365400574 EJM9: 8 Vector__XXX
 SG_ Joystick9Button13PressedStatus : 62|2@1+ (1,0) [0|3] "" Vector__XXX
 SG_ Joystick9Button14PressedStatus : 60|2@1+ (1,0) [0|3] "" Vector__XXX
 SG_ Joystick9Button15PressedStatus : 58|2@1+ (1,0) [0|3] "" Vector__XXX
 SG_ Joystick9Button16PressedStatus : 56|2@1+ (1,0) [0|3] "" Vector__XXX
 SG_ Joystick9GripXAxisPosition : 6|10@1+ (0.1,0) [0|102] "%" Vector__XXX
 SG_ Joystick9GripYAxisPosition : 22|10@1+ (0.1,0) [0|102] "%" Vector__XXX
 SG_ Joystick9ThetaAxisPosition : 38|10@1+ (0.1,0) [0|102] "%" Vector__XXX
 SG_ Jst9GpYAxsLvFwdPstvPstStts : 20|2@1+ (1,0) [0|3] "" Vector__XXX
 SG_ Jst9TtAxsCtCwsNtvPstStts : 34|2@1+ (1,0) [0|3] "" Vector__XXX
 SG_ Jstk9GrpXAxsDtntPstnStts : 54|2@1+ (1,0) [0|3] "" Vector__XXX
 SG_ Jstk9GrpXAxsLvrLftNgtvPstnStts : 2|2@1+ (1,0) [0|3] "" Vector__XXX
 SG_ Jstk9GrpXAxsLvrRghtPstvPstnStts : 4|2@1+ (1,0) [0|3] "" Vector__XXX
 SG_ Jstk9GrpXAxsNtrlPstnStts : 0|2@1+ (1,0) [0|3] "" Vector__XXX
 SG_ Jstk9GrpYAxsDtntPstnStts : 52|2@1+ (1,0) [0|3] "" Vector__XXX
 SG_ Jstk9GrpYAxsLvrBkNgtvPstnStts : 18|2@1+ (1,0) [0|3] "" Vector__XXX
 SG_ Jstk9GrpYAxsNtrlPstnStts : 16|2@1+ (1,0) [0|3] "" Vector__XXX
 SG_ Jstk9ThtAxsClkwsPstvPstnStts : 36|2@1+ (1,0) [0|3] "" Vector__XXX
 SG_ Jstk9ThtAxsDtntPstnStts : 50|2@1+ (1,0) [0|3] "" Vector__XXX
 SG_ Jstk9ThtAxsNtrlPstnStts : 32|2@1+ (1,0) [0|3] "" Vector__XXX

BO_ 2365400830 BJM9: 8 Vector__XXX
 SG_ Joystick9Button10PressedStatus : 60|2@1+ (1,0) [0|3] "" Vector__XXX
 SG_ Joystick9Button11PressedStatus : 58|2@1+ (1,0) [0|3] "" Vector__XXX
 SG_ Joystick9Button12PressedStatus : 56|2@1+ (1,0) [0|3] "" Vector__XXX
 SG_ Joystick9Button1PressedStatus : 46|2@1+ (1,0) [0|3] "" Vector__XXX
 SG_ Joystick9Button2PressedStatus : 44|2@1+ (1,0) [0|3] "" Vector__XXX
 SG_ Joystick9Button3PressedStatus : 42|2@1+ (1,0) [0|3] "" Vector__XXX
 SG_ Joystick9Button4PressedStatus : 40|2@1+ (1,0) [0|3] "" Vector__XXX
 SG_ Joystick9Button5PressedStatus : 54|2@1+ (1,0) [0|3] "" Vector__XXX
 SG_ Joystick9Button6PressedStatus : 52|2@1+ (1,0) [0|3] "" Vector__XXX
 SG_ Joystick9Button7PressedStatus : 50|2@1+ (1,0) [0|3] "" Vector__XXX
 SG_ Joystick9Button8PressedStatus : 48|2@1+ (1,0) [0|3] "" Vector__XXX
 SG_ Joystick9Button9PressedStatus : 62|2@1+ (1,0) [0|3] "" Vector__XXX
 SG_ Joystick9XAxisPosition : 6|10@1+ (0.1,0) [0|102] "%" Vector__XXX
 SG_ Joystick9YAxisPosition : 22|10@1+ (0.1,0) [0|102] "%" Vector__XXX
 SG_ Jstk9XAxsDtntPstnStts : 38|2@1+ (1,0) [0|3] "" Vector__XXX
 SG_ Jstk9XAxsLvrLftNgtvPstnStts : 2|2@1+ (1,0) [0|3] "" Vector__XXX
 SG_ Jstk9XAxsLvrRghtPstvPstnStts : 4|2@1+ (1,0) [0|3] "" Vector__XXX
 SG_ Jstk9XAxsNtrlPstnStts : 0|2@1+ (1,0) [0|3] "" Vector__XXX
 SG_ Jstk9YAxsDtntPstnStts : 36|2@1+ (1,0) [0|3] "" Vector__XXX
 SG_ Jstk9YAxsLvrBkNgtvPstnStts : 18|2@1+ (1,0) [0|3] "" Vector__XXX
 SG_ Jstk9YAxsLvrFrwrdPstvPstnStts : 20|2@1+ (1,0) [0|3] "" Vector__XXX
 SG_ Jstk9YAxsNtrlPstnStts : 16|2@1+ (1,0) [0|3] "" Vector__XXX

BO_ 2365401086 EJM8: 8 Vector__XXX
 SG_ Joystick8Button13PressedStatus : 62|2@1+ (1,0) [0|3] "" Vector__XXX
 SG_ Joystick8Button14PressedStatus : 60|2@1+ (1,0) [0|3] "" Vector__XXX
 SG_ Joystick8Button15PressedStatus : 58|2@1+ (1,0) [0|3] "" Vector__XXX
 SG_ Joystick8Button16PressedStatus : 56|2@1+ (1,0) [0|3] "" Vector__XXX
 SG_ Joystick8GripXAxisPosition : 6|10@1+ (0.1,0) [0|102] "%" Vector__XXX
 SG_ Joystick8GripYAxisPosition : 22|10@1+ (0.1,0) [0|102] "%" Vector__XXX
 SG_ Joystick8ThetaAxisPosition : 38|10@1+ (0.1,0) [0|102] "%" Vector__XXX
 SG_ Jst8GpYAxsLvFwdPstvPstStts : 20|2@1+ (1,0) [0|3] "" Vector__XXX
 SG_ Jst8TtAxsCtCwsNtvPstStts : 34|2@1+ (1,0) [0|3] "" Vector__XXX
 SG_ Jstk8GrpXAxsDtntPstnStts : 54|2@1+ (1,0) [0|3] "" Vector__XXX
 SG_ Jstk8GrpXAxsLvrLftNgtvPstnStts : 2|2@1+ (1,0) [0|3] "" Vector__XXX
 SG_ Jstk8GrpXAxsLvrRghtPstvPstnStts : 4|2@1+ (1,0) [0|3] "" Vector__XXX
 SG_ Jstk8GrpXAxsNtrlPstnStts : 0|2@1+ (1,0) [0|3] "" Vector__XXX
 SG_ Jstk8GrpYAxsDtntPstnStts : 52|2@1+ (1,0) [0|3] "" Vector__XXX
 SG_ Jstk8GrpYAxsLvrBkNgtvPstnStts : 18|2@1+ (1,0) [0|3] "" Vector__XXX
 SG_ Jstk8GrpYAxsNtrlPstnStts : 16|2@1+ (1,0) [0|3] "" Vector__XXX
 SG_ Jstk8ThtAxsClkwsPstvPstnStts : 36|2@1+ (1,0) [0|3] "" Vector__XXX
 SG_ Jstk8ThtAxsDtntPstnStts : 50|2@1+ (1,0) [0|3] "" Vector__XXX
 SG_ Jstk8ThtAxsNtrlPstnStts : 32|2@1+ (1,0) [0|3] "" Vector__XXX

BO_ 2365401342 BJM8: 8 Vector__XXX
 SG_ Joystick8Button10PressedStatus : 60|2@1+ (1,0) [0|3] "" Vector__XXX
 SG_ Joystick8Button11PressedStatus : 58|2@1+ (1,0) [0|3] "" Vector__XXX
 SG_ Joystick8Button12PressedStatus : 56|2@1+ (1,0) [0|3] "" Vector__XXX
 SG_ Joystick8Button1PressedStatus : 46|2@1+ (1,0) [0|3] "" Vector__XXX
 SG_ Joystick8Button2PressedStatus : 44|2@1+ (1,0) [0|3] "" Vector__XXX
 SG_ Joystick8Button3PressedStatus : 42|2@1+ (1,0) [0|3] "" Vector__XXX
 SG_ Joystick8Button4PressedStatus : 40|2@1+ (1,0) [0|3] "" Vector__XXX
 SG_ Joystick8Button5PressedStatus : 54|2@1+ (1,0) [0|3] "" Vector__XXX
 SG_ Joystick8Button6PressedStatus : 52|2@1+ (1,0) [0|3] "" Vector__XXX
 SG_ Joystick8Button7PressedStatus : 50|2@1+ (1,0) [0|3] "" Vector__XXX
 SG_ Joystick8Button8PressedStatus : 48|2@1+ (1,0) [0|3] "" Vector__XXX
 SG_ Joystick8Button9PressedStatus : 62|2@1+ (1,0) [0|3] "" Vector__XXX
 SG_ Joystick8XAxisPosition : 6|10@1+ (0.1,0) [0|102] "%" Vector__XXX
 SG_ Joystick8YAxisPosition : 22|10@1+ (0.1,0) [0|102] "%" Vector__XXX
 SG_ Jstk8XAxsDtntPstnStts : 38|2@1+ (1,0) [0|3] "" Vector__XXX
 SG_ Jstk8XAxsLvrLftNgtvPstnStts : 2|2@1+ (1,0) [0|3] "" Vector__XXX
 SG_ Jstk8XAxsLvrRghtPstvPstnStts : 4|2@1+ (1,0) [0|3] "" Vector__XXX
 SG_ Jstk8XAxsNtrlPstnStts : 0|2@1+ (1,0) [0|3] "" Vector__XXX
 SG_ Jstk8YAxsDtntPstnStts : 36|2@1+ (1,0) [0|3] "" Vector__XXX
 SG_ Jstk8YAxsLvrBkNgtvPstnStts : 18|2@1+ (1,0) [0|3] "" Vector__XXX
 SG_ Jstk8YAxsLvrFrwrdPstvPstnStts : 20|2@1+ (1,0) [0|3] "" Vector__XXX
 SG_ Jstk8YAxsNtrlPstnStts : 16|2@1+ (1,0) [0|3] "" Vector__XXX

BO_ 2365401598 EJM7: 8 Vector__XXX
 SG_ Joystick7Button13PressedStatus : 62|2@1+ (1,0) [0|3] "" Vector__XXX
 SG_ Joystick7Button14PressedStatus : 60|2@1+ (1,0) [0|3] "" Vector__XXX
 SG_ Joystick7Button15PressedStatus : 58|2@1+ (1,0) [0|3] "" Vector__XXX
 SG_ Joystick7Button16PressedStatus : 56|2@1+ (1,0) [0|3] "" Vector__XXX
 SG_ Joystick7GripXAxisPosition : 6|10@1+ (0.1,0) [0|102] "%" Vector__XXX
 SG_ Joystick7GripYAxisPosition : 22|10@1+ (0.1,0) [0|102] "%" Vector__XXX
 SG_ Joystick7ThetaAxisPosition : 38|10@1+ (0.1,0) [0|102] "%" Vector__XXX
 SG_ Jst7GpYAxsLvFwdPstvPstStts : 20|2@1+ (1,0) [0|3] "" Vector__XXX
 SG_ Jst7TtAxsCtCwsNtvPstStts : 34|2@1+ (1,0) [0|3] "" Vector__XXX
 SG_ Jstk7GrpXAxsDtntPstnStts : 54|2@1+ (1,0) [0|3] "" Vector__XXX
 SG_ Jstk7GrpXAxsLvrLftNgtvPstnStts : 2|2@1+ (1,0) [0|3] "" Vector__XXX
 SG_ Jstk7GrpXAxsLvrRghtPstvPstnStts : 4|2@1+ (1,0) [0|3] "" Vector__XXX
 SG_ Jstk7GrpXAxsNtrlPstnStts : 0|2@1+ (1,0) [0|3] "" Vector__XXX
 SG_ Jstk7GrpYAxsDtntPstnStts : 52|2@1+ (1,0) [0|3] "" Vector__XXX
 SG_ Jstk7GrpYAxsLvrBkNgtvPstnStts : 18|2@1+ (1,0) [0|3] "" Vector__XXX
 SG_ Jstk7GrpYAxsNtrlPstnStts : 16|2@1+ (1,0) [0|3] "" Vector__XXX
 SG_ Jstk7ThtAxsClkwsPstvPstnStts : 36|2@1+ (1,0) [0|3] "" Vector__XXX
 SG_ Jstk7ThtAxsDtntPstnStts : 50|2@1+ (1,0) [0|3] "" Vector__XXX
 SG_ Jstk7ThtAxsNtrlPstnStts : 32|2@1+ (1,0) [0|3] "" Vector__XXX

BO_ 2365401854 BJM7: 8 Vector__XXX
 SG_ Joystick7Button10PressedStatus : 60|2@1+ (1,0) [0|3] "" Vector__XXX
 SG_ Joystick7Button11PressedStatus : 58|2@1+ (1,0) [0|3] "" Vector__XXX
 SG_ Joystick7Button12PressedStatus : 56|2@1+ (1,0) [0|3] "" Vector__XXX
 SG_ Joystick7Button1PressedStatus : 46|2@1+ (1,0) [0|3] "" Vector__XXX
 SG_ Joystick7Button2PressedStatus : 44|2@1+ (1,0) [0|3] "" Vector__XXX
 SG_ Joystick7Button3PressedStatus : 42|2@1+ (1,0) [0|3] "" Vector__XXX
 SG_ Joystick7Button4PressedStatus : 40|2@1+ (1,0) [0|3] "" Vector__XXX
 SG_ Joystick7Button5PressedStatus : 54|2@1+ (1,0) [0|3] "" Vector__XXX
 SG_ Joystick7Button6PressedStatus : 52|2@1+ (1,0) [0|3] "" Vector__XXX
 SG_ Joystick7Button7PressedStatus : 50|2@1+ (1,0) [0|3] "" Vector__XXX
 SG_ Joystick7Button8PressedStatus : 48|2@1+ (1,0) [0|3] "" Vector__XXX
 SG_ Joystick7Button9PressedStatus : 62|2@1+ (1,0) [0|3] "" Vector__XXX
 SG_ Joystick7XAxisPosition : 6|10@1+ (0.1,0) [0|102] "%" Vector__XXX
 SG_ Joystick7YAxisPosition : 22|10@1+ (0.1,0) [0|102] "%" Vector__XXX
 SG_ Jstk7XAxsDtntPstnStts : 38|2@1+ (1,0) [0|3] "" Vector__XXX
 SG_ Jstk7XAxsLvrLftNgtvPstnStts : 2|2@1+ (1,0) [0|3] "" Vector__XXX
 SG_ Jstk7XAxsLvrRghtPstvPstnStts : 4|2@1+ (1,0) [0|3] "" Vector__XXX
 SG_ Jstk7XAxsNtrlPstnStts : 0|2@1+ (1,0) [0|3] "" Vector__XXX
 SG_ Jstk7YAxsDtntPstnStts : 36|2@1+ (1,0) [0|3] "" Vector__XXX
 SG_ Jstk7YAxsLvrBkNgtvPstnStts : 18|2@1+ (1,0) [0|3] "" Vector__XXX
 SG_ Jstk7YAxsLvrFrwrdPstvPstnStts : 20|2@1+ (1,0) [0|3] "" Vector__XXX
 SG_ Jstk7YAxsNtrlPstnStts : 16|2@1+ (1,0) [0|3] "" Vector__XXX

BO_ 2365402110 EJM6: 8 Vector__XXX
 SG_ Joystick6Button13PressedStatus : 62|2@1+ (1,0) [0|3] "" Vector__XXX
 SG_ Joystick6Button14PressedStatus : 60|2@1+ (1,0) [0|3] "" Vector__XXX
 SG_ Joystick6Button15PressedStatus : 58|2@1+ (1,0) [0|3] "" Vector__XXX
 SG_ Joystick6Button16PressedStatus : 56|2@1+ (1,0) [0|3] "" Vector__XXX
 SG_ Joystick6GripXAxisPosition : 6|10@1+ (0.1,0) [0|102] "%" Vector__XXX
 SG_ Joystick6GripYAxisPosition : 22|10@1+ (0.1,0) [0|102] "%" Vector__XXX
 SG_ Joystick6ThetaAxisPosition : 38|10@1+ (0.1,0) [0|102] "%" Vector__XXX
 SG_ Jst6GpYAxsLvFwdPstvPstStts : 20|2@1+ (1,0) [0|3] "" Vector__XXX
 SG_ Jst6TtAxsCtCwsNtvPstStts : 34|2@1+ (1,0) [0|3] "" Vector__XXX
 SG_ Jstk6GrpXAxsDtntPstnStts : 54|2@1+ (1,0) [0|3] "" Vector__XXX
 SG_ Jstk6GrpXAxsLvrLftNgtvPstnStts : 2|2@1+ (1,0) [0|3] "" Vector__XXX
 SG_ Jstk6GrpXAxsLvrRghtPstvPstnStts : 4|2@1+ (1,0) [0|3] "" Vector__XXX
 SG_ Jstk6GrpXAxsNtrlPstnStts : 0|2@1+ (1,0) [0|3] "" Vector__XXX
 SG_ Jstk6GrpYAxsDtntPstnStts : 52|2@1+ (1,0) [0|3] "" Vector__XXX
 SG_ Jstk6GrpYAxsLvrBkNgtvPstnStts : 18|2@1+ (1,0) [0|3] "" Vector__XXX
 SG_ Jstk6GrpYAxsNtrlPstnStts : 16|2@1+ (1,0) [0|3] "" Vector__XXX
 SG_ Jstk6ThtAxsClkwsPstvPstnStts : 36|2@1+ (1,0) [0|3] "" Vector__XXX
 SG_ Jstk6ThtAxsDtntPstnStts : 50|2@1+ (1,0) [0|3] "" Vector__XXX
 SG_ Jstk6ThtAxsNtrlPstnStts : 32|2@1+ (1,0) [0|3] "" Vector__XXX

BO_ 2365402366 BJM6: 8 Vector__XXX
 SG_ Joystick6Button10PressedStatus : 60|2@1+ (1,0) [0|3] "" Vector__XXX
 SG_ Joystick6Button11PressedStatus : 58|2@1+ (1,0) [0|3] "" Vector__XXX
 SG_ Joystick6Button12PressedStatus : 56|2@1+ (1,0) [0|3] "" Vector__XXX
 SG_ Joystick6Button1PressedStatus : 46|2@1+ (1,0) [0|3] "" Vector__XXX
 SG_ Joystick6Button2PressedStatus : 44|2@1+ (1,0) [0|3] "" Vector__XXX
 SG_ Joystick6Button3PressedStatus : 42|2@1+ (1,0) [0|3] "" Vector__XXX
 SG_ Joystick6Button4PressedStatus : 40|2@1+ (1,0) [0|3] "" Vector__XXX
 SG_ Joystick6Button5PressedStatus : 54|2@1+ (1,0) [0|3] "" Vector__XXX
 SG_ Joystick6Button6PressedStatus : 52|2@1+ (1,0) [0|3] "" Vector__XXX
 SG_ Joystick6Button7PressedStatus : 50|2@1+ (1,0) [0|3] "" Vector__XXX
 SG_ Joystick6Button8PressedStatus : 48|2@1+ (1,0) [0|3] "" Vector__XXX
 SG_ Joystick6Button9PressedStatus : 62|2@1+ (1,0) [0|3] "" Vector__XXX
 SG_ Joystick6XAxisPosition : 6|10@1+ (0.1,0) [0|102] "%" Vector__XXX
 SG_ Joystick6YAxisPosition : 22|10@1+ (0.1,0) [0|102] "%" Vector__XXX
 SG_ Jstk6XAxsDtntPstnStts : 38|2@1+ (1,0) [0|3] "" Vector__XXX
 SG_ Jstk6XAxsLvrLftNgtvPstnStts : 2|2@1+ (1,0) [0|3] "" Vector__XXX
 SG_ Jstk6XAxsLvrRghtPstvPstnStts : 4|2@1+ (1,0) [0|3] "" Vector__XXX
 SG_ Jstk6XAxsNtrlPstnStts : 0|2@1+ (1,0) [0|3] "" Vector__XXX
 SG_ Jstk6YAxsDtntPstnStts : 36|2@1+ (1,0) [0|3] "" Vector__XXX
 SG_ Jstk6YAxsLvrBkNgtvPstnStts : 18|2@1+ (1,0) [0|3] "" Vector__XXX
 SG_ Jstk6YAxsLvrFrwrdPstvPstnStts : 20|2@1+ (1,0) [0|3] "" Vector__XXX
 SG_ Jstk6YAxsNtrlPstnStts : 16|2@1+ (1,0) [0|3] "" Vector__XXX

BO_ 2365402622 EJM5: 8 Vector__XXX
 SG_ Joystick5Button13PressedStatus : 62|2@1+ (1,0) [0|3] "" Vector__XXX
 SG_ Joystick5Button14PressedStatus : 60|2@1+ (1,0) [0|3] "" Vector__XXX
 SG_ Joystick5Button15PressedStatus : 58|2@1+ (1,0) [0|3] "" Vector__XXX
 SG_ Joystick5Button16PressedStatus : 56|2@1+ (1,0) [0|3] "" Vector__XXX
 SG_ Joystick5GripXAxisPosition : 6|10@1+ (0.1,0) [0|102] "%" Vector__XXX
 SG_ Joystick5GripYAxisPosition : 22|10@1+ (0.1,0) [0|102] "%" Vector__XXX
 SG_ Joystick5ThetaAxisPosition : 38|10@1+ (0.1,0) [0|102] "%" Vector__XXX
 SG_ Jst5GpYAxsLvFwdPstvPstStts : 20|2@1+ (1,0) [0|3] "" Vector__XXX
 SG_ Jst5TtAxsCtCwsNtvPstStts : 34|2@1+ (1,0) [0|3] "" Vector__XXX
 SG_ Jstk5GrpXAxsDtntPstnStts : 54|2@1+ (1,0) [0|3] "" Vector__XXX
 SG_ Jstk5GrpXAxsLvrLftNgtvPstnStts : 2|2@1+ (1,0) [0|3] "" Vector__XXX
 SG_ Jstk5GrpXAxsLvrRghtPstvPstnStts : 4|2@1+ (1,0) [0|3] "" Vector__XXX
 SG_ Jstk5GrpXAxsNtrlPstnStts : 0|2@1+ (1,0) [0|3] "" Vector__XXX
 SG_ Jstk5GrpYAxsDtntPstnStts : 52|2@1+ (1,0) [0|3] "" Vector__XXX
 SG_ Jstk5GrpYAxsLvrBkNgtvPstnStts : 18|2@1+ (1,0) [0|3] "" Vector__XXX
 SG_ Jstk5GrpYAxsNtrlPstnStts : 16|2@1+ (1,0) [0|3] "" Vector__XXX
 SG_ Jstk5ThtAxsClkwsPstvPstnStts : 36|2@1+ (1,0) [0|3] "" Vector__XXX
 SG_ Jstk5ThtAxsDtntPstnStts : 50|2@1+ (1,0) [0|3] "" Vector__XXX
 SG_ Jstk5ThtAxsNtrlPstnStts : 32|2@1+ (1,0) [0|3] "" Vector__XXX

BO_ 2365402878 BJM5: 8 Vector__XXX
 SG_ Joystick5Button10PressedStatus : 60|2@1+ (1,0) [0|3] "" Vector__XXX
 SG_ Joystick5Button11PressedStatus : 58|2@1+ (1,0) [0|3] "" Vector__XXX
 SG_ Joystick5Button12PressedStatus : 56|2@1+ (1,0) [0|3] "" Vector__XXX
 SG_ Joystick5Button1PressedStatus : 46|2@1+ (1,0) [0|3] "" Vector__XXX
 SG_ Joystick5Button2PressedStatus : 44|2@1+ (1,0) [0|3] "" Vector__XXX
 SG_ Joystick5Button3PressedStatus : 42|2@1+ (1,0) [0|3] "" Vector__XXX
 SG_ Joystick5Button4PressedStatus : 40|2@1+ (1,0) [0|3] "" Vector__XXX
 SG_ Joystick5Button5PressedStatus : 54|2@1+ (1,0) [0|3] "" Vector__XXX
 SG_ Joystick5Button6PressedStatus : 52|2@1+ (1,0) [0|3] "" Vector__XXX
 SG_ Joystick5Button7PressedStatus : 50|2@1+ (1,0) [0|3] "" Vector__XXX
 SG_ Joystick5Button8PressedStatus : 48|2@1+ (1,0) [0|3] "" Vector__XXX
 SG_ Joystick5Button9PressedStatus : 62|2@1+ (1,0) [0|3] "" Vector__XXX
 SG_ Joystick5XAxisPosition : 6|10@1+ (0.1,0) [0|102] "%" Vector__XXX
 SG_ Joystick5YAxisPosition : 22|10@1+ (0.1,0) [0|102] "%" Vector__XXX
 SG_ Jstk5XAxsDtntPstnStts : 38|2@1+ (1,0) [0|3] "" Vector__XXX
 SG_ Jstk5XAxsLvrLftNgtvPstnStts : 2|2@1+ (1,0) [0|3] "" Vector__XXX
 SG_ Jstk5XAxsLvrRghtPstvPstnStts : 4|2@1+ (1,0) [0|3] "" Vector__XXX
 SG_ Jstk5XAxsNtrlPstnStts : 0|2@1+ (1,0) [0|3] "" Vector__XXX
 SG_ Jstk5YAxsDtntPstnStts : 36|2@1+ (1,0) [0|3] "" Vector__XXX
 SG_ Jstk5YAxsLvrBkNgtvPstnStts : 18|2@1+ (1,0) [0|3] "" Vector__XXX
 SG_ Jstk5YAxsLvrFrwrdPstvPstnStts : 20|2@1+ (1,0) [0|3] "" Vector__XXX
 SG_ Jstk5YAxsNtrlPstnStts : 16|2@1+ (1,0) [0|3] "" Vector__XXX

BO_ 2365403134 EJM4: 8 Vector__XXX
 SG_ Joystick4Button13PressedStatus : 62|2@1+ (1,0) [0|3] "" Vector__XXX
 SG_ Joystick4Button14PressedStatus : 60|2@1+ (1,0) [0|3] "" Vector__XXX
 SG_ Joystick4Button15PressedStatus : 58|2@1+ (1,0) [0|3] "" Vector__XXX
 SG_ Joystick4Button16PressedStatus : 56|2@1+ (1,0) [0|3] "" Vector__XXX
 SG_ Joystick4GripXAxisPosition : 6|10@1+ (0.1,0) [0|102] "%" Vector__XXX
 SG_ Joystick4GripYAxisPosition : 22|10@1+ (0.1,0) [0|102] "%" Vector__XXX
 SG_ Joystick4ThetaAxisPosition : 38|10@1+ (0.1,0) [0|102] "%" Vector__XXX
 SG_ Jst4GpYAxsLvFwdPstvPstStts : 20|2@1+ (1,0) [0|3] "" Vector__XXX
 SG_ Jst4TtAxsCtCwsNtvPstStts : 34|2@1+ (1,0) [0|3] "" Vector__XXX
 SG_ Jstk4GrpXAxsDtntPstnStts : 54|2@1+ (1,0) [0|3] "" Vector__XXX
 SG_ Jstk4GrpXAxsLvrLftNgtvPstnStts : 2|2@1+ (1,0) [0|3] "" Vector__XXX
 SG_ Jstk4GrpXAxsLvrRghtPstvPstnStts : 4|2@1+ (1,0) [0|3] "" Vector__XXX
 SG_ Jstk4GrpXAxsNtrlPstnStts : 0|2@1+ (1,0) [0|3] "" Vector__XXX
 SG_ Jstk4GrpYAxsDtntPstnStts : 52|2@1+ (1,0) [0|3] "" Vector__XXX
 SG_ Jstk4GrpYAxsLvrBkNgtvPstnStts : 18|2@1+ (1,0) [0|3] "" Vector__XXX
 SG_ Jstk4GrpYAxsNtrlPstnStts : 16|2@1+ (1,0) [0|3] "" Vector__XXX
 SG_ Jstk4ThtAxsClkwsPstvPstnStts : 36|2@1+ (1,0) [0|3] "" Vector__XXX
 SG_ Jstk4ThtAxsDtntPstnStts : 50|2@1+ (1,0) [0|3] "" Vector__XXX
 SG_ Jstk4ThtAxsNtrlPstnStts : 32|2@1+ (1,0) [0|3] "" Vector__XXX

BO_ 2365403390 BJM4: 8 Vector__XXX
 SG_ Joystick4Button10PressedStatus : 60|2@1+ (1,0) [0|3] "" Vector__XXX
 SG_ Joystick4Button11PressedStatus : 58|2@1+ (1,0) [0|3] "" Vector__XXX
 SG_ Joystick4Button12PressedStatus : 56|2@1+ (1,0) [0|3] "" Vector__XXX
 SG_ Joystick4Button1PressedStatus : 46|2@1+ (1,0) [0|3] "" Vector__XXX
 SG_ Joystick4Button2PressedStatus : 44|2@1+ (1,0) [0|3] "" Vector__XXX
 SG_ Joystick4Button3PressedStatus : 42|2@1+ (1,0) [0|3] "" Vector__XXX
 SG_ Joystick4Button4PressedStatus : 40|2@1+ (1,0) [0|3] "" Vector__XXX
 SG_ Joystick4Button5PressedStatus : 54|2@1+ (1,0) [0|3] "" Vector__XXX
 SG_ Joystick4Button6PressedStatus : 52|2@1+ (1,0) [0|3] "" Vector__XXX
 SG_ Joystick4Button7PressedStatus : 50|2@1+ (1,0) [0|3] "" Vector__XXX
 SG_ Joystick4Button8PressedStatus : 48|2@1+ (1,0) [0|3] "" Vector__XXX
 SG_ Joystick4Button9PressedStatus : 62|2@1+ (1,0) [0|3] "" Vector__XXX
 SG_ Joystick4XAxisPosition : 6|10@1+ (0.1,0) [0|102] "%" Vector__XXX
 SG_ Joystick4YAxisPosition : 22|10@1+ (0.1,0) [0|102] "%" Vector__XXX
 SG_ Jstk4XAxsDtntPstnStts : 38|2@1+ (1,0) [0|3] "" Vector__XXX
 SG_ Jstk4XAxsLvrLftNgtvPstnStts : 2|2@1+ (1,0) [0|3] "" Vector__XXX
 SG_ Jstk4XAxsLvrRghtPstvPstnStts : 4|2@1+ (1,0) [0|3] "" Vector__XXX
 SG_ Jstk4XAxsNtrlPstnStts : 0|2@1+ (1,0) [0|3] "" Vector__XXX
 SG_ Jstk4YAxsDtntPstnStts : 36|2@1+ (1,0) [0|3] "" Vector__XXX
 SG_ Jstk4YAxsLvrBkNgtvPstnStts : 18|2@1+ (1,0) [0|3] "" Vector__XXX
 SG_ Jstk4YAxsLvrFrwrdPstvPstnStts : 20|2@1+ (1,0) [0|3] "" Vector__XXX
 SG_ Jstk4YAxsNtrlPstnStts : 16|2@1+ (1,0) [0|3] "" Vector__XXX

BO_ 2365428478 EOI: 8 Vector__XXX
 SG_ EngineControlledShutdownRequest : 42|2@1+ (1,0) [0|3] "" Vector__XXX
 SG_ EngineCoolantPumpControl : 40|2@1+ (1,0) [0|3] "" Vector__XXX
 SG_ EngineDerateRequest : 56|8@1+ (0.4,0) [0|100] "%" Vector__XXX
 SG_ EngineDesiredTorqueRequest : 48|8@1+ (1,-125) [0|125] "%" Vector__XXX
 SG_ EngineFuelShutoff1Control : 26|2@1+ (1,0) [0|3] "" Vector__XXX
 SG_ EngineFuelShutoff2Control : 28|2@1+ (1,0) [0|3] "" Vector__XXX
 SG_ EngineFuelShutoffVentControl : 24|2@1+ (1,0) [0|3] "" Vector__XXX
 SG_ EngineOilPreHeaterControl : 34|2@1+ (1,0) [0|3] "" Vector__XXX
 SG_ EngineOilPrimingPumpControl : 32|2@1+ (1,0) [0|3] "" Vector__XXX
 SG_ EngineOperatingState : 0|4@1+ (1,0) [0|15] "" Vector__XXX
 SG_ EnginePreHeaterControl : 38|2@1+ (1,0) [0|3] "" Vector__XXX
 SG_ EngineStarterMotorRelayControl : 6|2@1+ (1,0) [0|3] "" Vector__XXX
 SG_ EngnCldAmntElvtdIdlStts : 46|2@1+ (1,0) [0|3] "" Vector__XXX
 SG_ EngnEltrlSstmPwrCnsrvtnCntrl : 36|2@1+ (1,0) [0|3] "" Vector__XXX
 SG_ EngnEmrgnImmdtShtdwnIndtn : 44|2@1+ (1,0) [0|3] "" Vector__XXX
 SG_ EngnFlShtffVlvLkTstCntrl : 30|2@1+ (1,0) [0|3] "" Vector__XXX
 SG_ FuelPumpPrimerControl : 4|2@1+ (1,0) [0|3] "" Vector__XXX
 SG_ TmRmnngInEngnOprtngStt : 8|16@1+ (1,0) [0|64255] "s" Vector__XXX

BO_ 2365428734 GC1: 8 Vector__XXX
 SG_ EngineSpeedGovernorDroop : 48|8@1+ (0.04,0) [0|10] "%" Vector__XXX
 SG_ EngineSpeedGovernorGainAdjust : 32|16@1+ (1,-32128) [-32128|32127] "count" Vector__XXX
 SG_ GeneratorAlternatorEfficiency : 8|16@1+ (0.0025,0) [0|100] "%" Vector__XXX
 SG_ GeneratorFrequencySelection : 26|4@1+ (1,0) [0|15] "" Vector__XXX
 SG_ GeneratorGoverningSpeedCommand : 24|2@1+ (1,0) [0|3] "" Vector__XXX
 SG_ GnrtrCntrlNtInAtmtStrtStt : 4|2@1+ (1,0) [0|3] "" Vector__XXX
 SG_ GnrtrNtRdTAtmtllPrlllStt : 6|2@1+ (1,0) [0|3] "" Vector__XXX
 SG_ RequestedEngineControlMode : 0|4@1+ (1,0) [0|15] "" Vector__XXX

BO_ 2365433598 VREP: 8 Vector__XXX
 SG_ GeneratorExcitationFieldCurrent : 16|16@1+ (0.05,0) [0|3212.75] "A" Vector__XXX
 SG_ GeneratorExcitationFieldVoltage : 0|16@1+ (0.05,-1606) [-1606|1606.75] "V" Vector__XXX
 SG_ GnrtrOtptVltgBsPrntg : 32|16@1+ (0.1,-100) [-100|100] "%" Vector__XXX

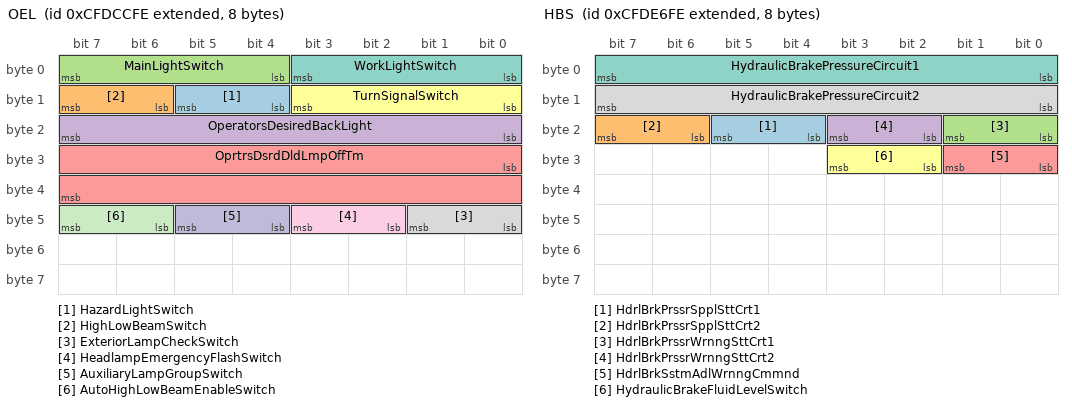
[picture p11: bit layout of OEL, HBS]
BO_ 2365443326 OEL: 8 Vector__XXX
 SG_ HazardLightSwitch : 12|2@1+ (1,0) [0|3] "" Vector__XXX
 SG_ HighLowBeamSwitch : 14|2@1+ (1,0) [0|3] "" Vector__XXX
 SG_ MainLightSwitch : 4|4@1+ (1,0) [0|15] "" Vector__XXX
 SG_ OperatorsDesiredBackLight : 16|8@1+ (0.4,0) [0|100] "%" Vector__XXX
 SG_ OprtrsDsrdDldLmpOffTm : 24|16@1+ (1,0) [0|64255] "s" Vector__XXX
 SG_ TurnSignalSwitch : 8|4@1+ (1,0) [0|15] "" Vector__XXX
 SG_ WorkLightSwitch : 0|4@1+ (1,0) [0|15] "" Vector__XXX
 SG_ ExteriorLampCheckSwitch : 40|2@1+ (1,0) [0|3] "" Vector__XXX
 SG_ HeadlampEmergencyFlashSwitch : 42|2@1+ (1,0) [0|3] "" Vector__XXX
 SG_ AuxiliaryLampGroupSwitch : 44|2@1+ (1,0) [0|3] "" Vector__XXX
 SG_ AutoHighLowBeamEnableSwitch : 46|2@1+ (1,0) [0|3] "" Vector__XXX

BO_ 2365445886 BJM1: 8 Vector__XXX
 SG_ Joystick1Button10PressedStatus : 60|2@1+ (1,0) [0|3] "" Vector__XXX
 SG_ Joystick1Button11PressedStatus : 58|2@1+ (1,0) [0|3] "" Vector__XXX
 SG_ Joystick1Button12PressedStatus : 56|2@1+ (1,0) [0|3] "" Vector__XXX
 SG_ Joystick1Button1PressedStatus : 46|2@1+ (1,0) [0|3] "" Vector__XXX
 SG_ Joystick1Button2PressedStatus : 44|2@1+ (1,0) [0|3] "" Vector__XXX
 SG_ Joystick1Button3PressedStatus : 42|2@1+ (1,0) [0|3] "" Vector__XXX
 SG_ Joystick1Button4PressedStatus : 40|2@1+ (1,0) [0|3] "" Vector__XXX
 SG_ Joystick1Button5PressedStatus : 54|2@1+ (1,0) [0|3] "" Vector__XXX
 SG_ Joystick1Button6PressedStatus : 52|2@1+ (1,0) [0|3] "" Vector__XXX
 SG_ Joystick1Button7PressedStatus : 50|2@1+ (1,0) [0|3] "" Vector__XXX
 SG_ Joystick1Button8PressedStatus : 48|2@1+ (1,0) [0|3] "" Vector__XXX
 SG_ Joystick1Button9PressedStatus : 62|2@1+ (1,0) [0|3] "" Vector__XXX
 SG_ Joystick1XAxisPosition : 6|10@1+ (0.1,0) [0|100] "%" Vector__XXX
 SG_ Joystick1YAxisPosition : 22|10@1+ (0.1,0) [0|100] "%" Vector__XXX
 SG_ Jstk1XAxsDtntPstnStts : 38|2@1+ (1,0) [0|3] "" Vector__XXX
 SG_ Jstk1XAxsLvrLftNgtvPstnStts : 2|2@1+ (1,0) [0|3] "" Vector__XXX
 SG_ Jstk1XAxsLvrRghtPstvPstnStts : 4|2@1+ (1,0) [0|3] "" Vector__XXX
 SG_ Jstk1XAxsNtrlPstnStts : 0|2@1+ (1,0) [0|3] "" Vector__XXX
 SG_ Jstk1YAxsDtntPstnStts : 36|2@1+ (1,0) [0|3] "" Vector__XXX
 SG_ Jstk1YAxsLvrBkNgtvPstnStts : 18|2@1+ (1,0) [0|3] "" Vector__XXX
 SG_ Jstk1YAxsLvrFrwrdPstvPstnStts : 20|2@1+ (1,0) [0|3] "" Vector__XXX
 SG_ Jstk1YAxsNtrlPstnStts : 16|2@1+ (1,0) [0|3] "" Vector__XXX

BO_ 2365446142 EJM1: 8 Vector__XXX
 SG_ Joystick1Button13PressedStatus : 62|2@1+ (1,0) [0|3] "" Vector__XXX
 SG_ Joystick1Button14PressedStatus : 60|2@1+ (1,0) [0|3] "" Vector__XXX
 SG_ Joystick1Button15PressedStatus : 58|2@1+ (1,0) [0|3] "" Vector__XXX
 SG_ Joystick1Button16PressedStatus : 56|2@1+ (1,0) [0|3] "" Vector__XXX
 SG_ Joystick1GripXAxisPosition : 6|10@1+ (0.1,0) [0|100] "%" Vector__XXX
 SG_ Joystick1GripYAxisPosition : 22|10@1+ (0.1,0) [0|100] "%" Vector__XXX
 SG_ Joystick1ThetaAxisPosition : 38|10@1+ (0.1,0) [0|100] "%" Vector__XXX
 SG_ Jst1GpYAxsLvFwdPstvPstStts : 20|2@1+ (1,0) [0|3] "" Vector__XXX
 SG_ Jst1TtAxsCtCwsNtvPstStts : 34|2@1+ (1,0) [0|3] "" Vector__XXX
 SG_ Jstk1GrpXAxsDtntPstnStts : 54|2@1+ (1,0) [0|3] "" Vector__XXX
 SG_ Jstk1GrpXAxsLvrLftNgtvPstnStts : 2|2@1+ (1,0) [0|3] "" Vector__XXX
 SG_ Jstk1GrpXAxsLvrRghtPstvPstnStts : 4|2@1+ (1,0) [0|3] "" Vector__XXX
 SG_ Jstk1GrpXAxsNtrlPstnStts : 0|2@1+ (1,0) [0|3] "" Vector__XXX
 SG_ Jstk1GrpYAxsDtntPstnStts : 52|2@1+ (1,0) [0|3] "" Vector__XXX
 SG_ Jstk1GrpYAxsLvrBkNgtvPstnStts : 18|2@1+ (1,0) [0|3] "" Vector__XXX
 SG_ Jstk1GrpYAxsNtrlPstnStts : 16|2@1+ (1,0) [0|3] "" Vector__XXX
 SG_ Jstk1ThtAxsClkwsPstvPstnStts : 36|2@1+ (1,0) [0|3] "" Vector__XXX
 SG_ Jstk1ThtAxsDtntPstnStts : 50|2@1+ (1,0) [0|3] "" Vector__XXX
 SG_ Jstk1ThtAxsNtrlPstnStts : 32|2@1+ (1,0) [0|3] "" Vector__XXX

BO_ 2365446398 BJM2: 8 Vector__XXX
 SG_ Joystick2Button10PressedStatus : 60|2@1+ (1,0) [0|3] "" Vector__XXX
 SG_ Joystick2Button11PressedStatus : 58|2@1+ (1,0) [0|3] "" Vector__XXX
 SG_ Joystick2Button12PressedStatus : 56|2@1+ (1,0) [0|3] "" Vector__XXX
 SG_ Joystick2Button1PressedStatus : 46|2@1+ (1,0) [0|3] "" Vector__XXX
 SG_ Joystick2Button2PressedStatus : 44|2@1+ (1,0) [0|3] "" Vector__XXX
 SG_ Joystick2Button3PressedStatus : 42|2@1+ (1,0) [0|3] "" Vector__XXX
 SG_ Joystick2Button4PressedStatus : 40|2@1+ (1,0) [0|3] "" Vector__XXX
 SG_ Joystick2Button5PressedStatus : 54|2@1+ (1,0) [0|3] "" Vector__XXX
 SG_ Joystick2Button6PressedStatus : 52|2@1+ (1,0) [0|3] "" Vector__XXX
 SG_ Joystick2Button7PressedStatus : 50|2@1+ (1,0) [0|3] "" Vector__XXX
 SG_ Joystick2Button8PressedStatus : 48|2@1+ (1,0) [0|3] "" Vector__XXX
 SG_ Joystick2Button9PressedStatus : 62|2@1+ (1,0) [0|3] "" Vector__XXX
 SG_ Joystick2XAxisPosition : 6|10@1+ (0.1,0) [0|100] "%" Vector__XXX
 SG_ Joystick2YAxisPosition : 22|10@1+ (0.1,0) [0|100] "%" Vector__XXX
 SG_ Jstk2XAxsDtntPstnStts : 38|2@1+ (1,0) [0|3] "" Vector__XXX
 SG_ Jstk2XAxsLvrLftNgtvPstnStts : 2|2@1+ (1,0) [0|3] "" Vector__XXX
 SG_ Jstk2XAxsLvrRghtPstvPstnStts : 4|2@1+ (1,0) [0|3] "" Vector__XXX
 SG_ Jstk2XAxsNtrlPstnStts : 0|2@1+ (1,0) [0|3] "" Vector__XXX
 SG_ Jstk2YAxsDtntPstnStts : 36|2@1+ (1,0) [0|3] "" Vector__XXX
 SG_ Jstk2YAxsLvrBkNgtvPstnStts : 18|2@1+ (1,0) [0|3] "" Vector__XXX
 SG_ Jstk2YAxsLvrFrwrdPstvPstnStts : 20|2@1+ (1,0) [0|3] "" Vector__XXX
 SG_ Jstk2YAxsNtrlPstnStts : 16|2@1+ (1,0) [0|3] "" Vector__XXX

BO_ 2365446654 EJM2: 8 Vector__XXX
 SG_ Joystick2Button13PressedStatus : 62|2@1+ (1,0) [0|3] "" Vector__XXX
 SG_ Joystick2Button14PressedStatus : 60|2@1+ (1,0) [0|3] "" Vector__XXX
 SG_ Joystick2Button15PressedStatus : 58|2@1+ (1,0) [0|3] "" Vector__XXX
 SG_ Joystick2Button16PressedStatus : 56|2@1+ (1,0) [0|3] "" Vector__XXX
 SG_ Joystick2GripXAxisPosition : 6|10@1+ (0.1,0) [0|100] "%" Vector__XXX
 SG_ Joystick2GripYAxisPosition : 22|10@1+ (0.1,0) [0|100] "%" Vector__XXX
 SG_ Joystick2ThetaAxisPosition : 38|10@1+ (0.1,0) [0|100] "%" Vector__XXX
 SG_ Jst2GpYAxsLvFwdPstvPstStts : 20|2@1+ (1,0) [0|3] "" Vector__XXX
 SG_ Jst2TtAxsCtCwsNtvPstStts : 34|2@1+ (1,0) [0|3] "" Vector__XXX
 SG_ Jstk2GrpXAxsDtntPstnStts : 54|2@1+ (1,0) [0|3] "" Vector__XXX
 SG_ Jstk2GrpXAxsLvrLftNgtvPstnStts : 2|2@1+ (1,0) [0|3] "" Vector__XXX
 SG_ Jstk2GrpXAxsLvrRghtPstvPstnStts : 4|2@1+ (1,0) [0|3] "" Vector__XXX
 SG_ Jstk2GrpXAxsNtrlPstnStts : 0|2@1+ (1,0) [0|3] "" Vector__XXX
 SG_ Jstk2GrpYAxsDtntPstnStts : 52|2@1+ (1,0) [0|3] "" Vector__XXX
 SG_ Jstk2GrpYAxsLvrBkNgtvPstnStts : 18|2@1+ (1,0) [0|3] "" Vector__XXX
 SG_ Jstk2GrpYAxsNtrlPstnStts : 16|2@1+ (1,0) [0|3] "" Vector__XXX
 SG_ Jstk2ThtAxsClkwsPstvPstnStts : 36|2@1+ (1,0) [0|3] "" Vector__XXX
 SG_ Jstk2ThtAxsDtntPstnStts : 50|2@1+ (1,0) [0|3] "" Vector__XXX
 SG_ Jstk2ThtAxsNtrlPstnStts : 32|2@1+ (1,0) [0|3] "" Vector__XXX

BO_ 2365446910 BJM3: 8 Vector__XXX
 SG_ Joystick3Button10PressedStatus : 60|2@1+ (1,0) [0|3] "" Vector__XXX
 SG_ Joystick3Button11PressedStatus : 58|2@1+ (1,0) [0|3] "" Vector__XXX
 SG_ Joystick3Button12PressedStatus : 56|2@1+ (1,0) [0|3] "" Vector__XXX
 SG_ Joystick3Button1PressedStatus : 46|2@1+ (1,0) [0|3] "" Vector__XXX
 SG_ Joystick3Button2PressedStatus : 44|2@1+ (1,0) [0|3] "" Vector__XXX
 SG_ Joystick3Button3PressedStatus : 42|2@1+ (1,0) [0|3] "" Vector__XXX
 SG_ Joystick3Button4PressedStatus : 40|2@1+ (1,0) [0|3] "" Vector__XXX
 SG_ Joystick3Button5PressedStatus : 54|2@1+ (1,0) [0|3] "" Vector__XXX
 SG_ Joystick3Button6PressedStatus : 52|2@1+ (1,0) [0|3] "" Vector__XXX
 SG_ Joystick3Button7PressedStatus : 50|2@1+ (1,0) [0|3] "" Vector__XXX
 SG_ Joystick3Button8PressedStatus : 48|2@1+ (1,0) [0|3] "" Vector__XXX
 SG_ Joystick3Button9PressedStatus : 62|2@1+ (1,0) [0|3] "" Vector__XXX
 SG_ Joystick3XAxisPosition : 6|10@1+ (0.1,0) [0|100] "%" Vector__XXX
 SG_ Joystick3YAxisPosition : 22|10@1+ (0.1,0) [0|100] "%" Vector__XXX
 SG_ Jstk3XAxsDtntPstnStts : 38|2@1+ (1,0) [0|3] "" Vector__XXX
 SG_ Jstk3XAxsLvrLftNgtvPstnStts : 2|2@1+ (1,0) [0|3] "" Vector__XXX
 SG_ Jstk3XAxsLvrRghtPstvPstnStts : 4|2@1+ (1,0) [0|3] "" Vector__XXX
 SG_ Jstk3XAxsNtrlPstnStts : 0|2@1+ (1,0) [0|3] "" Vector__XXX
 SG_ Jstk3YAxsDtntPstnStts : 36|2@1+ (1,0) [0|3] "" Vector__XXX
 SG_ Jstk3YAxsLvrBkNgtvPstnStts : 18|2@1+ (1,0) [0|3] "" Vector__XXX
 SG_ Jstk3YAxsLvrFrwrdPstvPstnStts : 20|2@1+ (1,0) [0|3] "" Vector__XXX
 SG_ Jstk3YAxsNtrlPstnStts : 16|2@1+ (1,0) [0|3] "" Vector__XXX

BO_ 2365447166 EJM3: 8 Vector__XXX
 SG_ Joystick3Button13PressedStatus : 62|2@1+ (1,0) [0|3] "" Vector__XXX
 SG_ Joystick3Button14PressedStatus : 60|2@1+ (1,0) [0|3] "" Vector__XXX
 SG_ Joystick3Button15PressedStatus : 58|2@1+ (1,0) [0|3] "" Vector__XXX
 SG_ Joystick3Button16PressedStatus : 56|2@1+ (1,0) [0|3] "" Vector__XXX
 SG_ Joystick3GripXAxisPosition : 6|10@1+ (0.1,0) [0|100] "%" Vector__XXX
 SG_ Joystick3GripYAxisPosition : 22|10@1+ (0.1,0) [0|100] "%" Vector__XXX
 SG_ Joystick3ThetaAxisPosition : 38|10@1+ (0.1,0) [0|100] "%" Vector__XXX
 SG_ Jst3GpYAxsLvFwdPstvPstStts : 20|2@1+ (1,0) [0|3] "" Vector__XXX
 SG_ Jst3TtAxsCtCwsNtvPstStts : 34|2@1+ (1,0) [0|3] "" Vector__XXX
 SG_ Jstk3GrpXAxsDtntPstnStts : 54|2@1+ (1,0) [0|3] "" Vector__XXX
 SG_ Jstk3GrpXAxsLvrLftNgtvPstnStts : 2|2@1+ (1,0) [0|3] "" Vector__XXX
 SG_ Jstk3GrpXAxsLvrRghtPstvPstnStts : 4|2@1+ (1,0) [0|3] "" Vector__XXX
 SG_ Jstk3GrpXAxsNtrlPstnStts : 0|2@1+ (1,0) [0|3] "" Vector__XXX
 SG_ Jstk3GrpYAxsDtntPstnStts : 52|2@1+ (1,0) [0|3] "" Vector__XXX
 SG_ Jstk3GrpYAxsLvrBkNgtvPstnStts : 18|2@1+ (1,0) [0|3] "" Vector__XXX
 SG_ Jstk3GrpYAxsNtrlPstnStts : 16|2@1+ (1,0) [0|3] "" Vector__XXX
 SG_ Jstk3ThtAxsClkwsPstvPstnStts : 36|2@1+ (1,0) [0|3] "" Vector__XXX
 SG_ Jstk3ThtAxsDtntPstnStts : 50|2@1+ (1,0) [0|3] "" Vector__XXX
 SG_ Jstk3ThtAxsNtrlPstnStts : 32|2@1+ (1,0) [0|3] "" Vector__XXX

BO_ 2365449982 HBS: 8 Vector__XXX
 SG_ HdrlBrkPrssrSpplSttCrt1 : 20|2@1+ (1,0) [0|3] "" Vector__XXX
 SG_ HdrlBrkPrssrSpplSttCrt2 : 22|2@1+ (1,0) [0|3] "" Vector__XXX
 SG_ HdrlBrkPrssrWrnngSttCrt1 : 16|2@1+ (1,0) [0|3] "" Vector__XXX
 SG_ HdrlBrkPrssrWrnngSttCrt2 : 18|2@1+ (1,0) [0|3] "" Vector__XXX
 SG_ HdrlBrkSstmAdlWrnngCmmnd : 24|2@1+ (1,0) [0|3] "" Vector__XXX
 SG_ HydraulicBrakeFluidLevelSwitch : 26|2@1+ (1,0) [0|3] "" Vector__XXX
 SG_ HydraulicBrakePressureCircuit1 : 0|8@1+ (100,0) [0|25000] "kPa" Vector__XXX
 SG_ HydraulicBrakePressureCircuit2 : 8|8@1+ (100,0) [0|25000] "kPa" Vector__XXX

BO_ 2365450238 BUSC: 8 Vector__XXX
 SG_ Bus1UtilityAcPhaseDifference : 16|16@1+ (0.0078125,-200) [-200|301.9921875] "deg" Vector__XXX
 SG_ Bus1UtilityDeadBus : 0|2@1+ (1,0) [0|3] "" Vector__XXX
 SG_ Bus1UtilityFrequencyMatch : 4|2@1+ (1,0) [0|3] "" Vector__XXX
 SG_ Bus1UtilityInSync : 8|2@1+ (1,0) [0|3] "" Vector__XXX
 SG_ Bus1UtilityPhaseMatch : 2|2@1+ (1,0) [0|3] "" Vector__XXX
 SG_ Bus1UtilityVoltageMatch : 6|2@1+ (1,0) [0|3] "" Vector__XXX

BO_ 2365450494 BGSC: 8 Vector__XXX
 SG_ Bus1GeneratorAcPhaseDifference : 16|16@1+ (0.0078125,-200) [-200|301.9921875] "deg" Vector__XXX
 SG_ Bus1GeneratorDeadBus : 0|2@1+ (1,0) [0|3] "" Vector__XXX
 SG_ Bus1GeneratorFrequencyMatch : 4|2@1+ (1,0) [0|3] "" Vector__XXX
 SG_ Bus1GeneratorInSync : 8|2@1+ (1,0) [0|3] "" Vector__XXX
 SG_ Bus1GeneratorPhaseMatch : 2|2@1+ (1,0) [0|3] "" Vector__XXX
 SG_ Bus1GeneratorVoltageMatch : 6|2@1+ (1,0) [0|3] "" Vector__XXX

BO_ 2365450750 BPCAC: 8 Vector__XXX
 SG_ Bus1PhaseCAcFrequency : 32|16@1+ (0.0078125,0) [0|501.9921875] "Hz" Vector__XXX
 SG_ Bus1PhaseCaLineLineAcRmsVoltage : 0|16@1+ (1,0) [0|64255] "V" Vector__XXX
 SG_ Bs1PhsCLnNtrlARmsVltg : 16|16@1+ (1,0) [0|64255] "V" Vector__XXX

BO_ 2365451006 BPBAC: 8 Vector__XXX
 SG_ Bus1PhaseBAcFrequency : 32|16@1+ (0.0078125,0) [0|501.9921875] "Hz" Vector__XXX
 SG_ Bus1PhaseBcLineLineAcRmsVoltage : 0|16@1+ (1,0) [0|64255] "V" Vector__XXX
 SG_ Bs1PhsBLnNtrlARmsVltg : 16|16@1+ (1,0) [0|64255] "V" Vector__XXX

BO_ 2365451262 BPAAC: 8 Vector__XXX
 SG_ Bus1PhaseAAcFrequency : 32|16@1+ (0.0078125,0) [0|501.9921875] "Hz" Vector__XXX
 SG_ Bus1PhaseAbLineLineAcRmsVoltage : 0|16@1+ (1,0) [0|64255] "V" Vector__XXX
 SG_ Bs1PhsALnNtrlARmsVltg : 16|16@1+ (1,0) [0|64255] "V" Vector__XXX

BO_ 2365451518 BAAC: 8 Vector__XXX
 SG_ Bus1AverageAcFrequency : 32|16@1+ (0.0078125,0) [0|501.9921875] "Hz" Vector__XXX
 SG_ Bus1AverageLineLineAcRmsVoltage : 0|16@1+ (1,0) [0|64255] "V" Vector__XXX
 SG_ Bs1AvrgLnNtrlARmsVltg : 16|16@1+ (1,0) [0|64255] "V" Vector__XXX

BO_ 2365451774 UTACE: 8 Vector__XXX
 SG_ UtilityTotalKwHoursExport : 0|32@1+ (1,0) [0|4211081215] "kWh" Vector__XXX
 SG_ UtilityTotalKwHoursImport : 32|32@1+ (1,0) [0|4211081215] "kWh" Vector__XXX

BO_ 2365452030 UPCACR: 8 Vector__XXX
 SG_ UtilityPhaseCPowerFactor : 32|16@1+ (0.00006103515625,-1) [-1|2.92181396484375] "" Vector__XXX
 SG_ UtilityPhaseCPowerFactorLagging : 48|2@1+ (1,0) [0|3] "" Vector__XXX
 SG_ UtilityPhaseCReactivePower : 0|32@1+ (1,-2000000000) [-2000000000|2211081215] "VAr" Vector__XXX

BO_ 2365452286 UPCACP: 8 Vector__XXX
 SG_ UtilityPhaseCApparentPower : 32|32@1+ (1,-2000000000) [-2000000000|2211081215] "VA" Vector__XXX
 SG_ UtilityPhaseCRealPower : 0|32@1+ (1,-2000000000) [-2000000000|2211081215] "W" Vector__XXX

BO_ 2365452542 UPCAC: 8 Vector__XXX
 SG_ UtilityPhaseCAcFrequency : 32|16@1+ (0.0078125,0) [0|501.9921875] "Hz" Vector__XXX
 SG_ UtilityPhaseCAcRmsCurrent : 48|16@1+ (1,0) [0|64255] "A" Vector__XXX
 SG_ UtltPhsCLnLnARmsVltg : 0|16@1+ (1,0) [0|64255] "V" Vector__XXX
 SG_ UtltPhsCLnNtrlARmsVltg : 16|16@1+ (1,0) [0|64255] "V" Vector__XXX

BO_ 2365452798 UPBACR: 8 Vector__XXX
 SG_ UtilityPhaseBPowerFactor : 32|16@1+ (0.00006103515625,-1) [-1|2.92181396484375] "" Vector__XXX
 SG_ UtilityPhaseBPowerFactorLagging : 48|2@1+ (1,0) [0|3] "" Vector__XXX
 SG_ UtilityPhaseBReactivePower : 0|32@1+ (1,-2000000000) [-2000000000|2211081215] "VAr" Vector__XXX

BO_ 2365453054 UPBACP: 8 Vector__XXX
 SG_ UtilityPhaseBApparentPower : 32|32@1+ (1,-2000000000) [-2000000000|2211081215] "VA" Vector__XXX
 SG_ UtilityPhaseBRealPower : 0|32@1+ (1,-2000000000) [-2000000000|2211081215] "W" Vector__XXX

BO_ 2365453310 UPBAC: 8 Vector__XXX
 SG_ UtilityPhaseBAcFrequency : 32|16@1+ (0.0078125,0) [0|501.9921875] "Hz" Vector__XXX
 SG_ UtilityPhaseBAcRmsCurrent : 48|16@1+ (1,0) [0|64255] "A" Vector__XXX
 SG_ UtltPhsBLnLnARmsVltg : 0|16@1+ (1,0) [0|64255] "V" Vector__XXX
 SG_ UtltPhsBLnNtrlARmsVltg : 16|16@1+ (1,0) [0|64255] "V" Vector__XXX

BO_ 2365453566 UPACCR: 8 Vector__XXX
 SG_ UtilityPhaseAPowerFactor : 32|16@1+ (0.00006103515625,-1) [-1|2.92181396484375] "" Vector__XXX
 SG_ UtilityPhaseAPowerFactorLagging : 48|2@1+ (1,0) [0|3] "" Vector__XXX
 SG_ UtilityPhaseAReactivePower : 0|32@1+ (1,-2000000000) [-2000000000|2211081215] "VAr" Vector__XXX

BO_ 2365453822 UPAACP: 8 Vector__XXX
 SG_ UtilityPhaseAApparentPower : 32|32@1+ (1,-2000000000) [-2000000000|2211081215] "VA" Vector__XXX
 SG_ UtilityPhaseARealPower : 0|32@1+ (1,-2000000000) [-2000000000|2211081215] "W" Vector__XXX

BO_ 2365454078 UPAAC: 8 Vector__XXX
 SG_ UtilityPhaseAAcFrequency : 32|16@1+ (0.0078125,0) [0|501.9921875] "Hz" Vector__XXX
 SG_ UtilityPhaseAAcRmsCurrent : 48|16@1+ (1,0) [0|64255] "A" Vector__XXX
 SG_ UtltPhsALnLnARmsVltg : 0|16@1+ (1,0) [0|64255] "V" Vector__XXX
 SG_ UtltPhsALnNtrlARmsVltg : 16|16@1+ (1,0) [0|64255] "V" Vector__XXX

BO_ 2365454334 UTACR: 8 Vector__XXX
 SG_ UtilityOverallPowerFactor : 32|16@1+ (0.00006103515625,-1) [-1|2.92181396484375] "" Vector__XXX
 SG_ UtilityTotalReactivePower : 0|32@1+ (1,-2000000000) [-2000000000|2211081215] "VAr" Vector__XXX
 SG_ UtltOvrllPwrFtrLggng : 48|2@1+ (1,0) [0|3] "" Vector__XXX

BO_ 2365454590 UTACP: 8 Vector__XXX
 SG_ UtilityTotalApparentPower : 32|32@1+ (1,-2000000000) [-2000000000|2211081215] "VA" Vector__XXX
 SG_ UtilityTotalRealPower : 0|32@1+ (1,-2000000000) [-2000000000|2211081215] "W" Vector__XXX

BO_ 2365454846 UAAC: 8 Vector__XXX
 SG_ UtilityAverageAcFrequency : 32|16@1+ (0.0078125,0) [0|501.9921875] "Hz" Vector__XXX
 SG_ UtilityAverageAcRmsCurrent : 48|16@1+ (1,0) [0|64255] "A" Vector__XXX
 SG_ UtltAvrgLnLnARmsVltg : 0|16@1+ (1,0) [0|64255] "V" Vector__XXX
 SG_ UtltAvrgLnNtrlARmsVltg : 16|16@1+ (1,0) [0|64255] "V" Vector__XXX

BO_ 2365455102 GTACE: 8 Vector__XXX
 SG_ GeneratorTotalKwHoursExport : 0|32@1+ (1,0) [0|4211081215] "kWh" Vector__XXX
 SG_ GeneratorTotalKwHoursImport : 32|32@1+ (1,0) [0|4211081215] "kWh" Vector__XXX

BO_ 2365455358 GPCACR: 8 Vector__XXX
 SG_ GeneratorPhaseCPowerFactor : 32|16@1+ (0.00006103515625,-1) [-1|1] "" Vector__XXX
 SG_ GeneratorPhaseCReactivePower : 0|32@1+ (1,-2000000000) [-2000000000|2211081215] "VAr" Vector__XXX
 SG_ GnrtrPhsCPwrFtrLggng : 48|2@1+ (1,0) [0|3] "" Vector__XXX

BO_ 2365455614 GPCACP: 8 Vector__XXX
 SG_ GeneratorPhaseCApparentPower : 32|32@1+ (1,-2000000000) [-2000000000|2211081215] "VA" Vector__XXX
 SG_ GeneratorPhaseCRealPower : 0|32@1+ (1,-2000000000) [-2000000000|2211081215] "W" Vector__XXX

BO_ 2365455870 GPCAC: 8 Vector__XXX
 SG_ GeneratorPhaseCAcFrequency : 32|16@1+ (0.0078125,0) [0|501.9921875] "Hz" Vector__XXX
 SG_ GeneratorPhaseCAcRmsCurrent : 48|16@1+ (1,0) [0|64255] "A" Vector__XXX
 SG_ GnrtrPhsCLnLnARmsVltg : 0|16@1+ (1,0) [0|64255] "V" Vector__XXX
 SG_ GnrtrPhsCLnNtrlARmsVltg : 16|16@1+ (1,0) [0|64255] "V" Vector__XXX

BO_ 2365456126 GPBACRP: 8 Vector__XXX
 SG_ GeneratorPhaseBPowerFactor : 32|16@1+ (0.00006103515625,-1) [-1|1] "" Vector__XXX
 SG_ GeneratorPhaseBReactivePower : 0|32@1+ (1,-2000000000) [-2000000000|2211081215] "VAr" Vector__XXX
 SG_ GnrtrPhsBPwrFtrLggng : 48|2@1+ (1,0) [0|3] "" Vector__XXX

BO_ 2365456382 GPBACP: 8 Vector__XXX
 SG_ GeneratorPhaseBApparentPower : 32|32@1+ (1,-2000000000) [-2000000000|2211081215] "VA" Vector__XXX
 SG_ GeneratorPhaseBRealPower : 0|32@1+ (1,-2000000000) [-2000000000|2211081215] "W" Vector__XXX

BO_ 2365456894 GPAACR: 8 Vector__XXX
 SG_ GeneratorPhaseAPowerFactor : 32|16@1+ (0.00006103515625,-1) [-1|1] "" Vector__XXX
 SG_ GeneratorPhaseAReactivePower : 0|32@1+ (1,-2000000000) [-2000000000|2211081215] "VAr" Vector__XXX
 SG_ GnrtrPhsAPwrFtrLggng : 48|2@1+ (1,0) [0|3] "" Vector__XXX

BO_ 2365457150 GPAACP: 8 Vector__XXX
 SG_ GeneratorPhaseAApparentPower : 32|32@1+ (1,-2000000000) [-2000000000|2211081215] "VA" Vector__XXX
 SG_ GeneratorPhaseARealPower : 0|32@1+ (1,-2000000000) [-2000000000|2211081215] "W" Vector__XXX

BO_ 2365457406 GPAAC: 8 Vector__XXX
 SG_ GeneratorPhaseAAcFrequency : 32|16@1+ (0.0078125,0) [0|501.9921875] "Hz" Vector__XXX
 SG_ GeneratorPhaseAAcRmsCurrent : 48|16@1+ (1,0) [0|64255] "A" Vector__XXX
 SG_ GnrtrPhsALnLnARmsVltg : 0|16@1+ (1,0) [0|64255] "V" Vector__XXX
 SG_ GnrtrPhsALnNtrlARmsVltg : 16|16@1+ (1,0) [0|64255] "V" Vector__XXX

BO_ 2365457662 GTACR: 8 Vector__XXX
 SG_ GeneratorOverallPowerFactor : 32|16@1+ (0.00006103515625,-1) [-1|1] "" Vector__XXX
 SG_ GeneratorTotalReactivePower : 0|32@1+ (1,-2000000000) [-2000000000|2211081215] "VAr" Vector__XXX
 SG_ GnrtrOvrllPwrFtrLggng : 48|2@1+ (1,0) [0|3] "" Vector__XXX

BO_ 2365457918 GTACP: 8 Vector__XXX
 SG_ GeneratorTotalApparentPower : 32|32@1+ (1,-2000000000) [-2000000000|2211081215] "VA" Vector__XXX
 SG_ GeneratorTotalRealPower : 0|32@1+ (1,-2000000000) [-2000000000|2211081215] "W" Vector__XXX

BO_ 2365458174 GAAC: 8 Vector__XXX
 SG_ GeneratorAverageAcFrequency : 32|16@1+ (0.0078125,0) [0|501.9921875] "Hz" Vector__XXX
 SG_ GeneratorAverageAcRmsCurrent : 48|16@1+ (1,0) [0|64255] "A" Vector__XXX
 SG_ GnrtrAvrgLnLnARmsVltg : 0|16@1+ (1,0) [0|64255] "V" Vector__XXX
 SG_ GnrtrAvrgLnNtrlARmsVltg : 16|16@1+ (1,0) [0|64255] "V" Vector__XXX

BO_ 2365473278 LCMD: 8 Vector__XXX
 SG_ AlternateBeamHeadLightCommand : 2|2@1+ (1,0) [0|3] "" Vector__XXX
 SG_ BackUpLightAndAlarmHornCommand : 16|2@1+ (1,0) [0|3] "" Vector__XXX
 SG_ CenterStopLightCommand : 18|2@1+ (1,0) [0|3] "" Vector__XXX
 SG_ HighBeamHeadLightCommand : 6|2@1+ (1,0) [0|3] "" Vector__XXX
 SG_ ImplementClearanceLightCommand : 24|2@1+ (1,0) [0|3] "" Vector__XXX
 SG_ ImplementMarkerLightCommand : 28|2@1+ (1,0) [0|3] "" Vector__XXX
 SG_ ImplementOemOption1LightCommand : 50|2@1+ (1,0) [0|3] "" Vector__XXX
 SG_ ImplementOemOption2LightCommand : 48|2@1+ (1,0) [0|3] "" Vector__XXX
 SG_ ImplementRearWorkLightCommand : 62|2@1+ (1,0) [0|3] "" Vector__XXX
 SG_ ImplmntLftFngWrkLghtCmmnd : 60|2@1+ (1,0) [0|3] "" Vector__XXX
 SG_ ImplmntLftFrwrdWrkLghtCmmnd : 54|2@1+ (1,0) [0|3] "" Vector__XXX
 SG_ ImplmntRghtFngWrkLghtCmmnd : 52|2@1+ (1,0) [0|3] "" Vector__XXX
 SG_ ImplmntRghtFrwrdWrkLghtCmmnd : 58|2@1+ (1,0) [0|3] "" Vector__XXX
 SG_ LeftStopLightCommand : 22|2@1+ (1,0) [0|3] "" Vector__XXX
 SG_ LeftTurnSignalLightsCommand : 14|2@1+ (1,0) [0|3] "" Vector__XXX
 SG_ LightingDataRequestCommand : 56|2@1+ (1,0) [0|3] "" Vector__XXX
 SG_ LowBeamHeadLightCommand : 4|2@1+ (1,0) [0|3] "" Vector__XXX
 SG_ RearFogLightCommand : 32|2@1+ (1,0) [0|3] "" Vector__XXX
 SG_ RightStopLightCommand : 20|2@1+ (1,0) [0|3] "" Vector__XXX
 SG_ RightTurnSignalLightsCommand : 12|2@1+ (1,0) [0|3] "" Vector__XXX
 SG_ RotatingBeaconLightCommand : 10|2@1+ (1,0) [0|3] "" Vector__XXX
 SG_ RunningLightCommand : 0|2@1+ (1,0) [0|3] "" Vector__XXX
 SG_ TractorClearanceLightCommand : 26|2@1+ (1,0) [0|3] "" Vector__XXX
 SG_ TractorFrontFogLightsCommand : 8|2@1+ (1,0) [0|3] "" Vector__XXX
 SG_ TractorMarkerLightCommand : 30|2@1+ (1,0) [0|3] "" Vector__XXX
 SG_ TrtrFrntHghMntdWrkLghtsCmmnd : 46|2@1+ (1,0) [0|3] "" Vector__XXX
 SG_ TrtrFrntLwMntdWrkLghtsCmmnd : 44|2@1+ (1,0) [0|3] "" Vector__XXX
 SG_ TrtrRrHghMntdWrkLghtsCmmnd : 38|2@1+ (1,0) [0|3] "" Vector__XXX
 SG_ TrtrRrLwMntdWrkLghtsCmmnd : 36|2@1+ (1,0) [0|3] "" Vector__XXX
 SG_ TrtrSdHghMntdWrkLghtsCmmnd : 42|2@1+ (1,0) [0|3] "" Vector__XXX
 SG_ TrtrSdLwMntdWrkLghtsCmmnd : 40|2@1+ (1,0) [0|3] "" Vector__XXX
 SG_ TrtrUndrsdMntdWrkLghtsCmmnd : 34|2@1+ (1,0) [0|3] "" Vector__XXX

BO_ 2365478910 ASC5: 8 Vector__XXX
 SG_ DamperStiffnessFrontAxle : 0|8@1+ (0.4,0) [0|100] "%" Vector__XXX
 SG_ DamperStiffnessLiftTagAxle : 16|8@1+ (0.4,0) [0|100] "%" Vector__XXX
 SG_ DamperStiffnessRearAxle : 8|8@1+ (0.4,0) [0|100] "%" Vector__XXX
 SG_ EltrnShkAsrrCntrlMdFrntAxl : 24|2@1+ (1,0) [0|3] "" Vector__XXX
 SG_ EltrnShkAsrrCntrlMdLftTgAxl : 28|2@1+ (1,0) [0|3] "" Vector__XXX
 SG_ EltrnShkAsrrCntrlMdRrAxl : 26|2@1+ (1,0) [0|3] "" Vector__XXX

BO_ 2365479678 ASC1: 8 Vector__XXX
 SG_ AboveNominalLevelFrontAxle : 12|2@1+ (1,0) [0|3] "" Vector__XXX
 SG_ AboveNominalLevelRearAxle : 14|2@1+ (1,0) [0|3] "" Vector__XXX
 SG_ AllwLvlCntrlDrngBrkngStts : 52|2@1+ (1,0) [0|3] "" Vector__XXX
 SG_ BelowNominalLevelFrontAxle : 8|2@1+ (1,0) [0|3] "" Vector__XXX
 SG_ BelowNominalLevelRearAxle : 10|2@1+ (1,0) [0|3] "" Vector__XXX
 SG_ DoorRelease : 36|2@1+ (1,0) [0|3] "" Vector__XXX
 SG_ FrontAxleInBumperRange : 40|2@1+ (1,0) [0|3] "" Vector__XXX
 SG_ KneelingInformation : 24|4@1+ (1,0) [0|15] "" Vector__XXX
 SG_ LevelControlMode : 28|4@1+ (1,0) [0|15] "" Vector__XXX
 SG_ LiftAxle1Position : 38|2@1+ (1,0) [0|3] "" Vector__XXX
 SG_ LiftAxle2Position : 46|2@1+ (1,0) [0|3] "" Vector__XXX
 SG_ LiftingControlModeFrontAxle : 20|2@1+ (1,0) [0|3] "" Vector__XXX
 SG_ LiftingControlModeRearAxle : 22|2@1+ (1,0) [0|3] "" Vector__XXX
 SG_ LoweringControlModeFrontAxle : 16|2@1+ (1,0) [0|3] "" Vector__XXX
 SG_ LoweringControlModeRearAxle : 18|2@1+ (1,0) [0|3] "" Vector__XXX
 SG_ MemoryLevel : 60|4@1+ (1,0) [0|15] "" Vector__XXX
 SG_ NominalLevelFrontAxle : 0|4@1+ (1,0) [0|15] "" Vector__XXX
 SG_ NominalLevelRearAxle : 4|4@1+ (1,0) [0|15] "" Vector__XXX
 SG_ RearAxleInBumperRange : 42|2@1+ (1,0) [0|3] "" Vector__XXX
 SG_ SecurityDevice : 32|2@1+ (1,0) [0|3] "" Vector__XXX
 SG_ SpdDpndntLvlCntrlStts : 54|2@1+ (1,0) [0|3] "" Vector__XXX
 SG_ SspnsnCntrlRfslInfrmtn : 56|4@1+ (1,0) [0|15] "" Vector__XXX
 SG_ SuspensionRemoteControl1 : 48|2@1+ (1,0) [0|3] "" Vector__XXX
 SG_ SuspensionRemoteControl2 : 50|2@1+ (1,0) [0|3] "" Vector__XXX
 SG_ VehicleMotionInhibit : 34|2@1+ (1,0) [0|3] "" Vector__XXX

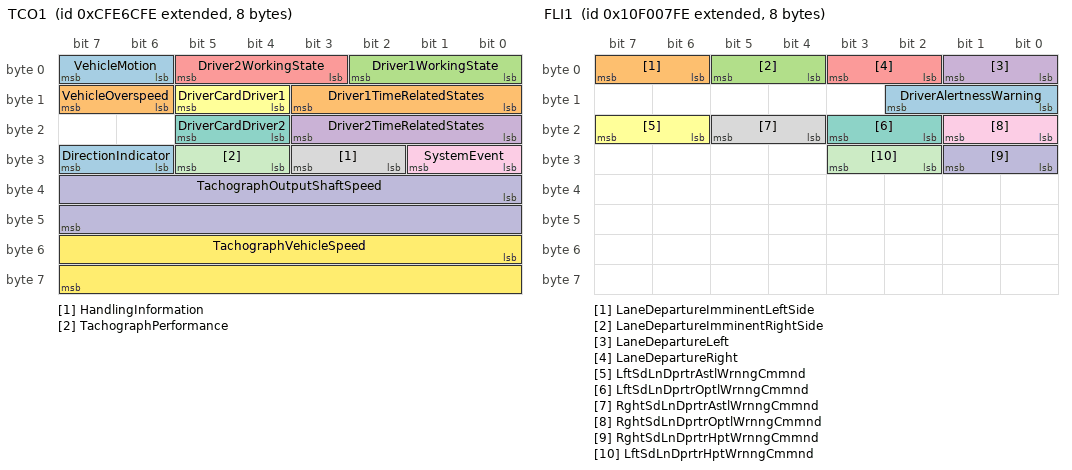
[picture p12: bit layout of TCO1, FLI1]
BO_ 2365484286 TCO1: 8 Vector__XXX
 SG_ DirectionIndicator : 30|2@1+ (1,0) [0|3] "" Vector__XXX
 SG_ Driver1TimeRelatedStates : 8|4@1+ (1,0) [0|15] "" Vector__XXX
 SG_ Driver1WorkingState : 0|3@1+ (1,0) [0|7] "" Vector__XXX
 SG_ Driver2TimeRelatedStates : 16|4@1+ (1,0) [0|15] "" Vector__XXX
 SG_ Driver2WorkingState : 3|3@1+ (1,0) [0|7] "" Vector__XXX
 SG_ DriverCardDriver1 : 12|2@1+ (1,0) [0|3] "" Vector__XXX
 SG_ DriverCardDriver2 : 20|2@1+ (1,0) [0|3] "" Vector__XXX
 SG_ HandlingInformation : 26|2@1+ (1,0) [0|3] "" Vector__XXX
 SG_ SystemEvent : 24|2@1+ (1,0) [0|3] "" Vector__XXX
 SG_ TachographOutputShaftSpeed : 32|16@1+ (0.125,0) [0|8031.875] "rpm" Vector__XXX
 SG_ TachographPerformance : 28|2@1+ (1,0) [0|3] "" Vector__XXX
 SG_ TachographVehicleSpeed : 48|16@1+ (0.00390625,0) [0|250.99609375] "km/h" Vector__XXX
 SG_ VehicleMotion : 6|2@1+ (1,0) [0|3] "" Vector__XXX
 SG_ VehicleOverspeed : 14|2@1+ (1,0) [0|3] "" Vector__XXX

BO_ 2365485566 LTP: 8 Vector__XXX
 SG_ LaserTracerHorizontalDeviation : 32|8@1+ (1,0) [0|200] "%" Vector__XXX
 SG_ LaserTracerInformation : 48|8@1+ (1,0) [0|250] "" Vector__XXX
 SG_ LaserTracerTargetDeviation : 0|16@1+ (0.1,-3200) [-3200|3200] "mm" Vector__XXX
 SG_ LaserTracerVerticalDistance : 16|16@1+ (0.1,0) [0|6400] "mm" Vector__XXX
 SG_ LedDisplayData2 : 40|8@1+ (1,0) [0|250] "" Vector__XXX

BO_ 2365485822 LBC: 8 Vector__XXX
 SG_ BladeControlMode : 16|8@1+ (1,0) [0|250] "" Vector__XXX
 SG_ BladeControlModeLeft : 24|4@1+ (1,0) [0|15] "" Vector__XXX
 SG_ BladeControlModeRight : 28|4@1+ (1,0) [0|15] "" Vector__XXX
 SG_ BladeDurationAndDirection : 0|16@1+ (0.1,-3276.8) [-3276.8|3148.7] "s" Vector__XXX
 SG_ LandLevelingSystemEnableStatus : 32|2@1+ (1,0) [0|3] "" Vector__XXX

BO_ 2365486078 LMP: 8 Vector__XXX
 SG_ MastPosition : 0|16@1+ (0.1,-3200) [-3200|3200] "mm" Vector__XXX

BO_ 2365486334 LSP: 8 Vector__XXX
 SG_ BldHghtStPntHghRsltn : 16|32@1+ (0.0000001,-209.7152) [-209.7152|209.7152] "m" Vector__XXX
 SG_ ModifyLevelingSystemSetPoint : 0|16@1+ (0.1,-3200) [-3200|3225.5] "mm" Vector__XXX

BO_ 2365486590 LVD: 8 Vector__XXX
 SG_ AbsoluteLaserStrikePosition : 40|16@1+ (0.1,0) [0|6425.5] "mm" Vector__XXX
 SG_ LaserReceiverType : 16|8@1+ (1,0) [1|4] "count" Vector__XXX
 SG_ LaserStrikeDataLatency : 24|16@1+ (0.0000512,0) [0|3.289856] "s" Vector__XXX
 SG_ LaserStrikeVerticalDeviation : 0|16@1+ (0.1,-3200) [-3200|3200] "mm" Vector__XXX

BO_ 2431649790 FLI1: 8 Vector__XXX
 SG_ DriverAlertnessWarning : 8|3@1+ (1,0) [0|7] "" Vector__XXX
 SG_ LaneDepartureImminentLeftSide : 6|2@1+ (1,0) [0|3] "" Vector__XXX
 SG_ LaneDepartureImminentRightSide : 4|2@1+ (1,0) [0|3] "" Vector__XXX
 SG_ LaneDepartureLeft : 0|2@1+ (1,0) [0|3] "" Vector__XXX
 SG_ LaneDepartureRight : 2|2@1+ (1,0) [0|3] "" Vector__XXX
 SG_ LftSdLnDprtrAstlWrnngCmmnd : 22|2@1+ (1,0) [0|3] "" Vector__XXX
 SG_ LftSdLnDprtrOptlWrnngCmmnd : 18|2@1+ (1,0) [0|3] "" Vector__XXX
 SG_ RghtSdLnDprtrAstlWrnngCmmnd : 20|2@1+ (1,0) [0|3] "" Vector__XXX
 SG_ RghtSdLnDprtrOptlWrnngCmmnd : 16|2@1+ (1,0) [0|3] "" Vector__XXX
 SG_ RghtSdLnDprtrHptWrnngCmmnd : 24|2@1+ (1,0) [0|3] "" Vector__XXX
 SG_ LftSdLnDprtrHptWrnngCmmnd : 26|2@1+ (1,0) [0|3] "" Vector__XXX

BO_ 2431654654 TFAC: 8 Vector__XXX
 SG_ EngnFlAttr1CntrlCmmnd : 32|16@1+ (0.0025,0) [0|100] "%" Vector__XXX
 SG_ EngnFlAttr2CntrlCmmnd : 48|16@1+ (0.0025,0) [0|100] "%" Vector__XXX
 SG_ EngnThrttlAttr1CntrlCmmnd : 0|16@1+ (0.0025,0) [0|100] "%" Vector__XXX
 SG_ EngnThrttlAttr2CntrlCmmnd : 16|16@1+ (0.0025,0) [0|100] "%" Vector__XXX

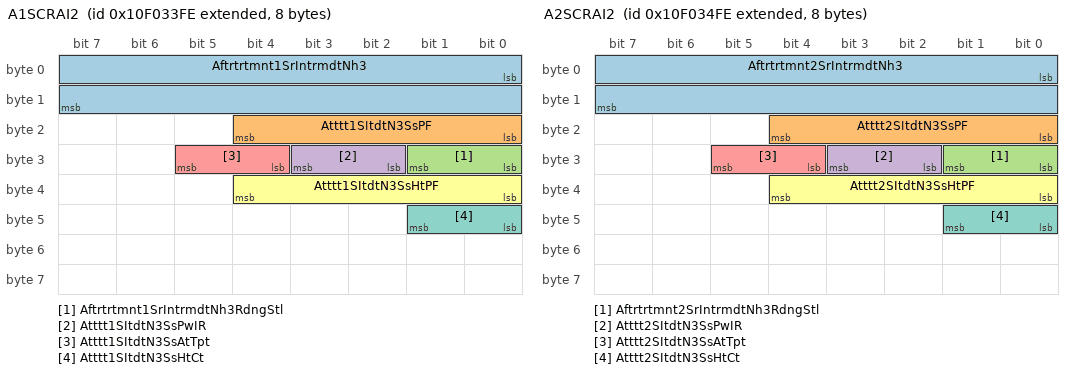
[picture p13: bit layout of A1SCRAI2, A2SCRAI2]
BO_ 2431661054 A1SCRAI2: 8 Vector__XXX
 SG_ Aftrtrtmnt1SrIntrmdtNh3 : 0|16@1+ (0.1,-200) [-200|6225.5] "ppm" Vector__XXX
 SG_ Atttt1SItdtN3SsPF : 16|5@1+ (1,0) [0|31] "" Vector__XXX
 SG_ Aftrtrtmnt1SrIntrmdtNh3RdngStl : 24|2@1+ (1,0) [0|3] "" Vector__XXX
 SG_ Atttt1SItdtN3SsPwIR : 26|2@1+ (1,0) [0|3] "" Vector__XXX
 SG_ Atttt1SItdtN3SsAtTpt : 28|2@1+ (1,0) [0|3] "" Vector__XXX
 SG_ Atttt1SItdtN3SsHtPF : 32|5@1+ (1,0) [0|31] "" Vector__XXX
 SG_ Atttt1SItdtN3SsHtCt : 40|2@1+ (1,0) [0|3] "" Vector__XXX

BO_ 2431661310 A2SCRAI2: 8 Vector__XXX
 SG_ Aftrtrtmnt2SrIntrmdtNh3 : 0|16@1+ (0.1,-200) [-200|6225.5] "ppm" Vector__XXX
 SG_ Atttt2SItdtN3SsPF : 16|5@1+ (1,0) [0|31] "" Vector__XXX
 SG_ Aftrtrtmnt2SrIntrmdtNh3RdngStl : 24|2@1+ (1,0) [0|3] "" Vector__XXX
 SG_ Atttt2SItdtN3SsPwIR : 26|2@1+ (1,0) [0|3] "" Vector__XXX
 SG_ Atttt2SItdtN3SsAtTpt : 28|2@1+ (1,0) [0|3] "" Vector__XXX
 SG_ Atttt2SItdtN3SsHtPF : 32|5@1+ (1,0) [0|31] "" Vector__XXX
 SG_ Atttt2SItdtN3SsHtCt : 40|2@1+ (1,0) [0|3] "" Vector__XXX

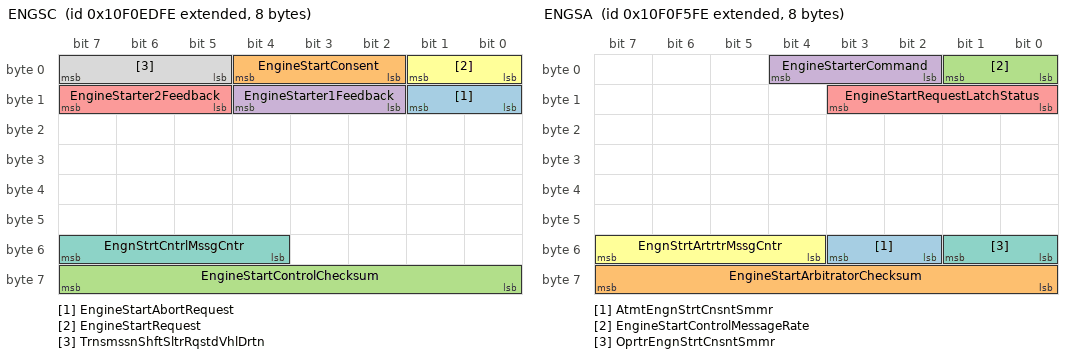
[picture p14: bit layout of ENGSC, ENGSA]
BO_ 2431708670 ENGSC: 8 Vector__XXX
 SG_ EngineStartAbortRequest : 8|2@1+ (1,0) [0|3] "" Vector__XXX
 SG_ EngineStartConsent : 2|3@1+ (1,0) [0|7] "" Vector__XXX
 SG_ EngineStartControlChecksum : 56|8@1+ (1,0) [0|250] "count" Vector__XXX
 SG_ EngineStarter1Feedback : 10|3@1+ (1,0) [0|7] "" Vector__XXX
 SG_ EngineStarter2Feedback : 13|3@1+ (1,0) [0|7] "" Vector__XXX
 SG_ EngineStartRequest : 0|2@1+ (1,0) [0|3] "" Vector__XXX
 SG_ EngnStrtCntrlMssgCntr : 52|4@1+ (1,0) [0|15] "" Vector__XXX
 SG_ TrnsmssnShftSltrRqstdVhlDrtn : 5|3@1+ (1,0) [0|7] "" Vector__XXX

BO_ 2431710718 ENGSA: 8 Vector__XXX
 SG_ AtmtEngnStrtCnsntSmmr : 50|2@1+ (1,0) [0|3] "" Vector__XXX
 SG_ EngineStartArbitratorChecksum : 56|8@1+ (1,0) [0|250] "count" Vector__XXX
 SG_ EngineStartControlMessageRate : 0|2@1+ (1,0) [0|3] "" Vector__XXX
 SG_ EngineStarterCommand : 2|3@1+ (1,0) [0|7] "" Vector__XXX
 SG_ EngineStartRequestLatchStatus : 8|4@1+ (1,0) [0|15] "" Vector__XXX
 SG_ EngnStrtArtrtrMssgCntr : 52|4@1+ (1,0) [0|15] "" Vector__XXX
 SG_ OprtrEngnStrtCnsntSmmr : 48|2@1+ (1,0) [0|3] "" Vector__XXX

BO_ 2431717886 GFP3: 8 Vector__XXX
 SG_ EngnFlVlv1DffrntlPrssrHghRsltn : 0|16@1+ (0.0078125,-100) [-100|401.9921875] "kPa" Vector__XXX
 SG_ EngnGssFlSpplFltrDffrntlPrssr : 16|16@1+ (0.0078125,-100) [-100|401.9921875] "kPa" Vector__XXX
 SG_ EngnGssFlSpplFltrIntkPrssr : 32|16@1+ (0.5,0) [0|32127.5] "kPa" Vector__XXX

BO_ 2431719166 WSP3: 8 Vector__XXX
 SG_ WellStimulationPumpFlowRate : 24|16@1+ (0.5,0) [0|32127.5] "l/min" Vector__XXX
 SG_ WellStimulationPumpRodLoad : 0|16@1+ (5,0) [0|321275] "kN" Vector__XXX
 SG_ WllStmltnPmpCvttnStts : 16|3@1+ (1,0) [0|7] "" Vector__XXX
 SG_ WllStmltnPmpFldEndVlvLk : 20|2@1+ (1,0) [0|3] "" Vector__XXX
 SG_ WllStmltnPmpRtdRdLdPrnt : 40|8@1+ (0.5,0) [0|125] "%" Vector__XXX

BO_ 2432471038 AF3: 8 Vector__XXX
 SG_ EngnFlVprzr1DshrgTmprtr : 16|8@1+ (1,-40) [-40|210] "degC" Vector__XXX
 SG_ EngnGssFlSpplPrssr1ExtnddRng : 0|16@1+ (0.00390625,0) [0|250.99609375] "MPa" Vector__XXX
 SG_ GssFlAmltrTmprtr : 24|8@1+ (1,-40) [-40|210] "degC" Vector__XXX
 SG_ EGssF1SppPssRtCtCd : 32|16@1+ (0.0025,0) [0|160.6375] "%" Vector__XXX
 SG_ EGssF2SppPssRtCtCd : 48|16@1+ (0.0025,0) [0|160.6375] "%" Vector__XXX

BO_ 2432492542 EBCC: 8 Vector__XXX
 SG_ EngnExhstBrkAttrCmmnd : 16|8@1+ (0.4,0) [0|100] "%" Vector__XXX
 SG_ EngnTrhrgr1TrnDsrdOtltPrssr : 8|8@1+ (2,0) [0|500] "kPa" Vector__XXX
 SG_ EngnTrhrgr1TrnOtltPrssr : 0|8@1+ (2,0) [0|500] "kPa" Vector__XXX
 SG_ EngnTrhrgr2TrnDsrdOtltPrssr : 32|8@1+ (2,0) [0|500] "kPa" Vector__XXX
 SG_ EngnTrhrgr2TrnOtltPrssr : 24|8@1+ (2,0) [0|500] "kPa" Vector__XXX

BO_ 2432499198 EEC9: 8 Vector__XXX
 SG_ CmmnddEngnFlInjtnCntrlPrssr : 48|16@1+ (0.00390625,0) [0|250.99609375] "MPa" Vector__XXX
 SG_ CommandedEngineFuelRailPressure : 32|16@1+ (0.00390625,0) [0|250.99609375] "MPa" Vector__XXX
 SG_ EngnExhstGsRrltn2Vlv2Pstn : 16|16@1+ (0.0025,0) [0|160.6375] "%" Vector__XXX
 SG_ EngnExhstGsRrltn2VlvPstn : 0|16@1+ (0.0025,0) [0|160.6375] "%" Vector__XXX

BO_ 2432520702 ACCVC: 8 Vector__XXX
 SG_ EngnChrgArClrBpssVlv1Cmmnd : 24|16@1+ (0.0025,0) [0|160.6375] "%" Vector__XXX
 SG_ EngnChrgArClrBpssVlv2Cmmnd : 40|16@1+ (0.0025,0) [0|160.6375] "%" Vector__XXX
 SG_ EngnAftrlrClntThrmsttMd : 0|2@1+ (1,0) [0|3] "" Vector__XXX
 SG_ EngnDsrdAftrlrClntIntkTmprtr : 8|8@1+ (1,-40) [-40|210] "degC" Vector__XXX
 SG_ EngnDsrdAftrlrClntThrmsttOpnng : 16|8@1+ (0.4,0) [0|100] "%" Vector__XXX
 SG_ EngnAftrlrClntDvrtrVlvCmmnd : 56|8@1+ (0.4,0) [0|100] "%" Vector__XXX

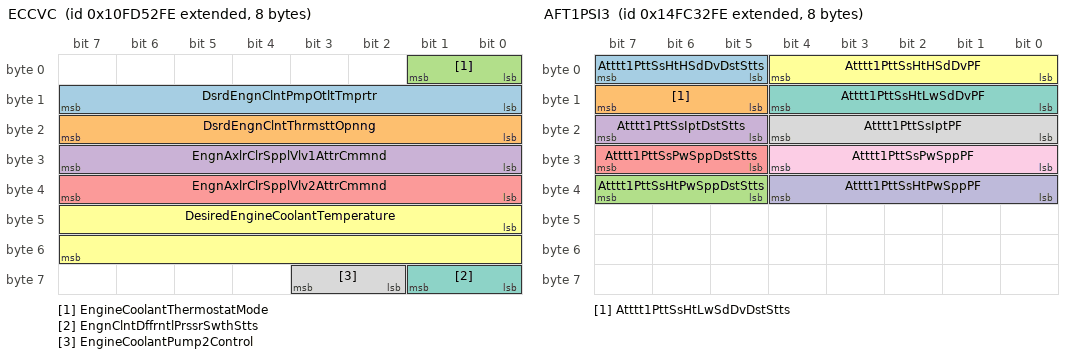
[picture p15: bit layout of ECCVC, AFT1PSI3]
BO_ 2432520958 ECCVC: 8 Vector__XXX
 SG_ DsrdEngnClntPmpOtltTmprtr : 8|8@1+ (1,-40) [-40|210] "degC" Vector__XXX
 SG_ DsrdEngnClntThrmsttOpnng : 16|8@1+ (0.4,0) [0|100] "%" Vector__XXX
 SG_ EngineCoolantThermostatMode : 0|2@1+ (1,0) [0|3] "" Vector__XXX
 SG_ EngnAxlrClrSpplVlv1AttrCmmnd : 24|8@1+ (0.4,0) [0|100] "%" Vector__XXX
 SG_ EngnAxlrClrSpplVlv2AttrCmmnd : 32|8@1+ (0.4,0) [0|100] "%" Vector__XXX
 SG_ DesiredEngineCoolantTemperature : 40|16@1+ (0.03125,-273) [-273|1734.96875] "degC" Vector__XXX
 SG_ EngnClntDffrntlPrssrSwthStts : 56|2@1+ (1,0) [0|3] "" Vector__XXX
 SG_ EngineCoolantPump2Control : 58|2@1+ (1,0) [0|3] "" Vector__XXX

BO_ 2432541438 GFI3: 8 Vector__XXX
 SG_ EngineFuel1Temperature2 : 32|8@1+ (1,-40) [-40|210] "degC" Vector__XXX
 SG_ EngnFlSstm2GsMssFlwRt : 16|16@1+ (0.05,0) [0|3212.75] "kg/h" Vector__XXX
 SG_ EngnFlVlv2IntkAsltPrssr : 0|16@1+ (0.1,0) [0|6425.5] "kPa" Vector__XXX
 SG_ EngnFlVlv2OtltAsltPrssr : 48|16@1+ (0.1,0) [0|6425.5] "kPa" Vector__XXX

BO_ 2432541694 EEC6: 8 Vector__XXX
 SG_ EngnTrhrgrCmprssrBpssAttr1Cmmnd : 0|16@1+ (0.0025,0) [0|100] "%" Vector__XXX
 SG_ EngnTrhrgrCmprssrBpssAttr1Pstn : 24|8@1+ (0.4,0) [0|100] "%" Vector__XXX
 SG_ EngnTrhrgrCmprssrBpssAttr2Cmmnd : 32|16@1+ (0.0025,0) [0|160.6375] "%" Vector__XXX
 SG_ EngnVrlGmtrTrhrgrAttr1 : 16|8@1+ (0.4,0) [0|100] "%" Vector__XXX
 SG_ ETCpssBpssAtt1DsdPst : 48|8@1+ (0.4,0) [0|100] "%" Vector__XXX
 SG_ ETCpssBpssAtt1TptStts : 61|3@1+ (1,0) [0|7] "" Vector__XXX
 SG_ ETCpssBpssAtt1PF : 56|5@1+ (1,0) [0|31] "" Vector__XXX

BO_ 2432593918 ACC1: 8 Vector__XXX
 SG_ AccDistanceAlertSignal : 52|2@1+ (1,0) [0|3] "" Vector__XXX
 SG_ AccSystemShutoffWarning : 50|2@1+ (1,0) [0|3] "" Vector__XXX
 SG_ AccTargetDetected : 48|2@1+ (1,0) [0|3] "" Vector__XXX
 SG_ AdaptiveCruiseControlMode : 24|3@1+ (1,0) [0|7] "" Vector__XXX
 SG_ AdaptiveCruiseControlSetSpeed : 16|8@1+ (1,0) [0|120] "km/h" Vector__XXX
 SG_ DistanceToForwardVehicle : 8|8@1+ (1,0) [0|250] "m" Vector__XXX
 SG_ ForwardCollisionWarning : 54|2@1+ (1,0) [0|3] "" Vector__XXX
 SG_ RoadCurvature : 32|16@1+ (0.0078125,-250) [-250|251.9921875] "1/km" Vector__XXX
 SG_ SpeedOfForwardVehicle : 0|8@1+ (1,0) [0|250] "km/h" Vector__XXX
 SG_ AdptvCrsCntrlStDstnMd : 27|3@1+ (1,0) [0|7] "" Vector__XXX

BO_ 2432595710 LVDD: 8 Vector__XXX
 SG_ DisplayDeadbands : 20|4@1+ (1,0) [0|15] "" Vector__XXX
 SG_ LedDisplayData1 : 0|8@1+ (1,0) [0|250] "" Vector__XXX
 SG_ LedDisplayDeadbandControl : 12|4@1+ (1,0) [0|15] "" Vector__XXX
 SG_ LedDisplayModeControl : 8|4@1+ (1,0) [0|15] "" Vector__XXX
 SG_ LedPatternControl : 16|4@1+ (1,0) [0|15] "" Vector__XXX

BO_ 2498776830 ECCAI1: 8 Vector__XXX
 SG_ EngnClndr1AvrgCmstnDrtn : 48|16@1+ (0.0078125,0) [0|501.9921875] "deg" Vector__XXX
 SG_ EngnClndr1IndtdMnEfftvPrssr : 0|16@1+ (0.0001220703125,-1) [-1|6.8436279296875] "MPa" Vector__XXX
 SG_ EngnClndr1AvrgStrtOfCmstnTmng : 16|16@1+ (0.0078125,-250) [-250|251.9921875] "deg" Vector__XXX
 SG_ EngnClndr1AvrgCntrOfCmstnTmng : 32|16@1+ (0.0078125,-250) [-250|251.9921875] "deg" Vector__XXX

BO_ 2498777086 ECCAI2: 8 Vector__XXX
 SG_ EngnClndr2AvrgCmstnDrtn : 48|16@1+ (0.0078125,0) [0|501.9921875] "deg" Vector__XXX
 SG_ EngnClndr2IndtdMnEfftvPrssr : 0|16@1+ (0.0001220703125,-1) [-1|6.8436279296875] "MPa" Vector__XXX
 SG_ EngnClndr2AvrgStrtOfCmstnTmng : 16|16@1+ (0.0078125,-250) [-250|251.9921875] "deg" Vector__XXX
 SG_ EngnClndr2AvrgCntrOfCmstnTmng : 32|16@1+ (0.0078125,-250) [-250|251.9921875] "deg" Vector__XXX

BO_ 2498777342 ECCAI3: 8 Vector__XXX
 SG_ EngnClndr3AvrgCmstnDrtn : 48|16@1+ (0.0078125,0) [0|501.9921875] "deg" Vector__XXX
 SG_ EngnClndr3IndtdMnEfftvPrssr : 0|16@1+ (0.0001220703125,-1) [-1|6.8436279296875] "MPa" Vector__XXX
 SG_ EngnClndr3AvrgStrtOfCmstnTmng : 16|16@1+ (0.0078125,-250) [-250|251.9921875] "deg" Vector__XXX
 SG_ EngnClndr3AvrgCntrOfCmstnTmng : 32|16@1+ (0.0078125,-250) [-250|251.9921875] "deg" Vector__XXX

BO_ 2498777598 ECCAI4: 8 Vector__XXX
 SG_ EngnClndr4AvrgCmstnDrtn : 48|16@1+ (0.0078125,0) [0|501.9921875] "deg" Vector__XXX
 SG_ EngnClndr4IndtdMnEfftvPrssr : 0|16@1+ (0.0001220703125,-1) [-1|6.8436279296875] "MPa" Vector__XXX
 SG_ EngnClndr4AvrgStrtOfCmstnTmng : 16|16@1+ (0.0078125,-250) [-250|251.9921875] "deg" Vector__XXX
 SG_ EngnClndr4AvrgCntrOfCmstnTmng : 32|16@1+ (0.0078125,-250) [-250|251.9921875] "deg" Vector__XXX

BO_ 2498777854 ECCAI5: 8 Vector__XXX
 SG_ EngnClndr5AvrgCmstnDrtn : 48|16@1+ (0.0078125,0) [0|501.9921875] "deg" Vector__XXX
 SG_ EngnClndr5IndtdMnEfftvPrssr : 0|16@1+ (0.0001220703125,-1) [-1|6.8436279296875] "MPa" Vector__XXX
 SG_ EngnClndr5AvrgStrtOfCmstnTmng : 16|16@1+ (0.0078125,-250) [-250|251.9921875] "deg" Vector__XXX
 SG_ EngnClndr5AvrgCntrOfCmstnTmng : 32|16@1+ (0.0078125,-250) [-250|251.9921875] "deg" Vector__XXX

BO_ 2498778110 ECCAI6: 8 Vector__XXX
 SG_ EngnClndr6AvrgCmstnDrtn : 48|16@1+ (0.0078125,0) [0|501.9921875] "deg" Vector__XXX
 SG_ EngnClndr6IndtdMnEfftvPrssr : 0|16@1+ (0.0001220703125,-1) [-1|6.8436279296875] "MPa" Vector__XXX
 SG_ EngnClndr6AvrgStrtOfCmstnTmng : 16|16@1+ (0.0078125,-250) [-250|251.9921875] "deg" Vector__XXX
 SG_ EngnClndr6AvrgCntrOfCmstnTmng : 32|16@1+ (0.0078125,-250) [-250|251.9921875] "deg" Vector__XXX

BO_ 2498778366 ECCAI7: 8 Vector__XXX
 SG_ EngnClndr7AvrgCmstnDrtn : 48|16@1+ (0.0078125,0) [0|501.9921875] "deg" Vector__XXX
 SG_ EngnClndr7IndtdMnEfftvPrssr : 0|16@1+ (0.0001220703125,-1) [-1|6.8436279296875] "MPa" Vector__XXX
 SG_ EngnClndr7AvrgStrtOfCmstnTmng : 16|16@1+ (0.0078125,-250) [-250|251.9921875] "deg" Vector__XXX
 SG_ EngnClndr7AvrgCntrOfCmstnTmng : 32|16@1+ (0.0078125,-250) [-250|251.9921875] "deg" Vector__XXX

BO_ 2498778622 ECCAI8: 8 Vector__XXX
 SG_ EngnClndr8AvrgCmstnDrtn : 48|16@1+ (0.0078125,0) [0|501.9921875] "deg" Vector__XXX
 SG_ EngnClndr8IndtdMnEfftvPrssr : 0|16@1+ (0.0001220703125,-1) [-1|6.8436279296875] "MPa" Vector__XXX
 SG_ EngnClndr8AvrgStrtOfCmstnTmng : 16|16@1+ (0.0078125,-250) [-250|251.9921875] "deg" Vector__XXX
 SG_ EngnClndr8AvrgCntrOfCmstnTmng : 32|16@1+ (0.0078125,-250) [-250|251.9921875] "deg" Vector__XXX

BO_ 2498778878 ECCAI9: 8 Vector__XXX
 SG_ EngnClndr9AvrgCmstnDrtn : 48|16@1+ (0.0078125,0) [0|501.9921875] "deg" Vector__XXX
 SG_ EngnClndr9IndtdMnEfftvPrssr : 0|16@1+ (0.0001220703125,-1) [-1|6.8436279296875] "MPa" Vector__XXX
 SG_ EngnClndr9AvrgStrtOfCmstnTmng : 16|16@1+ (0.0078125,-250) [-250|251.9921875] "deg" Vector__XXX
 SG_ EngnClndr9AvrgCntrOfCmstnTmng : 32|16@1+ (0.0078125,-250) [-250|251.9921875] "deg" Vector__XXX

BO_ 2498779134 ECCAI10: 8 Vector__XXX
 SG_ EngnClndr10AvrgCmstnDrtn : 48|16@1+ (0.0078125,0) [0|501.9921875] "deg" Vector__XXX
 SG_ EngnClndr10IndtdMnEfftvPrssr : 0|16@1+ (0.0001220703125,-1) [-1|6.8436279296875] "MPa" Vector__XXX
 SG_ EngnClndr10AvrgStrtOfCmstnTmng : 16|16@1+ (0.0078125,-250) [-250|251.9921875] "deg" Vector__XXX
 SG_ EngnClndr10AvrgCntrOfCmstnTmng : 32|16@1+ (0.0078125,-250) [-250|251.9921875] "deg" Vector__XXX

BO_ 2498779390 ECCAI11: 8 Vector__XXX
 SG_ EngnClndr11AvrgCmstnDrtn : 48|16@1+ (0.0078125,0) [0|501.9921875] "deg" Vector__XXX
 SG_ EngnClndr11IndtdMnEfftvPrssr : 0|16@1+ (0.0001220703125,-1) [-1|6.8436279296875] "MPa" Vector__XXX
 SG_ EngnClndr11AvrgStrtOfCmstnTmng : 16|16@1+ (0.0078125,-250) [-250|251.9921875] "deg" Vector__XXX
 SG_ EngnClndr11AvrgCntrOfCmstnTmng : 32|16@1+ (0.0078125,-250) [-250|251.9921875] "deg" Vector__XXX

BO_ 2498779646 ECCAI12: 8 Vector__XXX
 SG_ EngnClndr12AvrgCmstnDrtn : 48|16@1+ (0.0078125,0) [0|501.9921875] "deg" Vector__XXX
 SG_ EngnClndr12IndtdMnEfftvPrssr : 0|16@1+ (0.0001220703125,-1) [-1|6.8436279296875] "MPa" Vector__XXX
 SG_ EngnClndr12AvrgStrtOfCmstnTmng : 16|16@1+ (0.0078125,-250) [-250|251.9921875] "deg" Vector__XXX
 SG_ EngnClndr12AvrgCntrOfCmstnTmng : 32|16@1+ (0.0078125,-250) [-250|251.9921875] "deg" Vector__XXX

BO_ 2498779902 ECCAI13: 8 Vector__XXX
 SG_ EngnClndr13AvrgCmstnDrtn : 48|16@1+ (0.0078125,0) [0|501.9921875] "deg" Vector__XXX
 SG_ EngnClndr13IndtdMnEfftvPrssr : 0|16@1+ (0.0001220703125,-1) [-1|6.8436279296875] "MPa" Vector__XXX
 SG_ EngnClndr13AvrgStrtOfCmstnTmng : 16|16@1+ (0.0078125,-250) [-250|251.9921875] "deg" Vector__XXX
 SG_ EngnClndr13AvrgCntrOfCmstnTmng : 32|16@1+ (0.0078125,-250) [-250|251.9921875] "deg" Vector__XXX

BO_ 2498780158 ECCAI14: 8 Vector__XXX
 SG_ EngnClndr14AvrgCmstnDrtn : 48|16@1+ (0.0078125,0) [0|501.9921875] "deg" Vector__XXX
 SG_ EngnClndr14IndtdMnEfftvPrssr : 0|16@1+ (0.0001220703125,-1) [-1|6.8436279296875] "MPa" Vector__XXX
 SG_ EngnClndr14AvrgStrtOfCmstnTmng : 16|16@1+ (0.0078125,-250) [-250|251.9921875] "deg" Vector__XXX
 SG_ EngnClndr14AvrgCntrOfCmstnTmng : 32|16@1+ (0.0078125,-250) [-250|251.9921875] "deg" Vector__XXX

BO_ 2498780414 ECCAI15: 8 Vector__XXX
 SG_ EngnClndr15AvrgCmstnDrtn : 48|16@1+ (0.0078125,0) [0|501.9921875] "deg" Vector__XXX
 SG_ EngnClndr15IndtdMnEfftvPrssr : 0|16@1+ (0.0001220703125,-1) [-1|6.8436279296875] "MPa" Vector__XXX
 SG_ EngnClndr15AvrgStrtOfCmstnTmng : 16|16@1+ (0.0078125,-250) [-250|251.9921875] "deg" Vector__XXX
 SG_ EngnClndr15AvrgCntrOfCmstnTmng : 32|16@1+ (0.0078125,-250) [-250|251.9921875] "deg" Vector__XXX

BO_ 2498780670 ECCAI16: 8 Vector__XXX
 SG_ EngnClndr16AvrgCmstnDrtn : 48|16@1+ (0.0078125,0) [0|501.9921875] "deg" Vector__XXX
 SG_ EngnClndr16IndtdMnEfftvPrssr : 0|16@1+ (0.0001220703125,-1) [-1|6.8436279296875] "MPa" Vector__XXX
 SG_ EngnClndr16AvrgStrtOfCmstnTmng : 16|16@1+ (0.0078125,-250) [-250|251.9921875] "deg" Vector__XXX
 SG_ EngnClndr16AvrgCntrOfCmstnTmng : 32|16@1+ (0.0078125,-250) [-250|251.9921875] "deg" Vector__XXX

BO_ 2498780926 ECCAI17: 8 Vector__XXX
 SG_ EngnClndr17AvrgCmstnDrtn : 48|16@1+ (0.0078125,0) [0|501.9921875] "deg" Vector__XXX
 SG_ EngnClndr17IndtdMnEfftvPrssr : 0|16@1+ (0.0001220703125,-1) [-1|6.8436279296875] "MPa" Vector__XXX
 SG_ EngnClndr17AvrgStrtOfCmstnTmng : 16|16@1+ (0.0078125,-250) [-250|251.9921875] "deg" Vector__XXX
 SG_ EngnClndr17AvrgCntrOfCmstnTmng : 32|16@1+ (0.0078125,-250) [-250|251.9921875] "deg" Vector__XXX

BO_ 2498781182 ECCAI18: 8 Vector__XXX
 SG_ EngnClndr18AvrgCmstnDrtn : 48|16@1+ (0.0078125,0) [0|501.9921875] "deg" Vector__XXX
 SG_ EngnClndr18IndtdMnEfftvPrssr : 0|16@1+ (0.0001220703125,-1) [-1|6.8436279296875] "MPa" Vector__XXX
 SG_ EngnClndr18AvrgStrtOfCmstnTmng : 16|16@1+ (0.0078125,-250) [-250|251.9921875] "deg" Vector__XXX
 SG_ EngnClndr18AvrgCntrOfCmstnTmng : 32|16@1+ (0.0078125,-250) [-250|251.9921875] "deg" Vector__XXX

BO_ 2498781438 ECCAI19: 8 Vector__XXX
 SG_ EngnClndr19AvrgCmstnDrtn : 48|16@1+ (0.0078125,0) [0|501.9921875] "deg" Vector__XXX
 SG_ EngnClndr19IndtdMnEfftvPrssr : 0|16@1+ (0.0001220703125,-1) [-1|6.8436279296875] "MPa" Vector__XXX
 SG_ EngnClndr19AvrgStrtOfCmstnTmng : 16|16@1+ (0.0078125,-250) [-250|251.9921875] "deg" Vector__XXX
 SG_ EngnClndr19AvrgCntrOfCmstnTmng : 32|16@1+ (0.0078125,-250) [-250|251.9921875] "deg" Vector__XXX

BO_ 2498781694 ECCAI20: 8 Vector__XXX
 SG_ EngnClndr20AvrgCmstnDrtn : 48|16@1+ (0.0078125,0) [0|501.9921875] "deg" Vector__XXX
 SG_ EngnClndr20IndtdMnEfftvPrssr : 0|16@1+ (0.0001220703125,-1) [-1|6.8436279296875] "MPa" Vector__XXX
 SG_ EngnClndr20AvrgStrtOfCmstnTmng : 16|16@1+ (0.0078125,-250) [-250|251.9921875] "deg" Vector__XXX
 SG_ EngnClndr20AvrgCntrOfCmstnTmng : 32|16@1+ (0.0078125,-250) [-250|251.9921875] "deg" Vector__XXX

BO_ 2498825982 DTBI1: 8 Vector__XXX
 SG_ DmpBdRsPstnRltvTRmmnddMxmm : 32|16@1+ (0.005,-150) [-150|171.275] "%" Vector__XXX
 SG_ DumpBodyEjectorBladePosition : 48|8@1+ (0.4,0) [0|100] "%" Vector__XXX
 SG_ DumpBodyRaiseAngle : 16|16@1+ (0.0078125,-200) [-200|301.9921875] "deg" Vector__XXX
 SG_ DumpBodyRollAngle : 0|16@1+ (0.0078125,-200) [-200|301.9921875] "deg" Vector__XXX

BO_ 2499547902 CDC1: 8 Vector__XXX
 SG_ CabDoorsLockActuationCommand : 0|3@1+ (1,0) [0|7] "" Vector__XXX
 SG_ LeftFrontWindowPositionCommand : 16|3@1+ (1,0) [0|7] "" Vector__XXX
 SG_ LeftRearWindowPositionCommand : 24|3@1+ (1,0) [0|7] "" Vector__XXX
 SG_ MirrorLeft1HeatCommand : 48|2@1+ (1,0) [0|3] "" Vector__XXX
 SG_ MirrorLeft1HorizontalCommand : 32|2@1+ (1,0) [0|3] "" Vector__XXX
 SG_ MirrorLeft1VerticalCommand : 34|2@1+ (1,0) [0|3] "" Vector__XXX
 SG_ MirrorLeft2HeatCommand : 52|2@1+ (1,0) [0|3] "" Vector__XXX
 SG_ MirrorLeft2HorizontalCommand : 40|2@1+ (1,0) [0|3] "" Vector__XXX
 SG_ MirrorLeft2VerticalCommand : 42|2@1+ (1,0) [0|3] "" Vector__XXX
 SG_ MirrorRight1HeatCommand : 50|2@1+ (1,0) [0|3] "" Vector__XXX
 SG_ MirrorRight1HorizontalCommand : 36|2@1+ (1,0) [0|3] "" Vector__XXX
 SG_ MirrorRight1VerticalCommand : 38|2@1+ (1,0) [0|3] "" Vector__XXX
 SG_ MirrorRight2HeatCommand : 54|2@1+ (1,0) [0|3] "" Vector__XXX
 SG_ MirrorRight2HorizontalCommand : 44|2@1+ (1,0) [0|3] "" Vector__XXX
 SG_ MirrorRight2VerticalCommand : 46|2@1+ (1,0) [0|3] "" Vector__XXX
 SG_ RemoteCabDoorLockRequest : 8|3@1+ (1,0) [0|7] "" Vector__XXX
 SG_ RightFrontWindowPositionCommand : 19|3@1+ (1,0) [0|7] "" Vector__XXX
 SG_ RightRearWindowPositionCommand : 27|3@1+ (1,0) [0|7] "" Vector__XXX
 SG_ MirrorFoldingSwitch : 22|2@1+ (1,0) [0|3] "" Vector__XXX
 SG_ MirrorAutoPanningEnable : 30|2@1+ (1,0) [0|3] "" Vector__XXX

BO_ 2499548158 DLS: 8 Vector__XXX
 SG_ LeftFrontCabDoorLatchPosition : 0|3@1+ (1,0) [0|7] "" Vector__XXX
 SG_ LeftRearCabDoorLatchPosition : 16|3@1+ (1,0) [0|7] "" Vector__XXX
 SG_ RightFrontCabDoorLatchPosition : 8|3@1+ (1,0) [0|7] "" Vector__XXX
 SG_ RightRearCabDoorLatchPosition : 24|3@1+ (1,0) [0|7] "" Vector__XXX

BO_ 2499548670 VEP6: 8 Vector__XXX
 SG_ BatteryPotentialPowerInput3 : 0|16@1+ (0.05,0) [0|3212.75] "V" Vector__XXX
 SG_ BatteryPotentialPowerInput4 : 16|16@1+ (0.05,0) [0|3212.75] "V" Vector__XXX
 SG_ SliBattery3NetCurrent : 32|16@1+ (0.05,-1600) [-1600|1612.75] "A" Vector__XXX
 SG_ SliBattery4NetCurrent : 48|16@1+ (0.05,-1600) [-1600|1612.75] "A" Vector__XXX

BO_ 2499548926 PLT2: 8 Vector__XXX
 SG_ PayloadTemperature5 : 0|16@1+ (0.03125,-273) [-40|250] "degC" Vector__XXX

BO_ 2499549182 PLT1: 8 Vector__XXX
 SG_ PayloadTemperature1 : 0|16@1+ (0.03125,-273) [-40|250] "degC" Vector__XXX
 SG_ PayloadTemperature2 : 16|16@1+ (0.03125,-273) [-40|250] "degC" Vector__XXX
 SG_ PayloadTemperature3 : 32|16@1+ (0.03125,-273) [-40|250] "degC" Vector__XXX
 SG_ PayloadTemperature4 : 48|16@1+ (0.03125,-273) [-40|250] "degC" Vector__XXX

BO_ 2499556094 AFT1PSI3: 8 Vector__XXX
 SG_ Atttt1PttSsHtHSdDvDstStts : 5|3@1+ (1,0) [0|7] "" Vector__XXX
 SG_ Atttt1PttSsHtLwSdDvDstStts : 13|3@1+ (1,0) [0|7] "" Vector__XXX
 SG_ Atttt1PttSsHtPwSppDstStts : 37|3@1+ (1,0) [0|7] "" Vector__XXX
 SG_ Atttt1PttSsIptDstStts : 21|3@1+ (1,0) [0|7] "" Vector__XXX
 SG_ Atttt1PttSsPwSppDstStts : 29|3@1+ (1,0) [0|7] "" Vector__XXX
 SG_ Atttt1PttSsHtHSdDvPF : 0|5@1+ (1,0) [0|31] "" Vector__XXX
 SG_ Atttt1PttSsHtLwSdDvPF : 8|5@1+ (1,0) [0|31] "" Vector__XXX
 SG_ Atttt1PttSsIptPF : 16|5@1+ (1,0) [0|31] "" Vector__XXX
 SG_ Atttt1PttSsPwSppPF : 24|5@1+ (1,0) [0|31] "" Vector__XXX
 SG_ Atttt1PttSsHtPwSppPF : 32|5@1+ (1,0) [0|31] "" Vector__XXX

BO_ 2499556350 EFIMRPI3: 8 Vector__XXX
 SG_ EngnFl1InjtrMtrngRl1DsrdPrssr : 0|16@1+ (5,0) [0|321275] "kPa" Vector__XXX
 SG_ EngnFl1InjtrMtrngRl2DsrdPrssr : 16|16@1+ (5,0) [0|321275] "kPa" Vector__XXX

BO_ 2499556606 EFIMRPI2: 8 Vector__XXX
 SG_ EF1ItMtR1Pss1ExtddR : 0|16@1+ (5,0) [0|321275] "kPa" Vector__XXX
 SG_ EF1ItMtR1Pss2ExtddR : 16|16@1+ (5,0) [0|321275] "kPa" Vector__XXX
 SG_ EF1ItMtR2Pss1ExtddR : 32|16@1+ (5,0) [0|321275] "kPa" Vector__XXX
 SG_ EF1ItMtR2Pss2ExtddR : 48|16@1+ (5,0) [0|321275] "kPa" Vector__XXX

BO_ 2499557118 GFSVI: 8 Vector__XXX
 SG_ EngnGssFlSpplBldVlv1Pstn : 16|8@1+ (0.4,0) [0|100] "%" Vector__XXX
 SG_ EngnGssFlSpplBldVlv2Pstn : 24|8@1+ (0.4,0) [0|100] "%" Vector__XXX
 SG_ EngnGssFlSpplBldVlv3Pstn : 32|8@1+ (0.4,0) [0|100] "%" Vector__XXX
 SG_ EngnGssFlSpplShtffVlv1Pstn : 0|8@1+ (0.4,0) [0|100] "%" Vector__XXX
 SG_ EngnGssFlSpplShtffVlv2Pstn : 8|8@1+ (0.4,0) [0|100] "%" Vector__XXX
 SG_ InertGasSupplyValvePosition : 40|8@1+ (0.4,0) [0|100] "%" Vector__XXX

BO_ 2499557374 EOMDI2: 8 Vector__XXX
 SG_ EngineOilMist10Concentration : 8|8@1+ (1,0) [0|250] "%" Vector__XXX
 SG_ EngineOilMist9Concentration : 0|8@1+ (1,0) [0|250] "%" Vector__XXX

BO_ 2499557630 EOMDI1: 8 Vector__XXX
 SG_ EngineOilMist1Concentration : 0|8@1+ (1,0) [0|250] "%" Vector__XXX
 SG_ EngineOilMist2Concentration : 8|8@1+ (1,0) [0|250] "%" Vector__XXX
 SG_ EngineOilMist3Concentration : 16|8@1+ (1,0) [0|250] "%" Vector__XXX
 SG_ EngineOilMist4Concentration : 24|8@1+ (1,0) [0|250] "%" Vector__XXX
 SG_ EngineOilMist5Concentration : 32|8@1+ (1,0) [0|250] "%" Vector__XXX
 SG_ EngineOilMist6Concentration : 40|8@1+ (1,0) [0|250] "%" Vector__XXX
 SG_ EngineOilMist7Concentration : 48|8@1+ (1,0) [0|250] "%" Vector__XXX
 SG_ EngineOilMist8Concentration : 56|8@1+ (1,0) [0|250] "%" Vector__XXX

BO_ 2499557886 GFSP2: 8 Vector__XXX
 SG_ PlntGssFlSpplOtltPrssr : 0|16@1+ (0.5,0) [0|32127.5] "kPa" Vector__XXX
 SG_ PlntInrtGsSpplOtltPrssr : 16|16@1+ (0.5,0) [0|32127.5] "kPa" Vector__XXX

BO_ 2499558142 GFSP1: 8 Vector__XXX
 SG_ EngnGssFlSpplPrssr2 : 0|16@1+ (0.5,0) [0|32127.5] "kPa" Vector__XXX
 SG_ EngnGssFlSpplShtffVlv1IntkPrssr : 32|16@1+ (0.5,0) [0|32127.5] "kPa" Vector__XXX
 SG_ EngnGssFlSpplShtffVlv2IntkPrssr : 48|16@1+ (0.5,0) [0|32127.5] "kPa" Vector__XXX
 SG_ EngnGssFlSpplUntIntkPrssr : 16|16@1+ (0.5,0) [0|32127.5] "kPa" Vector__XXX

BO_ 2499580158 EFIMRPI1: 8 Vector__XXX
 SG_ EngnFl1InjtrMtrngRl1Prssr1 : 0|16@1+ (0.00390625,0) [0|250.99609375] "MPa" Vector__XXX
 SG_ EngnFl1InjtrMtrngRl1Prssr2 : 16|16@1+ (0.00390625,0) [0|250.99609375] "MPa" Vector__XXX
 SG_ EngnFl1InjtrMtrngRl2Prssr1 : 32|16@1+ (0.00390625,0) [0|250.99609375] "MPa" Vector__XXX
 SG_ EngnFl1InjtrMtrngRl2Prssr2 : 48|16@1+ (0.00390625,0) [0|250.99609375] "MPa" Vector__XXX

BO_ 2499582206 VSL: 8 Vector__XXX
 SG_ SftTpSpdLmtRmnngCntnsIntrvlDstn : 40|16@1+ (1,0) [0|64255] "km" Vector__XXX
 SG_ SftTpSpdLmtRmnngDstn : 8|16@1+ (1,0) [0|64255] "km" Vector__XXX
 SG_ SoftTopRatioLimitExceeded : 2|2@1+ (1,0) [0|3] "" Vector__XXX
 SG_ SoftTopSpeedLimitActive : 0|2@1+ (1,0) [0|3] "" Vector__XXX
 SG_ SoftTopSpeedLimitResetDistance : 24|16@1+ (1,0) [0|64255] "km" Vector__XXX

BO_ 2499583486 ETAPC: 8 Vector__XXX
 SG_ EngnTmngAttr1PstnCmmnd : 0|3@1+ (1,0) [0|7] "" Vector__XXX
 SG_ EngnTmngAttr2PstnCmmnd : 3|3@1+ (1,0) [0|7] "" Vector__XXX

BO_ 2499583742 ETAP: 8 Vector__XXX
 SG_ EngineTimingActuator1 : 0|3@1+ (1,0) [0|7] "" Vector__XXX
 SG_ EngineTimingActuator2 : 3|3@1+ (1,0) [0|7] "" Vector__XXX
 SG_ EngnTmngAttr1RqstdPstn : 8|3@1+ (1,0) [0|7] "" Vector__XXX
 SG_ EngnTmngAttr2RqstdPstn : 11|3@1+ (1,0) [0|7] "" Vector__XXX

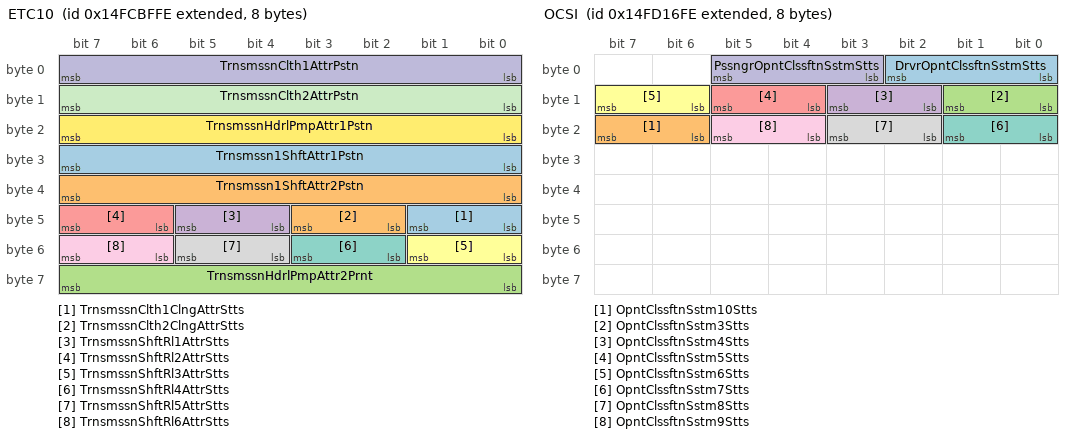
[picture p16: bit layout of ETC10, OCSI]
BO_ 2499592190 ETC10: 8 Vector__XXX
 SG_ TrnsmssnClth1ClngAttrStts : 40|2@1+ (1,0) [0|3] "" Vector__XXX
 SG_ TrnsmssnClth2ClngAttrStts : 42|2@1+ (1,0) [0|3] "" Vector__XXX
 SG_ TrnsmssnHdrlPmpAttr2Prnt : 56|8@1+ (0.4,0) [0|100] "%" Vector__XXX
 SG_ TrnsmssnShftRl1AttrStts : 44|2@1+ (1,0) [0|3] "" Vector__XXX
 SG_ TrnsmssnShftRl2AttrStts : 46|2@1+ (1,0) [0|3] "" Vector__XXX
 SG_ TrnsmssnShftRl3AttrStts : 48|2@1+ (1,0) [0|3] "" Vector__XXX
 SG_ TrnsmssnShftRl4AttrStts : 50|2@1+ (1,0) [0|3] "" Vector__XXX
 SG_ TrnsmssnShftRl5AttrStts : 52|2@1+ (1,0) [0|3] "" Vector__XXX
 SG_ TrnsmssnShftRl6AttrStts : 54|2@1+ (1,0) [0|3] "" Vector__XXX
 SG_ TrnsmssnClth1AttrPstn : 0|8@1+ (0.4,0) [0|100] "%" Vector__XXX
 SG_ TrnsmssnClth2AttrPstn : 8|8@1+ (0.4,0) [0|100] "%" Vector__XXX
 SG_ TrnsmssnHdrlPmpAttr1Pstn : 16|8@1+ (0.4,0) [0|100] "%" Vector__XXX
 SG_ Trnsmssn1ShftAttr1Pstn : 24|8@1+ (0.4,0) [0|100] "%" Vector__XXX
 SG_ Trnsmssn1ShftAttr2Pstn : 32|8@1+ (0.4,0) [0|100] "%" Vector__XXX

BO_ 2499592446 ETC11: 8 Vector__XXX
 SG_ TransmissionShiftRail1Position : 0|8@1+ (0.4,0) [0|100] "%" Vector__XXX
 SG_ TransmissionShiftRail2Position : 8|8@1+ (0.4,0) [0|100] "%" Vector__XXX
 SG_ TransmissionShiftRail3Position : 16|8@1+ (0.4,0) [0|100] "%" Vector__XXX
 SG_ TransmissionShiftRail4Position : 24|8@1+ (0.4,0) [0|100] "%" Vector__XXX
 SG_ TransmissionShiftRail5Position : 32|8@1+ (0.4,0) [0|100] "%" Vector__XXX
 SG_ TransmissionShiftRail6Position : 40|8@1+ (0.4,0) [0|100] "%" Vector__XXX

BO_ 2499604222 LLRE: 8 Vector__XXX
 SG_ BladeElevationDeviationLeft : 0|16@1+ (1,-32000) [-32000|32255] "mm" Vector__XXX
 SG_ BladeElevationDeviationRight : 16|16@1+ (1,-32000) [-32000|32255] "mm" Vector__XXX
 SG_ BldRfrnElvtnOffstLft : 32|16@1+ (1,-32000) [-32000|32255] "mm" Vector__XXX
 SG_ BldRfrnElvtnOffstRght : 48|16@1+ (1,-32000) [-32000|32255] "mm" Vector__XXX

BO_ 2499604478 EFLP11: 8 Vector__XXX
 SG_ EExstGsRt1OttAstPssHRst : 16|16@1+ (0.1,0) [0|6425.5] "kPa" Vector__XXX
 SG_ EFDvPssHRstExtddR : 48|16@1+ (0.1,0) [0|6425.5] "kPa" Vector__XXX
 SG_ EngnExhstGsRrltn1IntkAsltPrssr : 0|16@1+ (0.1,0) [0|6425.5] "kPa" Vector__XXX
 SG_ EngnOlPrssrHghRsltnExtnddRng : 32|16@1+ (0.1,0) [0|6425.5] "kPa" Vector__XXX

BO_ 2499607550 EMAP: 8 Vector__XXX
 SG_ EExstMdB1FwBVvAttPst : 0|16@1+ (0.0025,0) [0|160.6375] "%" Vector__XXX
 SG_ EExstMdB2FwBVvAttPst : 16|16@1+ (0.0025,0) [0|160.6375] "%" Vector__XXX

BO_ 2499614462 OCSI: 8 Vector__XXX
 SG_ DrvrOpntClssftnSstmStts : 0|3@1+ (1,0) [0|7] "" Vector__XXX
 SG_ OpntClssftnSstm10Stts : 22|2@1+ (1,0) [0|3] "" Vector__XXX
 SG_ OpntClssftnSstm3Stts : 8|2@1+ (1,0) [0|3] "" Vector__XXX
 SG_ OpntClssftnSstm4Stts : 10|2@1+ (1,0) [0|3] "" Vector__XXX
 SG_ OpntClssftnSstm5Stts : 12|2@1+ (1,0) [0|3] "" Vector__XXX
 SG_ OpntClssftnSstm6Stts : 14|2@1+ (1,0) [0|3] "" Vector__XXX
 SG_ OpntClssftnSstm7Stts : 16|2@1+ (1,0) [0|3] "" Vector__XXX
 SG_ OpntClssftnSstm8Stts : 18|2@1+ (1,0) [0|3] "" Vector__XXX
 SG_ OpntClssftnSstm9Stts : 20|2@1+ (1,0) [0|3] "" Vector__XXX
 SG_ PssngrOpntClssftnSstmStts : 3|3@1+ (1,0) [0|7] "" Vector__XXX

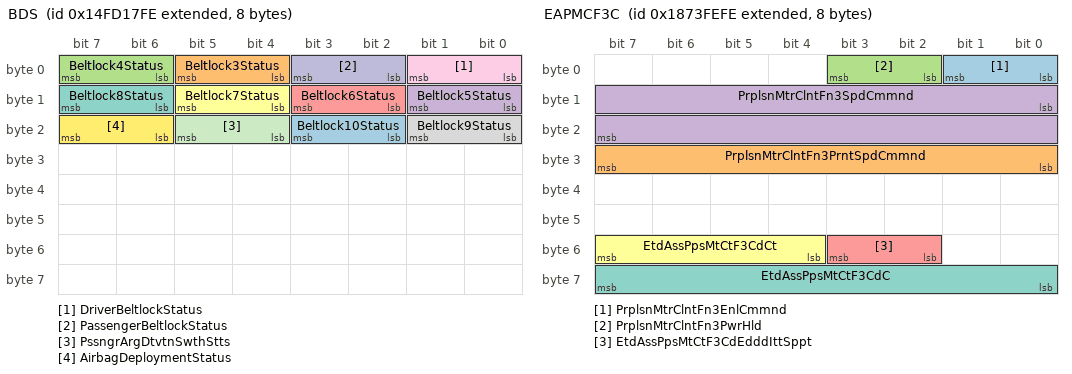
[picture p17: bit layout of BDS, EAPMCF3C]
BO_ 2499614718 BDS: 8 Vector__XXX
 SG_ Beltlock10Status : 18|2@1+ (1,0) [0|3] "" Vector__XXX
 SG_ Beltlock3Status : 4|2@1+ (1,0) [0|3] "" Vector__XXX
 SG_ Beltlock4Status : 6|2@1+ (1,0) [0|3] "" Vector__XXX
 SG_ Beltlock5Status : 8|2@1+ (1,0) [0|3] "" Vector__XXX
 SG_ Beltlock6Status : 10|2@1+ (1,0) [0|3] "" Vector__XXX
 SG_ Beltlock7Status : 12|2@1+ (1,0) [0|3] "" Vector__XXX
 SG_ Beltlock8Status : 14|2@1+ (1,0) [0|3] "" Vector__XXX
 SG_ Beltlock9Status : 16|2@1+ (1,0) [0|3] "" Vector__XXX
 SG_ DriverBeltlockStatus : 0|2@1+ (1,0) [0|3] "" Vector__XXX
 SG_ PassengerBeltlockStatus : 2|2@1+ (1,0) [0|3] "" Vector__XXX
 SG_ PssngrArgDtvtnSwthStts : 20|2@1+ (1,0) [0|3] "" Vector__XXX
 SG_ AirbagDeploymentStatus : 22|2@1+ (1,0) [0|3] "" Vector__XXX

BO_ 2499624702 A1SCREGT1: 8 Vector__XXX
 SG_ Aftrtrtmnt1SrIntkTmprtr : 0|16@1+ (0.03125,-273) [-273|1734.96875] "degC" Vector__XXX
 SG_ Aftrtrtmnt1SrIntkTmprtrPrlmnrFm : 16|5@1+ (1,0) [0|31] "" Vector__XXX
 SG_ Aftrtrtmnt1SrOtltTmprtr : 24|16@1+ (0.03125,-273) [-273|1734.96875] "degC" Vector__XXX
 SG_ Aftrtrtmnt1SrOtltTmprtrPrlmnrFm : 40|5@1+ (1,0) [0|31] "" Vector__XXX

BO_ 2499630078 EAI: 8 Vector__XXX
 SG_ EngineExhaustTemperatureAverage : 0|16@1+ (0.03125,-273) [-273|1734.96875] "degC" Vector__XXX
 SG_ EngnExhstBnk1TmprtrAvrg : 16|16@1+ (0.03125,-273) [-273|1734.96875] "degC" Vector__XXX
 SG_ EngnExhstBnk2TmprtrAvrg : 32|16@1+ (0.03125,-273) [-273|1734.96875] "degC" Vector__XXX

BO_ 2499635454 GCVW: 8 Vector__XXX
 SG_ GrossCombinationWeight : 0|24@1+ (2,0) [0|32899070] "kg" Vector__XXX
 SG_ NetVehicleWeightChange : 24|24@1+ (2,-16449535) [-16449535|16449535] "kg" Vector__XXX

BO_ 2499635966 AGW: 8 Vector__XXX
 SG_ AdditionalAxleGroupLocation : 4|4@1+ (1,0) [0|15] "" Vector__XXX
 SG_ AxleGroupLocation : 0|4@1+ (1,0) [0|15] "" Vector__XXX
 SG_ AxleGroupWeight : 8|16@1+ (2,0) [0|128510] "kg" Vector__XXX

BO_ 2499641854 EGRBV: 8 Vector__XXX
 SG_ EExstGsRt1CBpssAttPst : 0|8@1+ (0.4,0) [0|100] "%" Vector__XXX

BO_ 2550660862 GPV4: 8 Vector__XXX
 SG_ ValveAssemblyLoadSensePressure : 24|16@1+ (5,0) [0|321275] "kPa" Vector__XXX
 SG_ ValveAssemblySupplyPressure : 40|16@1+ (5,0) [0|321275] "kPa" Vector__XXX
 SG_ ValveLoadSensePressure : 0|16@1+ (5,0) [0|321275] "kPa" Vector__XXX
 SG_ ValvePilotPressure : 16|8@1+ (16,0) [0|4000] "kPa" Vector__XXX
 SG_ ValvePilotPressureSwitch : 56|2@1+ (1,0) [0|3] "" Vector__XXX

BO_ 2550988542 EEC16: 8 Vector__XXX
 SG_ EngineClutchEngageRequestStatus : 10|2@1+ (1,0) [0|3] "" Vector__XXX
 SG_ ReadyForClutchEngagementStatus : 8|2@1+ (1,0) [0|3] "" Vector__XXX
 SG_ AcceleratorPedal3Position : 0|8@1+ (0.4,0) [0|100] "%" Vector__XXX

BO_ 2557214462 WSPSCC: 8 Vector__XXX
 SG_ WSttPpDsPssCtStPtCd : 8|4@1+ (1,0) [0|15] "" Vector__XXX
 SG_ WSttPpStPssCtStPtCd : 0|4@1+ (1,0) [0|15] "" Vector__XXX

BO_ 2557345534 WSPT1: 19 Vector__XXX
 SG_ WllStmltnPmpPlngrFrngOrdr : 144|4@1+ (1,0) [0|15] "" Vector__XXX
 SG_ WllStmltnPmpRdLdHghThrshld : 128|16@1+ (5,0) [0|321275] "kN" Vector__XXX
 SG_ WllStmltnPmpStnPrssrHghThrshld : 64|16@1+ (0.1,-3212.7) [-3212.7|3212.8] "kPa" Vector__XXX
 SG_ WllStmltnPmpStnPrssrLwThrshld : 48|16@1+ (0.1,-3212.7) [-3212.7|3212.8] "kPa" Vector__XXX
 SG_ WSttPpCstSpdHTsd : 112|16@1+ (0.125,0) [0|8031.875] "rpm" Vector__XXX
 SG_ WSttPpCstSpdLwTsd : 96|16@1+ (0.125,0) [0|8031.875] "rpm" Vector__XXX
 SG_ WSttPpDsPssHTsd : 80|16@1+ (5,0) [0|321275] "kPa" Vector__XXX
 SG_ WSttPpGBxOPssHTsd : 16|16@1+ (0.1,0) [0|6425.5] "kPa" Vector__XXX
 SG_ WSttPpGBxOPssLwTsd : 0|16@1+ (0.1,0) [0|6425.5] "kPa" Vector__XXX
 SG_ WSttPpGBxOTptHTsd : 40|8@1+ (1,-40) [-40|210] "degC" Vector__XXX
 SG_ WSttPpGBxOTptLwTsd : 32|8@1+ (1,-40) [-40|210] "degC" Vector__XXX

BO_ 2557673214 ODMCC: 37 Vector__XXX
 SG_ OlDrsMntrCnfgrtnIdntftnNmr : 0|8@1+ (1,0) [0|250] "count" Vector__XXX
 SG_ OlDrsMntrFrrsBn1CntCmmnd : 8|24@1+ (1,0) [0|16449535] "count" Vector__XXX
 SG_ OlDrsMntrFrrsBn2CntCmmnd : 32|24@1+ (1,0) [0|16449535] "count" Vector__XXX
 SG_ OlDrsMntrFrrsBn3CntCmmnd : 56|24@1+ (1,0) [0|16449535] "count" Vector__XXX
 SG_ OlDrsMntrFrrsBn4CntCmmnd : 80|24@1+ (1,0) [0|16449535] "count" Vector__XXX
 SG_ OlDrsMntrFrrsBn5CntCmmnd : 104|24@1+ (1,0) [0|16449535] "count" Vector__XXX
 SG_ OlDrsMntrFrrsBn6CntCmmnd : 128|24@1+ (1,0) [0|16449535] "count" Vector__XXX
 SG_ OlDrsMntrNnFrrsBn1CntCmmnd : 152|24@1+ (1,0) [0|16449535] "count" Vector__XXX
 SG_ OlDrsMntrNnFrrsBn2CntCmmnd : 176|24@1+ (1,0) [0|16449535] "count" Vector__XXX
 SG_ OlDrsMntrNnFrrsBn3CntCmmnd : 200|24@1+ (1,0) [0|16449535] "count" Vector__XXX
 SG_ OlDrsMntrNnFrrsBn4CntCmmnd : 224|24@1+ (1,0) [0|16449535] "count" Vector__XXX
 SG_ OlDrsMntrNnFrrsBn5CntCmmnd : 248|24@1+ (1,0) [0|16449535] "count" Vector__XXX
 SG_ OlDrsMntrNnFrrsBn6CntCmmnd : 272|24@1+ (1,0) [0|16449535] "count" Vector__XXX

BO_ 2557738750 EAPMCF3C: 8 Vector__XXX
 SG_ PrplsnMtrClntFn3EnlCmmnd : 0|2@1+ (1,0) [0|3] "" Vector__XXX
 SG_ PrplsnMtrClntFn3PrntSpdCmmnd : 24|8@1+ (0.5,0) [0|100] "%" Vector__XXX
 SG_ PrplsnMtrClntFn3PwrHld : 2|2@1+ (1,0) [0|3] "" Vector__XXX
 SG_ PrplsnMtrClntFn3SpdCmmnd : 8|16@1+ (0.5,0) [0|32127.5] "rpm" Vector__XXX
 SG_ EtdAssPpsMtCtF3CdEdddIttSppt : 50|2@1+ (1,0) [0|3] "" Vector__XXX
 SG_ EtdAssPpsMtCtF3CdCt : 52|4@1+ (1,0) [0|15] "count" Vector__XXX
 SG_ EtdAssPpsMtCtF3CdC : 56|8@1+ (1,0) [0|250] "count" Vector__XXX

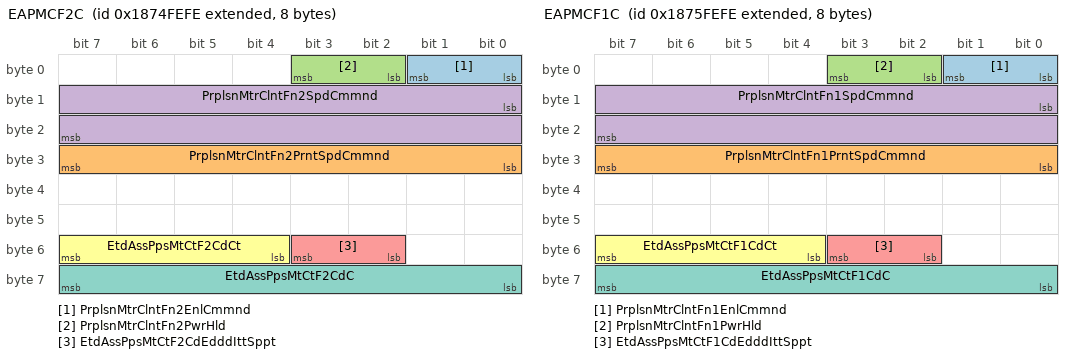
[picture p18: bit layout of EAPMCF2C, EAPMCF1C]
BO_ 2557804286 EAPMCF2C: 8 Vector__XXX
 SG_ PrplsnMtrClntFn2EnlCmmnd : 0|2@1+ (1,0) [0|3] "" Vector__XXX
 SG_ PrplsnMtrClntFn2PrntSpdCmmnd : 24|8@1+ (0.5,0) [0|100] "%" Vector__XXX
 SG_ PrplsnMtrClntFn2PwrHld : 2|2@1+ (1,0) [0|3] "" Vector__XXX
 SG_ PrplsnMtrClntFn2SpdCmmnd : 8|16@1+ (0.5,0) [0|32127.5] "rpm" Vector__XXX
 SG_ EtdAssPpsMtCtF2CdEdddIttSppt : 50|2@1+ (1,0) [0|3] "" Vector__XXX
 SG_ EtdAssPpsMtCtF2CdCt : 52|4@1+ (1,0) [0|15] "count" Vector__XXX
 SG_ EtdAssPpsMtCtF2CdC : 56|8@1+ (1,0) [0|250] "count" Vector__XXX

BO_ 2557869822 EAPMCF1C: 8 Vector__XXX
 SG_ PrplsnMtrClntFn1EnlCmmnd : 0|2@1+ (1,0) [0|3] "" Vector__XXX
 SG_ PrplsnMtrClntFn1PrntSpdCmmnd : 24|8@1+ (0.5,0) [0|100] "%" Vector__XXX
 SG_ PrplsnMtrClntFn1PwrHld : 2|2@1+ (1,0) [0|3] "" Vector__XXX
 SG_ PrplsnMtrClntFn1SpdCmmnd : 8|16@1+ (0.5,0) [0|32127.5] "rpm" Vector__XXX
 SG_ EtdAssPpsMtCtF1CdEdddIttSppt : 50|2@1+ (1,0) [0|3] "" Vector__XXX
 SG_ EtdAssPpsMtCtF1CdCt : 52|4@1+ (1,0) [0|15] "count" Vector__XXX
 SG_ EtdAssPpsMtCtF1CdC : 56|8@1+ (1,0) [0|250] "count" Vector__XXX

BO_ 2557935358 EAPECF3C: 8 Vector__XXX
 SG_ PwrEltrnsClntFn3EnlCmmnd : 0|2@1+ (1,0) [0|3] "" Vector__XXX
 SG_ PwrEltrnsClntFn3PrntSpdCmmnd : 24|8@1+ (0.5,0) [0|100] "%" Vector__XXX
 SG_ PwrEltrnsClntFn3PwrHld : 2|2@1+ (1,0) [0|3] "" Vector__XXX
 SG_ PwrEltrnsClntFn3SpdCmmnd : 8|16@1+ (0.5,0) [0|32127.5] "rpm" Vector__XXX
 SG_ EtdAssPwEtsCtF3CdEdddIttSppt : 50|2@1+ (1,0) [0|3] "" Vector__XXX
 SG_ EtdAssPwEtsCtF3CdCt : 52|4@1+ (1,0) [0|15] "count" Vector__XXX
 SG_ EtdAssPwEtsCtF3CdC : 56|8@1+ (1,0) [0|250] "count" Vector__XXX

BO_ 2558000894 EAPECF2C: 8 Vector__XXX
 SG_ PwrEltrnsClntFn2EnlCmmnd : 0|2@1+ (1,0) [0|3] "" Vector__XXX
 SG_ PwrEltrnsClntFn2PrntSpdCmmnd : 24|8@1+ (0.5,0) [0|100] "%" Vector__XXX
 SG_ PwrEltrnsClntFn2PwrHld : 2|2@1+ (1,0) [0|3] "" Vector__XXX
 SG_ PwrEltrnsClntFn2SpdCmmnd : 8|16@1+ (0.5,0) [0|32127.5] "rpm" Vector__XXX
 SG_ EtdAssPwEtsCtF2CdEdddIttSppt : 50|2@1+ (1,0) [0|3] "" Vector__XXX
 SG_ EtdAssPwEtsCtF2CdCt : 52|4@1+ (1,0) [0|15] "count" Vector__XXX
 SG_ EtdAssPwEtsCtF2CdC : 56|8@1+ (1,0) [0|250] "count" Vector__XXX

BO_ 2558066430 EAPECF1C: 8 Vector__XXX
 SG_ PwrEltrnsClntFn1EnlCmmnd : 0|2@1+ (1,0) [0|3] "" Vector__XXX
 SG_ PwrEltrnsClntFn1PrntSpdCmmnd : 24|8@1+ (0.5,0) [0|100] "%" Vector__XXX
 SG_ PwrEltrnsClntFn1PwrHld : 2|2@1+ (1,0) [0|3] "" Vector__XXX
 SG_ PwrEltrnsClntFn1SpdCmmnd : 8|16@1+ (0.5,0) [0|32127.5] "rpm" Vector__XXX
 SG_ EtdAssPwEtsCtF1CdEdddIttSppt : 50|2@1+ (1,0) [0|3] "" Vector__XXX
 SG_ EtdAssPwEtsCtF1CdCt : 52|4@1+ (1,0) [0|15] "count" Vector__XXX
 SG_ EtdAssPwEtsCtF1CdC : 56|8@1+ (1,0) [0|250] "count" Vector__XXX

BO_ 2558131966 EAPMOPC: 8 Vector__XXX
 SG_ PropulsionMotorOilPumpPowerHold : 2|2@1+ (1,0) [0|3] "" Vector__XXX
 SG_ PrplsnMtrOlPmpEnlCmmnd : 0|2@1+ (1,0) [0|3] "" Vector__XXX
 SG_ PrplsnMtrOlPmpPrntSpdCmmnd : 24|8@1+ (0.5,0) [0|100] "%" Vector__XXX
 SG_ PrplsnMtrOlPmpSpdCmmnd : 8|16@1+ (0.5,0) [0|32127.5] "rpm" Vector__XXX
 SG_ EtdAssPpsMtOPpCdEdddIttSppt : 50|2@1+ (1,0) [0|3] "" Vector__XXX
 SG_ EtdAssPpsMtOPpCdCt : 52|4@1+ (1,0) [0|15] "count" Vector__XXX
 SG_ EltrfdAssrPrplsnMtrOlPmpCmmndCr : 56|8@1+ (1,0) [0|250] "count" Vector__XXX

BO_ 2558197502 EAPMCPC: 8 Vector__XXX
 SG_ PrplsnMtrClntPmpEnlCmmnd : 0|2@1+ (1,0) [0|3] "" Vector__XXX
 SG_ PrplsnMtrClntPmpPrntSpdCmmnd : 24|8@1+ (0.5,0) [0|100] "%" Vector__XXX
 SG_ PrplsnMtrClntPmpPwrHld : 2|2@1+ (1,0) [0|3] "" Vector__XXX
 SG_ PrplsnMtrClntPmpSpdCmmnd : 8|16@1+ (0.5,0) [0|32127.5] "rpm" Vector__XXX
 SG_ EtdAssPpsMtCtPpCdEdddIttSppt : 50|2@1+ (1,0) [0|3] "" Vector__XXX
 SG_ EtdAssPpsMtCtPpCdCt : 52|4@1+ (1,0) [0|15] "count" Vector__XXX
 SG_ EtdAssPpsMtCtPpCdC : 56|8@1+ (1,0) [0|250] "count" Vector__XXX

BO_ 2558263038 EAPECPC: 8 Vector__XXX
 SG_ PwrEltrnsClntPmpEnlCmmnd : 0|2@1+ (1,0) [0|3] "" Vector__XXX
 SG_ PwrEltrnsClntPmpPrntSpdCmmnd : 24|8@1+ (0.5,0) [0|100] "%" Vector__XXX
 SG_ PwrEltrnsClntPmpPwrHld : 2|2@1+ (1,0) [0|3] "" Vector__XXX
 SG_ PwrEltrnsClntPmpSpdCmmnd : 8|16@1+ (0.5,0) [0|32127.5] "rpm" Vector__XXX
 SG_ EtdAssPwEtsCtPpCdEdddIttSppt : 50|2@1+ (1,0) [0|3] "" Vector__XXX
 SG_ EtdAssPwEtsCtPpCdCt : 52|4@1+ (1,0) [0|15] "count" Vector__XXX
 SG_ EtdAssPwEtsCtPpCdC : 56|8@1+ (1,0) [0|250] "count" Vector__XXX

BO_ 2558394110 EAMC: 8 Vector__XXX
 SG_ EltrfdAssrMtrEnlCmmnd : 0|2@1+ (1,0) [0|3] "" Vector__XXX
 SG_ EltrfdAssrMtrPrntSpdCmmnd : 24|8@1+ (0.5,0) [0|100] "%" Vector__XXX
 SG_ EltrfdAssrMtrPwrHld : 2|2@1+ (1,0) [0|3] "" Vector__XXX
 SG_ EltrfdAssrMtrSpdCmmnd : 8|16@1+ (0.5,0) [0|32127.5] "rpm" Vector__XXX
 SG_ ElectrifiedAccessoryMotor1 : 32|1@1+ (1,0) [0|1] "" Vector__XXX
 SG_ ElectrifiedAccessoryMotor2 : 33|1@1+ (1,0) [0|1] "" Vector__XXX
 SG_ ElectrifiedAccessoryMotor3 : 34|1@1+ (1,0) [0|1] "" Vector__XXX
 SG_ ElectrifiedAccessoryMotor4 : 35|1@1+ (1,0) [0|1] "" Vector__XXX
 SG_ ElectrifiedAccessoryMotor5 : 36|1@1+ (1,0) [0|1] "" Vector__XXX
 SG_ ElectrifiedAccessoryMotor6 : 37|1@1+ (1,0) [0|1] "" Vector__XXX
 SG_ ElectrifiedAccessoryMotor7 : 38|1@1+ (1,0) [0|1] "" Vector__XXX
 SG_ ElectrifiedAccessoryMotor8 : 39|1@1+ (1,0) [0|1] "" Vector__XXX
 SG_ ElectrifiedAccessoryMotor9 : 40|1@1+ (1,0) [0|1] "" Vector__XXX
 SG_ ElectrifiedAccessoryMotor10 : 41|1@1+ (1,0) [0|1] "" Vector__XXX
 SG_ ElectrifiedAccessoryMotor11 : 42|1@1+ (1,0) [0|1] "" Vector__XXX
 SG_ ElectrifiedAccessoryMotor12 : 43|1@1+ (1,0) [0|1] "" Vector__XXX
 SG_ ElectrifiedAccessoryMotor13 : 44|1@1+ (1,0) [0|1] "" Vector__XXX
 SG_ ElectrifiedAccessoryMotor14 : 45|1@1+ (1,0) [0|1] "" Vector__XXX
 SG_ ElectrifiedAccessoryMotor15 : 46|1@1+ (1,0) [0|1] "" Vector__XXX
 SG_ EtdAssMtCdEdddIttSppt : 50|2@1+ (1,0) [0|3] "" Vector__XXX
 SG_ EltrfdAssrMtrCmmndCntr : 52|4@1+ (1,0) [0|15] "count" Vector__XXX
 SG_ EltrfdAssrMtrCmmndCr : 56|8@1+ (1,0) [0|250] "count" Vector__XXX

BO_ 2558459646 ESRRBR: 8 Vector__XXX
 SG_ RqstdEngnSpdAlrtnRtLmt : 0|16@1+ (1,0) [0|64255] "rpm/s" Vector__XXX
 SG_ RqstdEngnSpdDlrtnRtLmt : 16|16@1+ (1,0) [0|64255] "rpm/s" Vector__XXX

BO_ 2558525182 TSIC: 8 Vector__XXX
 SG_ NumberOfTireSensors : 0|8@1+ (1,0) [0|250] "count" Vector__XXX
 SG_ TireLocation : 16|8@1+ (1,0) [0|250] "" Vector__XXX
 SG_ TireNumber : 8|8@1+ (1,0) [0|250] "count" Vector__XXX

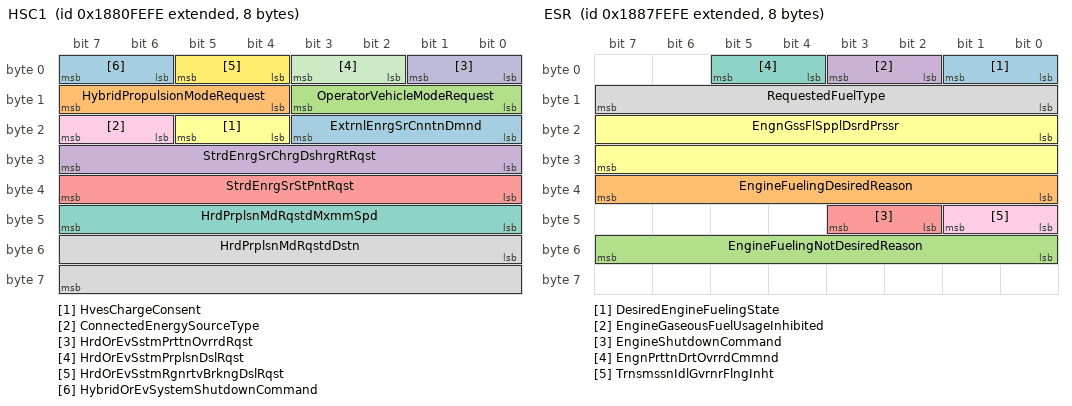
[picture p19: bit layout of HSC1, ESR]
BO_ 2558590718 HSC1: 8 Vector__XXX
 SG_ ExtrnlEnrgSrCnntnDmnd : 16|4@1+ (1,0) [0|15] "" Vector__XXX
 SG_ HybridPropulsionModeRequest : 12|4@1+ (1,0) [0|15] "" Vector__XXX
 SG_ OperatorVehicleModeRequest : 8|4@1+ (1,0) [0|15] "" Vector__XXX
 SG_ StrdEnrgSrChrgDshrgRtRqst : 24|8@1+ (0.4,0) [0|100] "%" Vector__XXX
 SG_ StrdEnrgSrStPntRqst : 32|8@1+ (0.4,0) [0|100] "%" Vector__XXX
 SG_ HvesChargeConsent : 20|2@1+ (1,0) [0|3] "" Vector__XXX
 SG_ HrdPrplsnMdRqstdMxmmSpd : 40|8@1+ (1,0) [0|250] "km/h" Vector__XXX
 SG_ HrdPrplsnMdRqstdDstn : 48|16@1+ (0.03125,0) [0|2007.96875] "km" Vector__XXX
 SG_ ConnectedEnergySourceType : 22|2@1+ (1,0) [0|3] "" Vector__XXX
 SG_ HrdOrEvSstmPrttnOvrrdRqst : 0|2@1+ (1,0) [0|3] "" Vector__XXX
 SG_ HrdOrEvSstmPrplsnDslRqst : 2|2@1+ (1,0) [0|3] "" Vector__XXX
 SG_ HrdOrEvSstmRgnrtvBrkngDslRqst : 4|2@1+ (1,0) [0|3] "" Vector__XXX
 SG_ HybridOrEvSystemShutdownCommand : 6|2@1+ (1,0) [0|3] "" Vector__XXX

BO_ 2558656254 AFTSC: 8 Vector__XXX
 SG_ AftrtrtmntDslExhstFldDsrRdStts : 10|2@1+ (1,0) [0|3] "" Vector__XXX
 SG_ AftrtrtmntSstmEnlStts : 8|2@1+ (1,0) [0|3] "" Vector__XXX
 SG_ AftrtrtmntThrmlMngmntInhtRqst : 0|2@1+ (1,0) [0|3] "" Vector__XXX
 SG_ RqstTPrmtDfHdrlStffnssChk : 2|2@1+ (1,0) [0|3] "" Vector__XXX
 SG_ RqstTPrmtSrDsngTstInjtn : 4|3@1+ (1,0) [0|7] "" Vector__XXX

BO_ 2558721790 TCCI: 8 Vector__XXX
 SG_ ColdInflationPressureSetting : 8|16@1+ (1,0) [0|64255] "kPa" Vector__XXX
 SG_ ExtrmUndrPrssrPrntgThrshldSttng : 32|8@1+ (0.5,0) [0|125] "%" Vector__XXX
 SG_ OverTemperatureSetting : 48|8@1+ (1,-40) [-40|210] "degC" Vector__XXX
 SG_ OvrPrssrPrntgThrshldSttng : 40|8@1+ (0.5,0) [0|125] "%" Vector__XXX
 SG_ TireLocation : 0|8@1+ (1,0) [0|250] "" Vector__XXX
 SG_ TireSensorEnableSetting : 56|2@1+ (1,0) [0|3] "" Vector__XXX
 SG_ UndrPrssrPrntgThrshldSttng : 24|8@1+ (0.5,0) [0|125] "%" Vector__XXX

BO_ 2558787326 PCIC: 8 Vector__XXX
 SG_ PayloadCorrectionFactorCommand : 24|8@1+ (1,-125) [-125|125] "%" Vector__XXX
 SG_ PldClrtnCmmnddWght : 8|16@1+ (2,0) [0|128510] "kg" Vector__XXX
 SG_ PldClrtnStPntCmmnd : 0|4@1+ (1,0) [0|15] "" Vector__XXX

BO_ 2558852862 AFT1PSC: 8 Vector__XXX
 SG_ Aftrtrtmnt1PrtltSnsrDwpnt : 4|2@1+ (1,0) [0|3] "" Vector__XXX
 SG_ Aftrtrtmnt1PrtltSnsrExhstTmprtr : 8|16@1+ (0.03125,-273) [-273|1734.96875] "degC" Vector__XXX
 SG_ Aftrtrtmnt1PrtltSnsrExhstVlt : 24|16@1+ (0.00390625,0) [0|250.99609375] "km/h" Vector__XXX
 SG_ Aftrtrtmnt1PrtltSnsrRgnrtnRqst : 2|2@1+ (1,0) [0|3] "" Vector__XXX
 SG_ Aftrtrtmnt1PrtltSnsrShtdwnRqst : 0|2@1+ (1,0) [0|3] "" Vector__XXX

BO_ 2558918398 CM2: 8 Vector__XXX
 SG_ ActiveShiftConsoleRequest : 52|2@1+ (1,0) [0|3] "" Vector__XXX
 SG_ AftrtrtmntSstmEnlCmmnd : 50|2@1+ (1,0) [0|3] "" Vector__XXX
 SG_ AttttRtESpdAwdSwt : 30|2@1+ (1,0) [0|3] "" Vector__XXX
 SG_ ElvtdEngnSpdAllwdSwth : 28|2@1+ (1,0) [0|3] "" Vector__XXX
 SG_ EngineFan2RequestedPercentSpeed : 0|8@1+ (0.4,0) [0|100] "%" Vector__XXX
 SG_ EngineStopStartDisableCommand : 26|2@1+ (1,0) [0|3] "" Vector__XXX
 SG_ EngnIdlMngmntPndngEvntOvrrd : 54|2@1+ (1,0) [0|3] "" Vector__XXX
 SG_ HtExhngrDrsPrgFrSwth : 20|2@1+ (1,0) [0|3] "" Vector__XXX
 SG_ HtExhngrDrsPrgInhtSwth : 18|2@1+ (1,0) [0|3] "" Vector__XXX
 SG_ PerformanceBiasSelection : 8|8@1+ (0.4,0) [0|100] "%" Vector__XXX
 SG_ PrdtvCrsCntrlDtvtnRqst : 24|2@1+ (1,0) [0|3] "" Vector__XXX
 SG_ PrdtvCrsCntrlEnlSwth : 22|2@1+ (1,0) [0|3] "" Vector__XXX
 SG_ PrdtvCrsCntrlMxmmNgtvOffst : 40|8@1+ (0.125,-31.25) [-31.25|0] "km/h" Vector__XXX
 SG_ PrdtvCrsCntrlMxmmPstvOffst : 32|8@1+ (0.125,0) [0|31.25] "km/h" Vector__XXX
 SG_ TrnsmssnAtNtrlMnlRtrnEnlSwth : 48|2@1+ (1,0) [0|3] "" Vector__XXX
 SG_ VehicleHoodSwitch : 56|2@1+ (1,0) [0|3] "" Vector__XXX
 SG_ SrOprtrIndmntOvrrdSwth : 16|2@1+ (1,0) [0|3] "" Vector__XXX

BO_ 2558983934 SPOC: 8 Vector__XXX
 SG_ SwitchedPowerOutput10Command : 20|2@1+ (1,0) [0|3] "" Vector__XXX
 SG_ SwitchedPowerOutput11Command : 18|2@1+ (1,0) [0|3] "" Vector__XXX
 SG_ SwitchedPowerOutput12Command : 16|2@1+ (1,0) [0|3] "" Vector__XXX
 SG_ SwitchedPowerOutput13Command : 30|2@1+ (1,0) [0|3] "" Vector__XXX
 SG_ SwitchedPowerOutput14Command : 28|2@1+ (1,0) [0|3] "" Vector__XXX
 SG_ SwitchedPowerOutput15Command : 26|2@1+ (1,0) [0|3] "" Vector__XXX
 SG_ SwitchedPowerOutput16Command : 24|2@1+ (1,0) [0|3] "" Vector__XXX
 SG_ SwitchedPowerOutput17Command : 38|2@1+ (1,0) [0|3] "" Vector__XXX
 SG_ SwitchedPowerOutput18Command : 36|2@1+ (1,0) [0|3] "" Vector__XXX
 SG_ SwitchedPowerOutput19Command : 34|2@1+ (1,0) [0|3] "" Vector__XXX
 SG_ SwitchedPowerOutput1Command : 6|2@1+ (1,0) [0|3] "" Vector__XXX
 SG_ SwitchedPowerOutput20Command : 32|2@1+ (1,0) [0|3] "" Vector__XXX
 SG_ SwitchedPowerOutput21Command : 46|2@1+ (1,0) [0|3] "" Vector__XXX
 SG_ SwitchedPowerOutput22Command : 44|2@1+ (1,0) [0|3] "" Vector__XXX
 SG_ SwitchedPowerOutput23Command : 42|2@1+ (1,0) [0|3] "" Vector__XXX
 SG_ SwitchedPowerOutput24Command : 40|2@1+ (1,0) [0|3] "" Vector__XXX
 SG_ SwitchedPowerOutput25Command : 54|2@1+ (1,0) [0|3] "" Vector__XXX
 SG_ SwitchedPowerOutput26Command : 52|2@1+ (1,0) [0|3] "" Vector__XXX
 SG_ SwitchedPowerOutput27Command : 50|2@1+ (1,0) [0|3] "" Vector__XXX
 SG_ SwitchedPowerOutput28Command : 48|2@1+ (1,0) [0|3] "" Vector__XXX
 SG_ SwitchedPowerOutput29Command : 62|2@1+ (1,0) [0|3] "" Vector__XXX
 SG_ SwitchedPowerOutput2Command : 4|2@1+ (1,0) [0|3] "" Vector__XXX
 SG_ SwitchedPowerOutput30Command : 60|2@1+ (1,0) [0|3] "" Vector__XXX
 SG_ SwitchedPowerOutput31Command : 58|2@1+ (1,0) [0|3] "" Vector__XXX
 SG_ SwitchedPowerOutput32Command : 56|2@1+ (1,0) [0|3] "" Vector__XXX
 SG_ SwitchedPowerOutput3Command : 2|2@1+ (1,0) [0|3] "" Vector__XXX
 SG_ SwitchedPowerOutput4Command : 0|2@1+ (1,0) [0|3] "" Vector__XXX
 SG_ SwitchedPowerOutput5Command : 14|2@1+ (1,0) [0|3] "" Vector__XXX
 SG_ SwitchedPowerOutput6Command : 12|2@1+ (1,0) [0|3] "" Vector__XXX
 SG_ SwitchedPowerOutput7Command : 10|2@1+ (1,0) [0|3] "" Vector__XXX
 SG_ SwitchedPowerOutput8Command : 8|2@1+ (1,0) [0|3] "" Vector__XXX
 SG_ SwitchedPowerOutput9Command : 22|2@1+ (1,0) [0|3] "" Vector__XXX

BO_ 2559049470 ESR: 8 Vector__XXX
 SG_ DesiredEngineFuelingState : 0|2@1+ (1,0) [0|3] "" Vector__XXX
 SG_ EngineFuelingDesiredReason : 32|8@1+ (1,0) [0|250] "" Vector__XXX
 SG_ EngineFuelingNotDesiredReason : 48|8@1+ (1,0) [0|250] "" Vector__XXX
 SG_ EngineGaseousFuelUsageInhibited : 2|2@1+ (1,0) [0|3] "" Vector__XXX
 SG_ EngineShutdownCommand : 42|2@1+ (1,0) [0|3] "" Vector__XXX
 SG_ EngnGssFlSpplDsrdPrssr : 16|16@1+ (0.5,0) [0|32127.5] "kPa" Vector__XXX
 SG_ EngnPrttnDrtOvrrdCmmnd : 4|2@1+ (1,0) [0|3] "" Vector__XXX
 SG_ RequestedFuelType : 8|8@1+ (1,0) [0|250] "" Vector__XXX
 SG_ TrnsmssnIdlGvrnrFlngInht : 40|2@1+ (1,0) [0|3] "" Vector__XXX

BO_ 2559115006 RBR: 8 Vector__XXX
 SG_ RadioBeaconDirection : 22|2@1+ (1,0) [0|3] "" Vector__XXX
 SG_ TransmitterId2 : 24|24@1+ (1,0) [0|16449535] "ID" Vector__XXX
 SG_ UnqBnMssgIdntfrNmr : 0|16@1+ (1,0) [0|64255] "count" Vector__XXX
 SG_ WirelessSignalStrength2 : 48|8@1+ (0.5,-125) [-125|0] "dBm" Vector__XXX

BO_ 2559573758 ECC: 8 Vector__XXX
 SG_ CtLvEPttStdwOvdCd : 0|2@1+ (1,0) [0|3] "" Vector__XXX

BO_ 2559639294 SFC: 8 Vector__XXX
 SG_ SupplementalFanDirectionCommand : 2|2@1+ (1,0) [0|3] "" Vector__XXX
 SG_ SupplementalFanEnableCommand : 0|2@1+ (1,0) [0|3] "" Vector__XXX
 SG_ SupplementalFanPowerHold : 24|2@1+ (1,0) [0|3] "" Vector__XXX
 SG_ SupplementalFanSpeedCommand : 8|16@1+ (0.5,0) [0|32127.5] "rpm" Vector__XXX

BO_ 2559704830 VLS1: 8 Vector__XXX
 SG_ LrtnOprtnMdStCmmnd : 5|3@1+ (1,0) [0|7] "" Vector__XXX
 SG_ LubricationCycleModeLockCommand : 0|2@1+ (1,0) [0|3] "" Vector__XXX
 SG_ LubricationCycleSetCommand : 2|3@1+ (1,0) [0|7] "" Vector__XXX
 SG_ LubricationPumpEnableCommand : 8|2@1+ (1,0) [0|3] "" Vector__XXX
 SG_ LubricationTimingCycleCommand : 10|2@1+ (1,0) [0|3] "" Vector__XXX

BO_ 2559770366 HCDI1: 8 Vector__XXX
 SG_ HydrocarbonDoserPurgingRequired : 24|2@1+ (1,0) [0|3] "" Vector__XXX
 SG_ Aftertreatment1DpfHydrocarbon : 32|8@1+ (0.5,0) [0|100] "%" Vector__XXX
 SG_ HydrocarbonDoserStatus : 16|3@1+ (1,0) [0|7] "" Vector__XXX
 SG_ HydrocarbonDoserInjectingStatus : 19|2@1+ (1,0) [0|3] "" Vector__XXX
 SG_ DgnstSttsOfHdrrnDsr : 21|3@1+ (1,0) [0|7] "" Vector__XXX
 SG_ HdrrnDsrRqstdFlMssRt : 0|16@1+ (0.05,0) [0|3212.75] "g/min" Vector__XXX

BO_ 2559901438 AT1DPFSSC: 8 Vector__XXX
 SG_ Atttt1DsPttFtStMCtOst : 0|16@1+ (0.0025,0) [0|160.6375] "%" Vector__XXX
 SG_ Atttt1DsPttFtStStddDvtCtOst : 16|16@1+ (0.0025,0) [0|160.6375] "%" Vector__XXX

BO_ 2559966974 AT2DPFSSC: 8 Vector__XXX
 SG_ Atttt2DsPttFtStMCtOst : 0|16@1+ (0.0025,0) [0|160.6375] "%" Vector__XXX
 SG_ Atttt2DsPttFtStStddDvtCtOst : 16|16@1+ (0.0025,0) [0|160.6375] "%" Vector__XXX

BO_ 2560032510 LVDSOM: 8 Vector__XXX
 SG_ LwVltgDsnntDsrdOprtngMd : 0|4@1+ (1,0) [0|15] "" Vector__XXX

BO_ 2560098046 NCS: 8 Vector__XXX
 SG_ CabNoiseControlStatus : 0|2@1+ (1,0) [0|3] "" Vector__XXX
 SG_ CabNoiseControlTuningStatus : 2|4@1+ (1,0) [0|15] "" Vector__XXX

BO_ 2560163582 NC1: 8 Vector__XXX
 SG_ CabNoiseControlCommand : 0|2@1+ (1,0) [0|3] "" Vector__XXX
 SG_ CabNoiseControlTuningCommand : 2|3@1+ (1,0) [0|7] "" Vector__XXX

BO_ 2560360190 PMI: 8 Vector__XXX
 SG_ DataDictionaryManufacturerCode : 0|11@1+ (1,0) [0|2007] "" Vector__XXX
 SG_ DataDictionaryMethod : 11|21@1+ (1,0) [0|2056191] "ID" Vector__XXX

BO_ 2560425726 AUXIO7: 8 Vector__XXX
 SG_ AuxiliaryIOChannel15 : 24|8@1+ (1,0) [0|250] "count" Vector__XXX
 SG_ AuxiliaryIOChannel16 : 16|8@1+ (1,0) [0|250] "count" Vector__XXX
 SG_ AuxiliaryIOChannel17 : 8|8@1+ (1,0) [0|250] "count" Vector__XXX
 SG_ AuxiliaryIOChannel18 : 0|8@1+ (1,0) [0|250] "count" Vector__XXX
 SG_ AuxiliaryIOChannel19 : 56|8@1+ (1,0) [0|250] "count" Vector__XXX
 SG_ AuxiliaryIOChannel20 : 48|8@1+ (1,0) [0|250] "count" Vector__XXX
 SG_ AuxiliaryIOChannel21 : 40|8@1+ (1,0) [0|250] "count" Vector__XXX
 SG_ AuxiliaryIOChannel22 : 32|8@1+ (1,0) [0|250] "count" Vector__XXX

BO_ 2560491262 AUXIO6: 8 Vector__XXX
 SG_ AuxiliaryIOChannel10 : 0|8@1+ (1,0) [0|250] "count" Vector__XXX
 SG_ AuxiliaryIOChannel11 : 56|8@1+ (1,0) [0|250] "count" Vector__XXX
 SG_ AuxiliaryIOChannel12 : 48|8@1+ (1,0) [0|250] "count" Vector__XXX
 SG_ AuxiliaryIOChannel13 : 40|8@1+ (1,0) [0|250] "count" Vector__XXX
 SG_ AuxiliaryIOChannel14 : 32|8@1+ (1,0) [0|250] "count" Vector__XXX
 SG_ AuxiliaryIOChannel7 : 24|8@1+ (1,0) [0|250] "count" Vector__XXX
 SG_ AuxiliaryIOChannel8 : 16|8@1+ (1,0) [0|250] "count" Vector__XXX
 SG_ AuxiliaryIOChannel9 : 8|8@1+ (1,0) [0|250] "count" Vector__XXX

BO_ 2561015550 AUXIO4: 8 Vector__XXX
 SG_ AuxiliaryIO100 : 32|2@1+ (1,0) [0|3] "" Vector__XXX
 SG_ AuxiliaryIO101 : 46|2@1+ (1,0) [0|3] "" Vector__XXX
 SG_ AuxiliaryIO102 : 44|2@1+ (1,0) [0|3] "" Vector__XXX
 SG_ AuxiliaryIO103 : 42|2@1+ (1,0) [0|3] "" Vector__XXX
 SG_ AuxiliaryIO104 : 40|2@1+ (1,0) [0|3] "" Vector__XXX
 SG_ AuxiliaryIO105 : 54|2@1+ (1,0) [0|3] "" Vector__XXX
 SG_ AuxiliaryIO106 : 52|2@1+ (1,0) [0|3] "" Vector__XXX
 SG_ AuxiliaryIO107 : 50|2@1+ (1,0) [0|3] "" Vector__XXX
 SG_ AuxiliaryIO108 : 48|2@1+ (1,0) [0|3] "" Vector__XXX
 SG_ AuxiliaryIO109 : 62|2@1+ (1,0) [0|3] "" Vector__XXX
 SG_ AuxiliaryIO110 : 60|2@1+ (1,0) [0|3] "" Vector__XXX
 SG_ AuxiliaryIO111 : 58|2@1+ (1,0) [0|3] "" Vector__XXX
 SG_ AuxiliaryIO112 : 56|2@1+ (1,0) [0|3] "" Vector__XXX
 SG_ AuxiliaryIO81 : 6|2@1+ (1,0) [0|3] "" Vector__XXX
 SG_ AuxiliaryIO82 : 4|2@1+ (1,0) [0|3] "" Vector__XXX
 SG_ AuxiliaryIO83 : 2|2@1+ (1,0) [0|3] "" Vector__XXX
 SG_ AuxiliaryIO84 : 0|2@1+ (1,0) [0|3] "" Vector__XXX
 SG_ AuxiliaryIO85 : 14|2@1+ (1,0) [0|3] "" Vector__XXX
 SG_ AuxiliaryIO86 : 12|2@1+ (1,0) [0|3] "" Vector__XXX
 SG_ AuxiliaryIO87 : 10|2@1+ (1,0) [0|3] "" Vector__XXX
 SG_ AuxiliaryIO88 : 8|2@1+ (1,0) [0|3] "" Vector__XXX
 SG_ AuxiliaryIO89 : 22|2@1+ (1,0) [0|3] "" Vector__XXX
 SG_ AuxiliaryIO90 : 20|2@1+ (1,0) [0|3] "" Vector__XXX
 SG_ AuxiliaryIO91 : 18|2@1+ (1,0) [0|3] "" Vector__XXX
 SG_ AuxiliaryIO92 : 16|2@1+ (1,0) [0|3] "" Vector__XXX
 SG_ AuxiliaryIO93 : 30|2@1+ (1,0) [0|3] "" Vector__XXX
 SG_ AuxiliaryIO94 : 28|2@1+ (1,0) [0|3] "" Vector__XXX
 SG_ AuxiliaryIO95 : 26|2@1+ (1,0) [0|3] "" Vector__XXX
 SG_ AuxiliaryIO96 : 24|2@1+ (1,0) [0|3] "" Vector__XXX
 SG_ AuxiliaryIO97 : 38|2@1+ (1,0) [0|3] "" Vector__XXX
 SG_ AuxiliaryIO98 : 36|2@1+ (1,0) [0|3] "" Vector__XXX
 SG_ AuxiliaryIO99 : 34|2@1+ (1,0) [0|3] "" Vector__XXX

BO_ 2561081086 AUXIO3: 8 Vector__XXX
 SG_ AuxiliaryIO49 : 6|2@1+ (1,0) [0|3] "" Vector__XXX
 SG_ AuxiliaryIO50 : 4|2@1+ (1,0) [0|3] "" Vector__XXX
 SG_ AuxiliaryIO51 : 2|2@1+ (1,0) [0|3] "" Vector__XXX
 SG_ AuxiliaryIO52 : 0|2@1+ (1,0) [0|3] "" Vector__XXX
 SG_ AuxiliaryIO53 : 14|2@1+ (1,0) [0|3] "" Vector__XXX
 SG_ AuxiliaryIO54 : 12|2@1+ (1,0) [0|3] "" Vector__XXX
 SG_ AuxiliaryIO55 : 10|2@1+ (1,0) [0|3] "" Vector__XXX
 SG_ AuxiliaryIO56 : 8|2@1+ (1,0) [0|3] "" Vector__XXX
 SG_ AuxiliaryIO57 : 22|2@1+ (1,0) [0|3] "" Vector__XXX
 SG_ AuxiliaryIO58 : 20|2@1+ (1,0) [0|3] "" Vector__XXX
 SG_ AuxiliaryIO59 : 18|2@1+ (1,0) [0|3] "" Vector__XXX
 SG_ AuxiliaryIO60 : 16|2@1+ (1,0) [0|3] "" Vector__XXX
 SG_ AuxiliaryIO61 : 30|2@1+ (1,0) [0|3] "" Vector__XXX
 SG_ AuxiliaryIO62 : 28|2@1+ (1,0) [0|3] "" Vector__XXX
 SG_ AuxiliaryIO63 : 26|2@1+ (1,0) [0|3] "" Vector__XXX
 SG_ AuxiliaryIO64 : 24|2@1+ (1,0) [0|3] "" Vector__XXX
 SG_ AuxiliaryIO65 : 38|2@1+ (1,0) [0|3] "" Vector__XXX
 SG_ AuxiliaryIO66 : 36|2@1+ (1,0) [0|3] "" Vector__XXX
 SG_ AuxiliaryIO67 : 34|2@1+ (1,0) [0|3] "" Vector__XXX
 SG_ AuxiliaryIO68 : 32|2@1+ (1,0) [0|3] "" Vector__XXX
 SG_ AuxiliaryIO69 : 46|2@1+ (1,0) [0|3] "" Vector__XXX
 SG_ AuxiliaryIO70 : 44|2@1+ (1,0) [0|3] "" Vector__XXX
 SG_ AuxiliaryIO71 : 42|2@1+ (1,0) [0|3] "" Vector__XXX
 SG_ AuxiliaryIO72 : 40|2@1+ (1,0) [0|3] "" Vector__XXX
 SG_ AuxiliaryIO73 : 54|2@1+ (1,0) [0|3] "" Vector__XXX
 SG_ AuxiliaryIO74 : 52|2@1+ (1,0) [0|3] "" Vector__XXX
 SG_ AuxiliaryIO75 : 50|2@1+ (1,0) [0|3] "" Vector__XXX
 SG_ AuxiliaryIO76 : 48|2@1+ (1,0) [0|3] "" Vector__XXX
 SG_ AuxiliaryIO77 : 62|2@1+ (1,0) [0|3] "" Vector__XXX
 SG_ AuxiliaryIO78 : 60|2@1+ (1,0) [0|3] "" Vector__XXX
 SG_ AuxiliaryIO79 : 58|2@1+ (1,0) [0|3] "" Vector__XXX
 SG_ AuxiliaryIO80 : 56|2@1+ (1,0) [0|3] "" Vector__XXX

BA_DEF_ BO_  "VFrameFormat" ENUM  "StandardCAN","ExtendedCAN","reserved","J1939PG";
BA_DEF_  "DatabaseVersion" STRING ;
BA_DEF_  "BusType" STRING ;
BA_DEF_  "ProtocolType" STRING ;
BA_DEF_  "DatabaseCompiler" STRING ;
BA_DEF_DEF_  "VFrameFormat" "J1939PG";
BA_DEF_DEF_  "DatabaseVersion" "";
BA_DEF_DEF_  "BusType" "";
BA_DEF_DEF_  "ProtocolType" "";
BA_DEF_DEF_  "DatabaseCompiler" "";
BA_ "ProtocolType" "J1939";
BA_ "BusType" "CAN";
BA_ "DatabaseCompiler" "CSS ELECTRONICS (WWW.CSSELECTRONICS.COM)";
BA_ "DatabaseVersion" "2.4";
